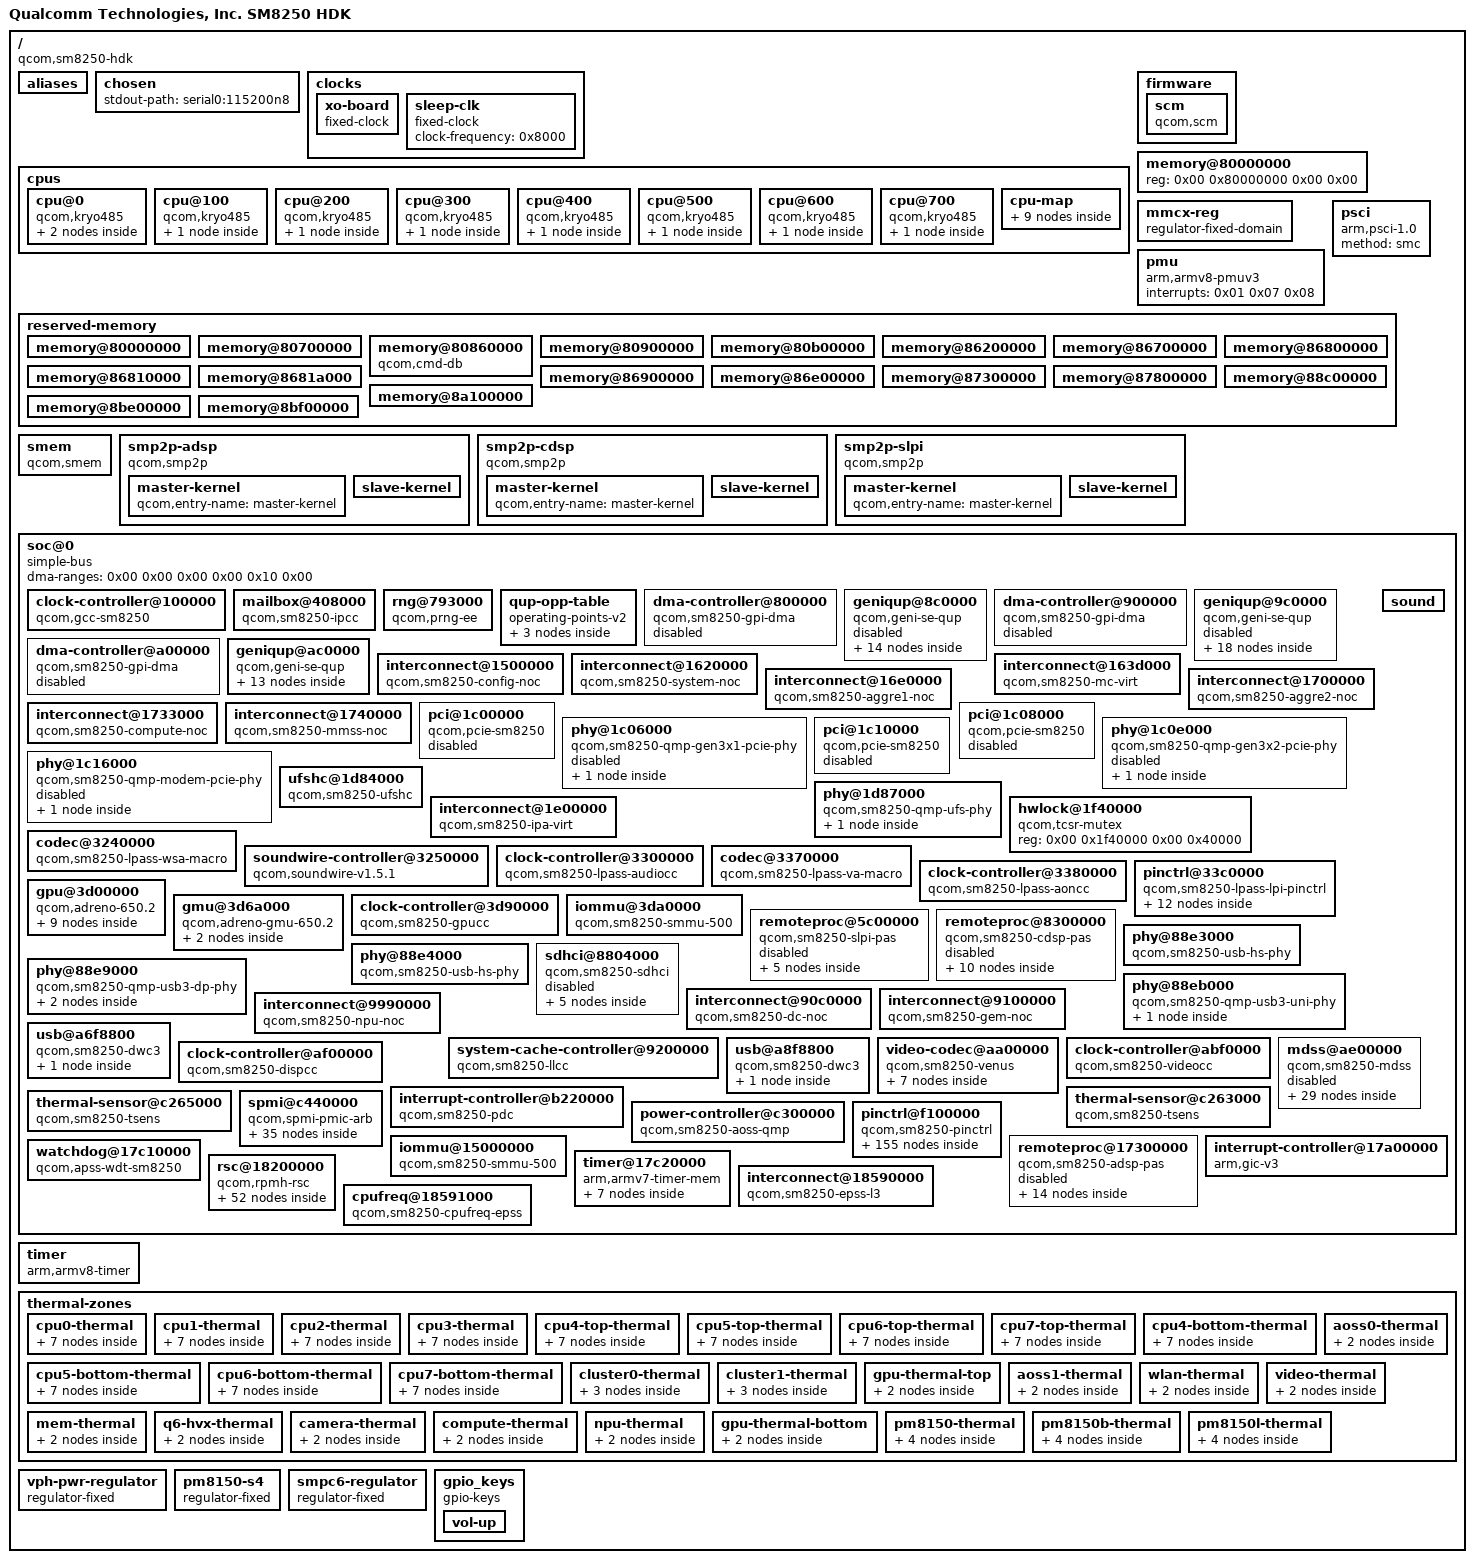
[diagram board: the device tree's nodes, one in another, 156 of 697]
/dts-v1/;

/ {
	interrupt-parent = <0x01>;
	#address-cells = <0x02>;
	#size-cells = <0x02>;
	model = "Qualcomm Technologies, Inc. SM8250 HDK";
	compatible = "qcom,sm8250-hdk\0qcom,sm8250";

	aliases {
		i2c0 = "/soc@0/geniqup@9c0000/i2c@980000";
		i2c1 = "/soc@0/geniqup@9c0000/i2c@984000";
		i2c2 = "/soc@0/geniqup@9c0000/i2c@988000";
		i2c3 = "/soc@0/geniqup@9c0000/i2c@98c000";
		i2c4 = "/soc@0/geniqup@9c0000/i2c@990000";
		i2c5 = "/soc@0/geniqup@9c0000/i2c@994000";
		i2c6 = "/soc@0/geniqup@9c0000/i2c@998000";
		i2c7 = "/soc@0/geniqup@9c0000/i2c@99c000";
		i2c8 = "/soc@0/geniqup@ac0000/i2c@a80000";
		i2c9 = "/soc@0/geniqup@ac0000/i2c@a84000";
		i2c10 = "/soc@0/geniqup@ac0000/i2c@a88000";
		i2c11 = "/soc@0/geniqup@ac0000/i2c@a8c000";
		i2c12 = "/soc@0/geniqup@ac0000/i2c@a90000";
		i2c13 = "/soc@0/geniqup@ac0000/i2c@a94000";
		i2c14 = "/soc@0/geniqup@8c0000/i2c@880000";
		i2c15 = "/soc@0/geniqup@8c0000/i2c@884000";
		i2c16 = "/soc@0/geniqup@8c0000/i2c@888000";
		i2c17 = "/soc@0/geniqup@8c0000/i2c@88c000";
		i2c18 = "/soc@0/geniqup@8c0000/i2c@890000";
		i2c19 = "/soc@0/geniqup@8c0000/i2c@894000";
		spi0 = "/soc@0/geniqup@9c0000/spi@980000";
		spi1 = "/soc@0/geniqup@9c0000/spi@984000";
		spi2 = "/soc@0/geniqup@9c0000/spi@988000";
		spi3 = "/soc@0/geniqup@9c0000/spi@98c000";
		spi4 = "/soc@0/geniqup@9c0000/spi@990000";
		spi5 = "/soc@0/geniqup@9c0000/spi@994000";
		spi6 = "/soc@0/geniqup@9c0000/spi@998000";
		spi7 = "/soc@0/geniqup@9c0000/spi@99c000";
		spi8 = "/soc@0/geniqup@ac0000/spi@a80000";
		spi9 = "/soc@0/geniqup@ac0000/spi@a84000";
		spi10 = "/soc@0/geniqup@ac0000/spi@a88000";
		spi11 = "/soc@0/geniqup@ac0000/spi@a8c000";
		spi12 = "/soc@0/geniqup@ac0000/spi@a90000";
		spi13 = "/soc@0/geniqup@ac0000/spi@a94000";
		spi14 = "/soc@0/geniqup@8c0000/spi@880000";
		spi15 = "/soc@0/geniqup@8c0000/spi@884000";
		spi16 = "/soc@0/geniqup@8c0000/spi@888000";
		spi17 = "/soc@0/geniqup@8c0000/spi@88c000";
		spi18 = "/soc@0/geniqup@8c0000/spi@890000";
		spi19 = "/soc@0/geniqup@8c0000/spi@894000";
		serial0 = "/soc@0/geniqup@ac0000/serial@a90000";
	};

	chosen {
		stdout-path = "serial0:115200n8";
	};

	clocks {

		xo-board {
			compatible = "fixed-clock";
			#clock-cells = <0x00>;
			clock-frequency = <0x249f000>;
			clock-output-names = "xo_board";
			phandle = <0x83>;
		};

		sleep-clk {
			compatible = "fixed-clock";
			clock-frequency = <0x8000>;
			#clock-cells = <0x00>;
			phandle = <0x1a>;
		};
	};

	cpus {
		#address-cells = <0x02>;
		#size-cells = <0x00>;

		cpu@0 {
			device_type = "cpu";
			compatible = "qcom,kryo485";
			reg = <0x00 0x00>;
			enable-method = "psci";
			capacity-dmips-mhz = <0x1c0>;
			dynamic-power-coefficient = <0xcd>;
			next-level-cache = <0x02>;
			qcom,freq-domain = <0x03 0x00>;
			#cooling-cells = <0x02>;
			phandle = <0x0c>;

			l2-cache {
				compatible = "cache";
				next-level-cache = <0x04>;
				phandle = <0x02>;

				l3-cache {
					compatible = "cache";
					phandle = <0x04>;
				};
			};
		};

		cpu@100 {
			device_type = "cpu";
			compatible = "qcom,kryo485";
			reg = <0x00 0x100>;
			enable-method = "psci";
			capacity-dmips-mhz = <0x1c0>;
			dynamic-power-coefficient = <0xcd>;
			next-level-cache = <0x05>;
			qcom,freq-domain = <0x03 0x00>;
			#cooling-cells = <0x02>;
			phandle = <0x0d>;

			l2-cache {
				compatible = "cache";
				next-level-cache = <0x04>;
				phandle = <0x05>;
			};
		};

		cpu@200 {
			device_type = "cpu";
			compatible = "qcom,kryo485";
			reg = <0x00 0x200>;
			enable-method = "psci";
			capacity-dmips-mhz = <0x1c0>;
			dynamic-power-coefficient = <0xcd>;
			next-level-cache = <0x06>;
			qcom,freq-domain = <0x03 0x00>;
			#cooling-cells = <0x02>;
			phandle = <0x0e>;

			l2-cache {
				compatible = "cache";
				next-level-cache = <0x04>;
				phandle = <0x06>;
			};
		};

		cpu@300 {
			device_type = "cpu";
			compatible = "qcom,kryo485";
			reg = <0x00 0x300>;
			enable-method = "psci";
			capacity-dmips-mhz = <0x1c0>;
			dynamic-power-coefficient = <0xcd>;
			next-level-cache = <0x07>;
			qcom,freq-domain = <0x03 0x00>;
			#cooling-cells = <0x02>;
			phandle = <0x0f>;

			l2-cache {
				compatible = "cache";
				next-level-cache = <0x04>;
				phandle = <0x07>;
			};
		};

		cpu@400 {
			device_type = "cpu";
			compatible = "qcom,kryo485";
			reg = <0x00 0x400>;
			enable-method = "psci";
			capacity-dmips-mhz = <0x400>;
			dynamic-power-coefficient = <0x17b>;
			next-level-cache = <0x08>;
			qcom,freq-domain = <0x03 0x01>;
			#cooling-cells = <0x02>;
			phandle = <0x10>;

			l2-cache {
				compatible = "cache";
				next-level-cache = <0x04>;
				phandle = <0x08>;
			};
		};

		cpu@500 {
			device_type = "cpu";
			compatible = "qcom,kryo485";
			reg = <0x00 0x500>;
			enable-method = "psci";
			capacity-dmips-mhz = <0x400>;
			dynamic-power-coefficient = <0x17b>;
			next-level-cache = <0x09>;
			qcom,freq-domain = <0x03 0x01>;
			#cooling-cells = <0x02>;
			phandle = <0x11>;

			l2-cache {
				compatible = "cache";
				next-level-cache = <0x04>;
				phandle = <0x09>;
			};
		};

		cpu@600 {
			device_type = "cpu";
			compatible = "qcom,kryo485";
			reg = <0x00 0x600>;
			enable-method = "psci";
			capacity-dmips-mhz = <0x400>;
			dynamic-power-coefficient = <0x17b>;
			next-level-cache = <0x0a>;
			qcom,freq-domain = <0x03 0x01>;
			#cooling-cells = <0x02>;
			phandle = <0x12>;

			l2-cache {
				compatible = "cache";
				next-level-cache = <0x04>;
				phandle = <0x0a>;
			};
		};

		cpu@700 {
			device_type = "cpu";
			compatible = "qcom,kryo485";
			reg = <0x00 0x700>;
			enable-method = "psci";
			capacity-dmips-mhz = <0x400>;
			dynamic-power-coefficient = <0x1bc>;
			next-level-cache = <0x0b>;
			qcom,freq-domain = <0x03 0x02>;
			#cooling-cells = <0x02>;
			phandle = <0x13>;

			l2-cache {
				compatible = "cache";
				next-level-cache = <0x04>;
				phandle = <0x0b>;
			};
		};

		cpu-map {

			cluster0 {

				core0 {
					cpu = <0x0c>;
				};

				core1 {
					cpu = <0x0d>;
				};

				core2 {
					cpu = <0x0e>;
				};

				core3 {
					cpu = <0x0f>;
				};

				core4 {
					cpu = <0x10>;
				};

				core5 {
					cpu = <0x11>;
				};

				core6 {
					cpu = <0x12>;
				};

				core7 {
					cpu = <0x13>;
				};
			};
		};
	};

	firmware {

		scm {
			compatible = "qcom,scm";
			#reset-cells = <0x01>;
			phandle = <0xa9>;
		};
	};

	memory@80000000 {
		device_type = "memory";
		reg = <0x00 0x80000000 0x00 0x00>;
	};

	mmcx-reg {
		compatible = "regulator-fixed-domain";
		power-domains = <0x14 0x06>;
		required-opps = <0x15>;
		regulator-name = "MMCX";
		phandle = <0x71>;
	};

	pmu {
		compatible = "arm,armv8-pmuv3";
		interrupts = <0x01 0x07 0x08>;
	};

	psci {
		compatible = "arm,psci-1.0";
		method = "smc";
	};

	reserved-memory {
		#address-cells = <0x02>;
		#size-cells = <0x02>;
		ranges;

		memory@80000000 {
			reg = <0x00 0x80000000 0x00 0x600000>;
			no-map;
			phandle = <0xaa>;
		};

		memory@80700000 {
			reg = <0x00 0x80700000 0x00 0x160000>;
			no-map;
			phandle = <0xab>;
		};

		memory@80860000 {
			compatible = "qcom,cmd-db";
			reg = <0x00 0x80860000 0x00 0x20000>;
			no-map;
			phandle = <0xac>;
		};

		memory@80900000 {
			reg = <0x00 0x80900000 0x00 0x200000>;
			no-map;
			phandle = <0x16>;
		};

		memory@80b00000 {
			reg = <0x00 0x80b00000 0x00 0x5300000>;
			no-map;
			phandle = <0xad>;
		};

		memory@86200000 {
			reg = <0x00 0x86200000 0x00 0x500000>;
			no-map;
			phandle = <0xae>;
		};

		memory@86700000 {
			reg = <0x00 0x86700000 0x00 0x100000>;
			no-map;
			phandle = <0xaf>;
		};

		memory@86800000 {
			reg = <0x00 0x86800000 0x00 0x10000>;
			no-map;
			phandle = <0xb0>;
		};

		memory@86810000 {
			reg = <0x00 0x86810000 0x00 0xa000>;
			no-map;
			phandle = <0xb1>;
		};

		memory@8681a000 {
			reg = <0x00 0x8681a000 0x00 0x2000>;
			no-map;
			phandle = <0x55>;
		};

		memory@86900000 {
			reg = <0x00 0x86900000 0x00 0x500000>;
			no-map;
			phandle = <0xb2>;
		};

		memory@86e00000 {
			reg = <0x00 0x86e00000 0x00 0x500000>;
			no-map;
			phandle = <0x6f>;
		};

		memory@87300000 {
			reg = <0x00 0x87300000 0x00 0x500000>;
			no-map;
			phandle = <0xb3>;
		};

		memory@87800000 {
			reg = <0x00 0x87800000 0x00 0x1400000>;
			no-map;
			phandle = <0x5e>;
		};

		memory@88c00000 {
			reg = <0x00 0x88c00000 0x00 0x1500000>;
			no-map;
			phandle = <0x5b>;
		};

		memory@8a100000 {
			reg = <0x00 0x8a100000 0x00 0x1d00000>;
			no-map;
			phandle = <0x81>;
		};

		memory@8be00000 {
			reg = <0x00 0x8be00000 0x00 0x100000>;
			no-map;
			phandle = <0xb4>;
		};

		memory@8bf00000 {
			reg = <0x00 0x8bf00000 0x00 0x4600000>;
			no-map;
			phandle = <0xb5>;
		};
	};

	smem {
		compatible = "qcom,smem";
		memory-region = <0x16>;
		hwlocks = <0x17 0x03>;
	};

	smp2p-adsp {
		compatible = "qcom,smp2p";
		qcom,smem = <0x1bb 0x1ad>;
		interrupts-extended = <0x18 0x03 0x02 0x01>;
		mboxes = <0x18 0x03 0x02>;
		qcom,local-pid = <0x00>;
		qcom,remote-pid = <0x02>;

		master-kernel {
			qcom,entry-name = "master-kernel";
			#qcom,smem-state-cells = <0x01>;
			phandle = <0x82>;
		};

		slave-kernel {
			qcom,entry-name = "slave-kernel";
			interrupt-controller;
			#interrupt-cells = <0x02>;
			phandle = <0x80>;
		};
	};

	smp2p-cdsp {
		compatible = "qcom,smp2p";
		qcom,smem = <0x5e 0x1b0>;
		interrupts-extended = <0x18 0x06 0x02 0x01>;
		mboxes = <0x18 0x06 0x02>;
		qcom,local-pid = <0x00>;
		qcom,remote-pid = <0x05>;

		master-kernel {
			qcom,entry-name = "master-kernel";
			#qcom,smem-state-cells = <0x01>;
			phandle = <0x5f>;
		};

		slave-kernel {
			qcom,entry-name = "slave-kernel";
			interrupt-controller;
			#interrupt-cells = <0x02>;
			phandle = <0x5d>;
		};
	};

	smp2p-slpi {
		compatible = "qcom,smp2p";
		qcom,smem = <0x1e1 0x1ae>;
		interrupts-extended = <0x18 0x04 0x02 0x01>;
		mboxes = <0x18 0x04 0x02>;
		qcom,local-pid = <0x00>;
		qcom,remote-pid = <0x03>;

		master-kernel {
			qcom,entry-name = "master-kernel";
			#qcom,smem-state-cells = <0x01>;
			phandle = <0x5c>;
		};

		slave-kernel {
			qcom,entry-name = "slave-kernel";
			interrupt-controller;
			#interrupt-cells = <0x02>;
			phandle = <0x59>;
		};
	};

	soc@0 {
		#address-cells = <0x02>;
		#size-cells = <0x02>;
		ranges = <0x00 0x00 0x00 0x00 0x10 0x00>;
		dma-ranges = <0x00 0x00 0x00 0x00 0x10 0x00>;
		compatible = "simple-bus";
		phandle = <0xb6>;

		clock-controller@100000 {
			compatible = "qcom,gcc-sm8250";
			reg = <0x00 0x100000 0x00 0x1f0000>;
			#clock-cells = <0x01>;
			#reset-cells = <0x01>;
			#power-domain-cells = <0x01>;
			clock-names = "bi_tcxo\0bi_tcxo_ao\0sleep_clk";
			clocks = <0x19 0x00 0x19 0x01 0x1a>;
			phandle = <0x1b>;
		};

		mailbox@408000 {
			compatible = "qcom,sm8250-ipcc\0qcom,ipcc";
			reg = <0x00 0x408000 0x00 0x1000>;
			interrupts = <0x00 0xe5 0x04>;
			interrupt-controller;
			#interrupt-cells = <0x03>;
			#mbox-cells = <0x02>;
			phandle = <0x18>;
		};

		rng@793000 {
			compatible = "qcom,prng-ee";
			reg = <0x00 0x793000 0x00 0x1000>;
			clocks = <0x1b 0x4f>;
			clock-names = "core";
			phandle = <0xb7>;
		};

		qup-opp-table {
			compatible = "operating-points-v2";
			phandle = <0x21>;

			opp-50000000 {
				opp-hz = <0x00 0x2faf080>;
				required-opps = <0x1c>;
			};

			opp-75000000 {
				opp-hz = <0x00 0x47868c0>;
				required-opps = <0x15>;
			};

			opp-120000000 {
				opp-hz = <0x00 0x7270e00>;
				required-opps = <0x1d>;
			};
		};

		dma-controller@800000 {
			compatible = "qcom,sm8250-gpi-dma";
			reg = <0x00 0x800000 0x00 0x70000>;
			interrupts = <0x00 0x24c 0x04 0x00 0x24d 0x04 0x00 0x24e 0x04 0x00 0x24f 0x04 0x00 0x250 0x04 0x00 0x251 0x04 0x00 0x252 0x04 0x00 0x253 0x04 0x00 0x254 0x04 0x00 0x255 0x04>;
			dma-channels = <0x0a>;
			dma-channel-mask = <0x3f>;
			iommus = <0x1e 0x76 0x00>;
			#dma-cells = <0x03>;
			status = "disabled";
			phandle = <0x20>;
		};

		geniqup@8c0000 {
			compatible = "qcom,geni-se-qup";
			reg = <0x00 0x8c0000 0x00 0x6000>;
			clock-names = "m-ahb\0s-ahb";
			clocks = <0x1b 0x87 0x1b 0x88>;
			#address-cells = <0x02>;
			#size-cells = <0x02>;
			iommus = <0x1e 0x63 0x00>;
			ranges;
			status = "disabled";
			phandle = <0xb8>;

			i2c@880000 {
				compatible = "qcom,geni-i2c";
				reg = <0x00 0x880000 0x00 0x4000>;
				clock-names = "se";
				clocks = <0x1b 0x77>;
				pinctrl-names = "default";
				pinctrl-0 = <0x1f>;
				interrupts = <0x00 0x175 0x04>;
				dmas = <0x20 0x00 0x00 0x03 0x20 0x01 0x00 0x03>;
				dma-names = "tx\0rx";
				#address-cells = <0x01>;
				#size-cells = <0x00>;
				status = "disabled";
				phandle = <0xb9>;
			};

			spi@880000 {
				compatible = "qcom,geni-spi";
				reg = <0x00 0x880000 0x00 0x4000>;
				clock-names = "se";
				clocks = <0x1b 0x77>;
				interrupts = <0x00 0x175 0x04>;
				dmas = <0x20 0x00 0x00 0x01 0x20 0x01 0x00 0x01>;
				dma-names = "tx\0rx";
				power-domains = <0x14 0x00>;
				operating-points-v2 = <0x21>;
				#address-cells = <0x01>;
				#size-cells = <0x00>;
				status = "disabled";
				phandle = <0xba>;
			};

			i2c@884000 {
				compatible = "qcom,geni-i2c";
				reg = <0x00 0x884000 0x00 0x4000>;
				clock-names = "se";
				clocks = <0x1b 0x79>;
				pinctrl-names = "default";
				pinctrl-0 = <0x22>;
				interrupts = <0x00 0x247 0x04>;
				dmas = <0x20 0x00 0x01 0x03 0x20 0x01 0x01 0x03>;
				dma-names = "tx\0rx";
				#address-cells = <0x01>;
				#size-cells = <0x00>;
				status = "disabled";
				phandle = <0xbb>;
			};

			spi@884000 {
				compatible = "qcom,geni-spi";
				reg = <0x00 0x884000 0x00 0x4000>;
				clock-names = "se";
				clocks = <0x1b 0x79>;
				interrupts = <0x00 0x247 0x04>;
				dmas = <0x20 0x00 0x01 0x01 0x20 0x01 0x01 0x01>;
				dma-names = "tx\0rx";
				power-domains = <0x14 0x00>;
				operating-points-v2 = <0x21>;
				#address-cells = <0x01>;
				#size-cells = <0x00>;
				status = "disabled";
				phandle = <0xbc>;
			};

			i2c@888000 {
				compatible = "qcom,geni-i2c";
				reg = <0x00 0x888000 0x00 0x4000>;
				clock-names = "se";
				clocks = <0x1b 0x7b>;
				pinctrl-names = "default";
				pinctrl-0 = <0x23>;
				interrupts = <0x00 0x248 0x04>;
				dmas = <0x20 0x00 0x02 0x03 0x20 0x01 0x02 0x03>;
				dma-names = "tx\0rx";
				#address-cells = <0x01>;
				#size-cells = <0x00>;
				status = "disabled";
				phandle = <0xbd>;
			};

			spi@888000 {
				compatible = "qcom,geni-spi";
				reg = <0x00 0x888000 0x00 0x4000>;
				clock-names = "se";
				clocks = <0x1b 0x7b>;
				interrupts = <0x00 0x248 0x04>;
				dmas = <0x20 0x00 0x02 0x01 0x20 0x01 0x02 0x01>;
				dma-names = "tx\0rx";
				power-domains = <0x14 0x00>;
				operating-points-v2 = <0x21>;
				#address-cells = <0x01>;
				#size-cells = <0x00>;
				status = "disabled";
				phandle = <0xbe>;
			};

			i2c@88c000 {
				compatible = "qcom,geni-i2c";
				reg = <0x00 0x88c000 0x00 0x4000>;
				clock-names = "se";
				clocks = <0x1b 0x7d>;
				pinctrl-names = "default";
				pinctrl-0 = <0x24>;
				interrupts = <0x00 0x249 0x04>;
				dmas = <0x20 0x00 0x03 0x03 0x20 0x01 0x03 0x03>;
				dma-names = "tx\0rx";
				#address-cells = <0x01>;
				#size-cells = <0x00>;
				status = "disabled";
				phandle = <0xbf>;
			};

			spi@88c000 {
				compatible = "qcom,geni-spi";
				reg = <0x00 0x88c000 0x00 0x4000>;
				clock-names = "se";
				clocks = <0x1b 0x7d>;
				interrupts = <0x00 0x249 0x04>;
				dmas = <0x20 0x00 0x03 0x01 0x20 0x01 0x03 0x01>;
				dma-names = "tx\0rx";
				power-domains = <0x14 0x00>;
				operating-points-v2 = <0x21>;
				#address-cells = <0x01>;
				#size-cells = <0x00>;
				status = "disabled";
				phandle = <0xc0>;
			};

			serial@88c000 {
				compatible = "qcom,geni-uart";
				reg = <0x00 0x88c000 0x00 0x4000>;
				clock-names = "se";
				clocks = <0x1b 0x7d>;
				pinctrl-names = "default";
				pinctrl-0 = <0x25>;
				interrupts = <0x00 0x249 0x04>;
				power-domains = <0x14 0x00>;
				operating-points-v2 = <0x21>;
				status = "disabled";
				phandle = <0xc1>;
			};

			i2c@890000 {
				compatible = "qcom,geni-i2c";
				reg = <0x00 0x890000 0x00 0x4000>;
				clock-names = "se";
				clocks = <0x1b 0x7f>;
				pinctrl-names = "default";
				pinctrl-0 = <0x26>;
				interrupts = <0x00 0x24a 0x04>;
				dmas = <0x20 0x00 0x04 0x03 0x20 0x01 0x04 0x03>;
				dma-names = "tx\0rx";
				#address-cells = <0x01>;
				#size-cells = <0x00>;
				status = "disabled";
				phandle = <0xc2>;
			};

			spi@890000 {
				compatible = "qcom,geni-spi";
				reg = <0x00 0x890000 0x00 0x4000>;
				clock-names = "se";
				clocks = <0x1b 0x7f>;
				interrupts = <0x00 0x24a 0x04>;
				dmas = <0x20 0x00 0x04 0x01 0x20 0x01 0x04 0x01>;
				dma-names = "tx\0rx";
				power-domains = <0x14 0x00>;
				operating-points-v2 = <0x21>;
				#address-cells = <0x01>;
				#size-cells = <0x00>;
				status = "disabled";
				phandle = <0xc3>;
			};

			serial@890000 {
				compatible = "qcom,geni-uart";
				reg = <0x00 0x890000 0x00 0x4000>;
				clock-names = "se";
				clocks = <0x1b 0x7f>;
				pinctrl-names = "default";
				pinctrl-0 = <0x27>;
				interrupts = <0x00 0x24a 0x04>;
				power-domains = <0x14 0x00>;
				operating-points-v2 = <0x21>;
				status = "disabled";
				phandle = <0xc4>;
			};

			i2c@894000 {
				compatible = "qcom,geni-i2c";
				reg = <0x00 0x894000 0x00 0x4000>;
				clock-names = "se";
				clocks = <0x1b 0x81>;
				pinctrl-names = "default";
				pinctrl-0 = <0x28>;
				interrupts = <0x00 0x24b 0x04>;
				dmas = <0x20 0x00 0x05 0x03 0x20 0x01 0x05 0x03>;
				dma-names = "tx\0rx";
				#address-cells = <0x01>;
				#size-cells = <0x00>;
				status = "disabled";
				phandle = <0xc5>;
			};

			spi@894000 {
				compatible = "qcom,geni-spi";
				reg = <0x00 0x894000 0x00 0x4000>;
				clock-names = "se";
				clocks = <0x1b 0x81>;
				interrupts = <0x00 0x24b 0x04>;
				dmas = <0x20 0x00 0x05 0x01 0x20 0x01 0x05 0x01>;
				dma-names = "tx\0rx";
				power-domains = <0x14 0x00>;
				operating-points-v2 = <0x21>;
				#address-cells = <0x01>;
				#size-cells = <0x00>;
				status = "disabled";
				phandle = <0xc6>;
			};
		};

		dma-controller@900000 {
			compatible = "qcom,sm8250-gpi-dma";
			reg = <0x00 0x900000 0x00 0x70000>;
			interrupts = <0x00 0xf4 0x04 0x00 0xf5 0x04 0x00 0xf6 0x04 0x00 0xf7 0x04 0x00 0xf8 0x04 0x00 0xf9 0x04 0x00 0xfa 0x04 0x00 0xfb 0x04 0x00 0xfc 0x04 0x00 0xfd 0x04 0x00 0xfe 0x04 0x00 0xff 0x04 0x00 0x100 0x04>;
			dma-channels = <0x0f>;
			dma-channel-mask = <0x7ff>;
			iommus = <0x1e 0x5b6 0x00>;
			#dma-cells = <0x03>;
			status = "disabled";
			phandle = <0x2a>;
		};

		geniqup@9c0000 {
			compatible = "qcom,geni-se-qup";
			reg = <0x00 0x9c0000 0x00 0x6000>;
			clock-names = "m-ahb\0s-ahb";
			clocks = <0x1b 0x83 0x1b 0x84>;
			#address-cells = <0x02>;
			#size-cells = <0x02>;
			iommus = <0x1e 0x5a3 0x00>;
			ranges;
			status = "disabled";
			phandle = <0xc7>;

			i2c@980000 {
				compatible = "qcom,geni-i2c";
				reg = <0x00 0x980000 0x00 0x4000>;
				clock-names = "se";
				clocks = <0x1b 0x57>;
				pinctrl-names = "default";
				pinctrl-0 = <0x29>;
				interrupts = <0x00 0x259 0x04>;
				dmas = <0x2a 0x00 0x00 0x03 0x2a 0x01 0x00 0x03>;
				dma-names = "tx\0rx";
				#address-cells = <0x01>;
				#size-cells = <0x00>;
				status = "disabled";
				phandle = <0xc8>;
			};

			spi@980000 {
				compatible = "qcom,geni-spi";
				reg = <0x00 0x980000 0x00 0x4000>;
				clock-names = "se";
				clocks = <0x1b 0x57>;
				interrupts = <0x00 0x259 0x04>;
				dmas = <0x2a 0x00 0x00 0x01 0x2a 0x01 0x00 0x01>;
				dma-names = "tx\0rx";
				power-domains = <0x14 0x00>;
				operating-points-v2 = <0x21>;
				#address-cells = <0x01>;
				#size-cells = <0x00>;
				status = "disabled";
				phandle = <0xc9>;
			};

			i2c@984000 {
				compatible = "qcom,geni-i2c";
				reg = <0x00 0x984000 0x00 0x4000>;
				clock-names = "se";
				clocks = <0x1b 0x59>;
				pinctrl-names = "default";
				pinctrl-0 = <0x2b>;
				interrupts = <0x00 0x25a 0x04>;
				dmas = <0x2a 0x00 0x01 0x03 0x2a 0x01 0x01 0x03>;
				dma-names = "tx\0rx";
				#address-cells = <0x01>;
				#size-cells = <0x00>;
				status = "disabled";
				phandle = <0xca>;
			};

			spi@984000 {
				compatible = "qcom,geni-spi";
				reg = <0x00 0x984000 0x00 0x4000>;
				clock-names = "se";
				clocks = <0x1b 0x59>;
				interrupts = <0x00 0x25a 0x04>;
				dmas = <0x2a 0x00 0x01 0x01 0x2a 0x01 0x01 0x01>;
				dma-names = "tx\0rx";
				power-domains = <0x14 0x00>;
				operating-points-v2 = <0x21>;
				#address-cells = <0x01>;
				#size-cells = <0x00>;
				status = "disabled";
				phandle = <0xcb>;
			};

			i2c@988000 {
				compatible = "qcom,geni-i2c";
				reg = <0x00 0x988000 0x00 0x4000>;
				clock-names = "se";
				clocks = <0x1b 0x5b>;
				pinctrl-names = "default";
				pinctrl-0 = <0x2c>;
				interrupts = <0x00 0x25b 0x04>;
				dmas = <0x2a 0x00 0x02 0x03 0x2a 0x01 0x02 0x03>;
				dma-names = "tx\0rx";
				#address-cells = <0x01>;
				#size-cells = <0x00>;
				status = "disabled";
				phandle = <0xcc>;
			};

			spi@988000 {
				compatible = "qcom,geni-spi";
				reg = <0x00 0x988000 0x00 0x4000>;
				clock-names = "se";
				clocks = <0x1b 0x5b>;
				interrupts = <0x00 0x25b 0x04>;
				dmas = <0x2a 0x00 0x02 0x01 0x2a 0x01 0x02 0x01>;
				dma-names = "tx\0rx";
				power-domains = <0x14 0x00>;
				operating-points-v2 = <0x21>;
				#address-cells = <0x01>;
				#size-cells = <0x00>;
				status = "disabled";
				phandle = <0xcd>;
			};

			serial@988000 {
				compatible = "qcom,geni-debug-uart";
				reg = <0x00 0x988000 0x00 0x4000>;
				clock-names = "se";
				clocks = <0x1b 0x5b>;
				pinctrl-names = "default";
				pinctrl-0 = <0x2d>;
				interrupts = <0x00 0x25b 0x04>;
				power-domains = <0x14 0x00>;
				operating-points-v2 = <0x21>;
				status = "disabled";
				phandle = <0xce>;
			};

			i2c@98c000 {
				compatible = "qcom,geni-i2c";
				reg = <0x00 0x98c000 0x00 0x4000>;
				clock-names = "se";
				clocks = <0x1b 0x5d>;
				pinctrl-names = "default";
				pinctrl-0 = <0x2e>;
				interrupts = <0x00 0x25c 0x04>;
				dmas = <0x2a 0x00 0x03 0x03 0x2a 0x01 0x03 0x03>;
				dma-names = "tx\0rx";
				#address-cells = <0x01>;
				#size-cells = <0x00>;
				status = "disabled";
				phandle = <0xcf>;
			};

			spi@98c000 {
				compatible = "qcom,geni-spi";
				reg = <0x00 0x98c000 0x00 0x4000>;
				clock-names = "se";
				clocks = <0x1b 0x5d>;
				interrupts = <0x00 0x25c 0x04>;
				dmas = <0x2a 0x00 0x03 0x01 0x2a 0x01 0x03 0x01>;
				dma-names = "tx\0rx";
				power-domains = <0x14 0x00>;
				operating-points-v2 = <0x21>;
				#address-cells = <0x01>;
				#size-cells = <0x00>;
				status = "disabled";
				phandle = <0xd0>;
			};

			i2c@990000 {
				compatible = "qcom,geni-i2c";
				reg = <0x00 0x990000 0x00 0x4000>;
				clock-names = "se";
				clocks = <0x1b 0x5f>;
				pinctrl-names = "default";
				pinctrl-0 = <0x2f>;
				interrupts = <0x00 0x25d 0x04>;
				dmas = <0x2a 0x00 0x04 0x03 0x2a 0x01 0x04 0x03>;
				dma-names = "tx\0rx";
				#address-cells = <0x01>;
				#size-cells = <0x00>;
				status = "disabled";
				phandle = <0xd1>;
			};

			spi@990000 {
				compatible = "qcom,geni-spi";
				reg = <0x00 0x990000 0x00 0x4000>;
				clock-names = "se";
				clocks = <0x1b 0x5f>;
				interrupts = <0x00 0x25d 0x04>;
				dmas = <0x2a 0x00 0x04 0x01 0x2a 0x01 0x04 0x01>;
				dma-names = "tx\0rx";
				power-domains = <0x14 0x00>;
				operating-points-v2 = <0x21>;
				#address-cells = <0x01>;
				#size-cells = <0x00>;
				status = "disabled";
				phandle = <0xd2>;
			};

			i2c@994000 {
				compatible = "qcom,geni-i2c";
				reg = <0x00 0x994000 0x00 0x4000>;
				clock-names = "se";
				clocks = <0x1b 0x61>;
				pinctrl-names = "default";
				pinctrl-0 = <0x30>;
				interrupts = <0x00 0x25e 0x04>;
				dmas = <0x2a 0x00 0x05 0x03 0x2a 0x01 0x05 0x03>;
				dma-names = "tx\0rx";
				#address-cells = <0x01>;
				#size-cells = <0x00>;
				status = "disabled";
				phandle = <0xd3>;
			};

			spi@994000 {
				compatible = "qcom,geni-spi";
				reg = <0x00 0x994000 0x00 0x4000>;
				clock-names = "se";
				clocks = <0x1b 0x61>;
				interrupts = <0x00 0x25e 0x04>;
				dmas = <0x2a 0x00 0x05 0x01 0x2a 0x01 0x05 0x01>;
				dma-names = "tx\0rx";
				power-domains = <0x14 0x00>;
				operating-points-v2 = <0x21>;
				#address-cells = <0x01>;
				#size-cells = <0x00>;
				status = "disabled";
				phandle = <0xd4>;
			};

			i2c@998000 {
				compatible = "qcom,geni-i2c";
				reg = <0x00 0x998000 0x00 0x4000>;
				clock-names = "se";
				clocks = <0x1b 0x63>;
				pinctrl-names = "default";
				pinctrl-0 = <0x31>;
				interrupts = <0x00 0x25f 0x04>;
				dmas = <0x2a 0x00 0x06 0x03 0x2a 0x01 0x06 0x03>;
				dma-names = "tx\0rx";
				#address-cells = <0x01>;
				#size-cells = <0x00>;
				status = "disabled";
				phandle = <0xd5>;
			};

			spi@998000 {
				compatible = "qcom,geni-spi";
				reg = <0x00 0x998000 0x00 0x4000>;
				clock-names = "se";
				clocks = <0x1b 0x63>;
				interrupts = <0x00 0x25f 0x04>;
				dmas = <0x2a 0x00 0x06 0x01 0x2a 0x01 0x06 0x01>;
				dma-names = "tx\0rx";
				power-domains = <0x14 0x00>;
				operating-points-v2 = <0x21>;
				#address-cells = <0x01>;
				#size-cells = <0x00>;
				status = "disabled";
				phandle = <0xd6>;
			};

			serial@998000 {
				compatible = "qcom,geni-uart";
				reg = <0x00 0x998000 0x00 0x4000>;
				clock-names = "se";
				clocks = <0x1b 0x63>;
				pinctrl-names = "default";
				pinctrl-0 = <0x32>;
				interrupts = <0x00 0x25f 0x04>;
				power-domains = <0x14 0x00>;
				operating-points-v2 = <0x21>;
				status = "disabled";
				phandle = <0xd7>;
			};

			i2c@99c000 {
				compatible = "qcom,geni-i2c";
				reg = <0x00 0x99c000 0x00 0x4000>;
				clock-names = "se";
				clocks = <0x1b 0x65>;
				pinctrl-names = "default";
				pinctrl-0 = <0x33>;
				interrupts = <0x00 0x260 0x04>;
				dmas = <0x2a 0x00 0x07 0x03 0x2a 0x01 0x07 0x03>;
				dma-names = "tx\0rx";
				#address-cells = <0x01>;
				#size-cells = <0x00>;
				status = "disabled";
				phandle = <0xd8>;
			};

			spi@99c000 {
				compatible = "qcom,geni-spi";
				reg = <0x00 0x99c000 0x00 0x4000>;
				clock-names = "se";
				clocks = <0x1b 0x65>;
				interrupts = <0x00 0x260 0x04>;
				dmas = <0x2a 0x00 0x07 0x01 0x2a 0x01 0x07 0x01>;
				dma-names = "tx\0rx";
				power-domains = <0x14 0x00>;
				operating-points-v2 = <0x21>;
				#address-cells = <0x01>;
				#size-cells = <0x00>;
				status = "disabled";
				phandle = <0xd9>;
			};
		};

		dma-controller@a00000 {
			compatible = "qcom,sm8250-gpi-dma";
			reg = <0x00 0xa00000 0x00 0x70000>;
			interrupts = <0x00 0x117 0x04 0x00 0x118 0x04 0x00 0x119 0x04 0x00 0x11a 0x04 0x00 0x11b 0x04 0x00 0x11c 0x04 0x00 0x125 0x04 0x00 0x126 0x04 0x00 0x127 0x04 0x00 0x128 0x04>;
			dma-channels = <0x0a>;
			dma-channel-mask = <0x3f>;
			iommus = <0x1e 0x56 0x00>;
			#dma-cells = <0x03>;
			status = "disabled";
			phandle = <0x35>;
		};

		geniqup@ac0000 {
			compatible = "qcom,geni-se-qup";
			reg = <0x00 0xac0000 0x00 0x6000>;
			clock-names = "m-ahb\0s-ahb";
			clocks = <0x1b 0x85 0x1b 0x86>;
			#address-cells = <0x02>;
			#size-cells = <0x02>;
			iommus = <0x1e 0x43 0x00>;
			ranges;
			status = "okay";
			phandle = <0xda>;

			i2c@a80000 {
				compatible = "qcom,geni-i2c";
				reg = <0x00 0xa80000 0x00 0x4000>;
				clock-names = "se";
				clocks = <0x1b 0x69>;
				pinctrl-names = "default";
				pinctrl-0 = <0x34>;
				interrupts = <0x00 0x161 0x04>;
				dmas = <0x35 0x00 0x00 0x03 0x35 0x01 0x00 0x03>;
				dma-names = "tx\0rx";
				#address-cells = <0x01>;
				#size-cells = <0x00>;
				status = "disabled";
				phandle = <0xdb>;
			};

			spi@a80000 {
				compatible = "qcom,geni-spi";
				reg = <0x00 0xa80000 0x00 0x4000>;
				clock-names = "se";
				clocks = <0x1b 0x69>;
				interrupts = <0x00 0x161 0x04>;
				dmas = <0x35 0x00 0x00 0x01 0x35 0x01 0x00 0x01>;
				dma-names = "tx\0rx";
				power-domains = <0x14 0x00>;
				operating-points-v2 = <0x21>;
				#address-cells = <0x01>;
				#size-cells = <0x00>;
				status = "disabled";
				phandle = <0xdc>;
			};

			i2c@a84000 {
				compatible = "qcom,geni-i2c";
				reg = <0x00 0xa84000 0x00 0x4000>;
				clock-names = "se";
				clocks = <0x1b 0x6b>;
				pinctrl-names = "default";
				pinctrl-0 = <0x36>;
				interrupts = <0x00 0x162 0x04>;
				dmas = <0x35 0x00 0x01 0x03 0x35 0x01 0x01 0x03>;
				dma-names = "tx\0rx";
				#address-cells = <0x01>;
				#size-cells = <0x00>;
				status = "disabled";
				phandle = <0xdd>;
			};

			spi@a84000 {
				compatible = "qcom,geni-spi";
				reg = <0x00 0xa84000 0x00 0x4000>;
				clock-names = "se";
				clocks = <0x1b 0x6b>;
				interrupts = <0x00 0x162 0x04>;
				dmas = <0x35 0x00 0x01 0x01 0x35 0x01 0x01 0x01>;
				dma-names = "tx\0rx";
				power-domains = <0x14 0x00>;
				operating-points-v2 = <0x21>;
				#address-cells = <0x01>;
				#size-cells = <0x00>;
				status = "disabled";
				phandle = <0xde>;
			};

			i2c@a88000 {
				compatible = "qcom,geni-i2c";
				reg = <0x00 0xa88000 0x00 0x4000>;
				clock-names = "se";
				clocks = <0x1b 0x6d>;
				pinctrl-names = "default";
				pinctrl-0 = <0x37>;
				interrupts = <0x00 0x163 0x04>;
				dmas = <0x35 0x00 0x02 0x03 0x35 0x01 0x02 0x03>;
				dma-names = "tx\0rx";
				#address-cells = <0x01>;
				#size-cells = <0x00>;
				status = "disabled";
				phandle = <0xdf>;
			};

			spi@a88000 {
				compatible = "qcom,geni-spi";
				reg = <0x00 0xa88000 0x00 0x4000>;
				clock-names = "se";
				clocks = <0x1b 0x6d>;
				interrupts = <0x00 0x163 0x04>;
				dmas = <0x35 0x00 0x02 0x01 0x35 0x01 0x02 0x01>;
				dma-names = "tx\0rx";
				power-domains = <0x14 0x00>;
				operating-points-v2 = <0x21>;
				#address-cells = <0x01>;
				#size-cells = <0x00>;
				status = "disabled";
				phandle = <0xe0>;
			};

			i2c@a8c000 {
				compatible = "qcom,geni-i2c";
				reg = <0x00 0xa8c000 0x00 0x4000>;
				clock-names = "se";
				clocks = <0x1b 0x6f>;
				pinctrl-names = "default";
				pinctrl-0 = <0x38>;
				interrupts = <0x00 0x164 0x04>;
				dmas = <0x35 0x00 0x03 0x03 0x35 0x01 0x03 0x03>;
				dma-names = "tx\0rx";
				#address-cells = <0x01>;
				#size-cells = <0x00>;
				status = "disabled";
				phandle = <0xe1>;
			};

			spi@a8c000 {
				compatible = "qcom,geni-spi";
				reg = <0x00 0xa8c000 0x00 0x4000>;
				clock-names = "se";
				clocks = <0x1b 0x6f>;
				interrupts = <0x00 0x164 0x04>;
				dmas = <0x35 0x00 0x03 0x01 0x35 0x01 0x03 0x01>;
				dma-names = "tx\0rx";
				power-domains = <0x14 0x00>;
				operating-points-v2 = <0x21>;
				#address-cells = <0x01>;
				#size-cells = <0x00>;
				status = "disabled";
				phandle = <0xe2>;
			};

			i2c@a90000 {
				compatible = "qcom,geni-i2c";
				reg = <0x00 0xa90000 0x00 0x4000>;
				clock-names = "se";
				clocks = <0x1b 0x71>;
				pinctrl-names = "default";
				pinctrl-0 = <0x39>;
				interrupts = <0x00 0x165 0x04>;
				dmas = <0x35 0x00 0x04 0x03 0x35 0x01 0x04 0x03>;
				dma-names = "tx\0rx";
				#address-cells = <0x01>;
				#size-cells = <0x00>;
				status = "disabled";
				phandle = <0xe3>;
			};

			spi@a90000 {
				compatible = "qcom,geni-spi";
				reg = <0x00 0xa90000 0x00 0x4000>;
				clock-names = "se";
				clocks = <0x1b 0x71>;
				interrupts = <0x00 0x165 0x04>;
				dmas = <0x35 0x00 0x04 0x01 0x35 0x01 0x04 0x01>;
				dma-names = "tx\0rx";
				power-domains = <0x14 0x00>;
				operating-points-v2 = <0x21>;
				#address-cells = <0x01>;
				#size-cells = <0x00>;
				status = "disabled";
				phandle = <0xe4>;
			};

			serial@a90000 {
				compatible = "qcom,geni-debug-uart";
				reg = <0x00 0xa90000 0x00 0x4000>;
				clock-names = "se";
				clocks = <0x1b 0x71>;
				pinctrl-names = "default";
				pinctrl-0 = <0x3a>;
				interrupts = <0x00 0x165 0x04>;
				power-domains = <0x14 0x00>;
				operating-points-v2 = <0x21>;
				status = "okay";
				phandle = <0xe5>;
			};

			i2c@a94000 {
				compatible = "qcom,geni-i2c";
				reg = <0x00 0xa94000 0x00 0x4000>;
				clock-names = "se";
				clocks = <0x1b 0x73>;
				pinctrl-names = "default";
				pinctrl-0 = <0x3b>;
				interrupts = <0x00 0x166 0x04>;
				dmas = <0x35 0x00 0x05 0x03 0x35 0x01 0x05 0x03>;
				dma-names = "tx\0rx";
				#address-cells = <0x01>;
				#size-cells = <0x00>;
				status = "disabled";
				phandle = <0xe6>;
			};

			spi@a94000 {
				compatible = "qcom,geni-spi";
				reg = <0x00 0xa94000 0x00 0x4000>;
				clock-names = "se";
				clocks = <0x1b 0x73>;
				interrupts = <0x00 0x166 0x04>;
				dmas = <0x35 0x00 0x05 0x01 0x35 0x01 0x05 0x01>;
				dma-names = "tx\0rx";
				power-domains = <0x14 0x00>;
				operating-points-v2 = <0x21>;
				#address-cells = <0x01>;
				#size-cells = <0x00>;
				status = "disabled";
				phandle = <0xe7>;
			};
		};

		interconnect@1500000 {
			compatible = "qcom,sm8250-config-noc";
			reg = <0x00 0x1500000 0x00 0xa580>;
			#interconnect-cells = <0x01>;
			qcom,bcm-voters = <0x3c>;
			phandle = <0x6c>;
		};

		interconnect@1620000 {
			compatible = "qcom,sm8250-system-noc";
			reg = <0x00 0x1620000 0x00 0x1c200>;
			#interconnect-cells = <0x01>;
			qcom,bcm-voters = <0x3c>;
			phandle = <0xe8>;
		};

		interconnect@163d000 {
			compatible = "qcom,sm8250-mc-virt";
			reg = <0x00 0x163d000 0x00 0x1000>;
			#interconnect-cells = <0x01>;
			qcom,bcm-voters = <0x3c>;
			phandle = <0x6e>;
		};

		interconnect@16e0000 {
			compatible = "qcom,sm8250-aggre1-noc";
			reg = <0x00 0x16e0000 0x00 0x1f180>;
			#interconnect-cells = <0x01>;
			qcom,bcm-voters = <0x3c>;
			phandle = <0xe9>;
		};

		interconnect@1700000 {
			compatible = "qcom,sm8250-aggre2-noc";
			reg = <0x00 0x1700000 0x00 0x33000>;
			#interconnect-cells = <0x01>;
			qcom,bcm-voters = <0x3c>;
			phandle = <0xea>;
		};

		interconnect@1733000 {
			compatible = "qcom,sm8250-compute-noc";
			reg = <0x00 0x1733000 0x00 0xa180>;
			#interconnect-cells = <0x01>;
			qcom,bcm-voters = <0x3c>;
			phandle = <0xeb>;
		};

		interconnect@1740000 {
			compatible = "qcom,sm8250-mmss-noc";
			reg = <0x00 0x1740000 0x00 0x1f080>;
			#interconnect-cells = <0x01>;
			qcom,bcm-voters = <0x3c>;
			phandle = <0x6d>;
		};

		pci@1c00000 {
			compatible = "qcom,pcie-sm8250\0snps,dw-pcie";
			reg = <0x00 0x1c00000 0x00 0x3000 0x00 0x60000000 0x00 0xf1d 0x00 0x60000f20 0x00 0xa8 0x00 0x60001000 0x00 0x1000 0x00 0x60100000 0x00 0x100000>;
			reg-names = "parf\0dbi\0elbi\0atu\0config";
			device_type = "pci";
			linux,pci-domain = <0x00>;
			bus-range = <0x00 0xff>;
			num-lanes = <0x01>;
			#address-cells = <0x03>;
			#size-cells = <0x02>;
			ranges = <0x1000000 0x00 0x60200000 0x00 0x60200000 0x00 0x100000 0x2000000 0x00 0x60300000 0x00 0x60300000 0x00 0x3d00000>;
			interrupts = <0x00 0x8d 0x04>;
			interrupt-names = "msi";
			#interrupt-cells = <0x01>;
			interrupt-map-mask = <0x00 0x00 0x00 0x07>;
			interrupt-map = <0x00 0x00 0x00 0x01 0x01 0x00 0x95 0x04 0x00 0x00 0x00 0x02 0x01 0x00 0x96 0x04 0x00 0x00 0x00 0x03 0x01 0x00 0x97 0x04 0x00 0x00 0x00 0x04 0x01 0x00 0x98 0x04>;
			clocks = <0x1b 0x35 0x1b 0x31 0x1b 0x33 0x1b 0x34 0x1b 0x36 0x1b 0x37 0x1b 0x04 0x1b 0x16>;
			clock-names = "pipe\0aux\0cfg\0bus_master\0bus_slave\0slave_q2a\0tbu\0ddrss_sf_tbu";
			iommus = <0x1e 0x1c00 0x7f>;
			iommu-map = <0x00 0x1e 0x1c00 0x01 0x100 0x1e 0x1c01 0x01>;
			resets = <0x1b 0x04>;
			reset-names = "pci";
			power-domains = <0x1b 0x00>;
			phys = <0x3d>;
			phy-names = "pciephy";
			perst-gpios = <0x3e 0x4f 0x01>;
			wake-gpios = <0x3e 0x51 0x00>;
			pinctrl-names = "default";
			pinctrl-0 = <0x3f>;
			status = "disabled";
			phandle = <0xec>;
		};

		phy@1c06000 {
			compatible = "qcom,sm8250-qmp-gen3x1-pcie-phy";
			reg = <0x00 0x1c06000 0x00 0x1c0>;
			#address-cells = <0x02>;
			#size-cells = <0x02>;
			ranges;
			clocks = <0x1b 0x47 0x1b 0x33 0x1b 0x49 0x1b 0x2e>;
			clock-names = "aux\0cfg_ahb\0ref\0refgen";
			resets = <0x1b 0x07>;
			reset-names = "phy";
			assigned-clocks = <0x1b 0x2e>;
			assigned-clock-rates = <0x5f5e100>;
			status = "disabled";
			phandle = <0xed>;

			phy@1c06200 {
				reg = <0x00 0x1c06200 0x00 0x170 0x00 0x1c06400 0x00 0x200 0x00 0x1c06800 0x00 0x1f0 0x00 0x1c06c00 0x00 0xf4>;
				clocks = <0x1b 0x35>;
				clock-names = "pipe0";
				#phy-cells = <0x00>;
				#clock-cells = <0x00>;
				clock-output-names = "pcie_0_pipe_clk";
				phandle = <0x3d>;
			};
		};

		pci@1c08000 {
			compatible = "qcom,pcie-sm8250\0snps,dw-pcie";
			reg = <0x00 0x1c08000 0x00 0x3000 0x00 0x40000000 0x00 0xf1d 0x00 0x40000f20 0x00 0xa8 0x00 0x40001000 0x00 0x1000 0x00 0x40100000 0x00 0x100000>;
			reg-names = "parf\0dbi\0elbi\0atu\0config";
			device_type = "pci";
			linux,pci-domain = <0x01>;
			bus-range = <0x00 0xff>;
			num-lanes = <0x02>;
			#address-cells = <0x03>;
			#size-cells = <0x02>;
			ranges = <0x1000000 0x00 0x40200000 0x00 0x40200000 0x00 0x100000 0x2000000 0x00 0x40300000 0x00 0x40300000 0x00 0x1fd00000>;
			interrupts = <0x00 0x133 0x04>;
			interrupt-names = "msi";
			#interrupt-cells = <0x01>;
			interrupt-map-mask = <0x00 0x00 0x00 0x07>;
			interrupt-map = <0x00 0x00 0x00 0x01 0x01 0x00 0x1b2 0x04 0x00 0x00 0x00 0x02 0x01 0x00 0x1b3 0x04 0x00 0x00 0x00 0x03 0x01 0x00 0x1b6 0x04 0x00 0x00 0x00 0x04 0x01 0x00 0x1b7 0x04>;
			clocks = <0x1b 0x3c 0x1b 0x38 0x1b 0x3a 0x1b 0x3b 0x1b 0x3d 0x1b 0x3e 0x1b 0x4a 0x1b 0x04 0x1b 0x16>;
			clock-names = "pipe\0aux\0cfg\0bus_master\0bus_slave\0slave_q2a\0ref\0tbu\0ddrss_sf_tbu";
			assigned-clocks = <0x1b 0x38>;
			assigned-clock-rates = <0x124f800>;
			iommus = <0x1e 0x1c80 0x7f>;
			iommu-map = <0x00 0x1e 0x1c80 0x01 0x100 0x1e 0x1c81 0x01>;
			resets = <0x1b 0x09>;
			reset-names = "pci";
			power-domains = <0x1b 0x01>;
			phys = <0x40>;
			phy-names = "pciephy";
			perst-gpios = <0x3e 0x52 0x01>;
			wake-gpios = <0x3e 0x54 0x00>;
			pinctrl-names = "default";
			pinctrl-0 = <0x41>;
			status = "disabled";
			phandle = <0xee>;
		};

		phy@1c0e000 {
			compatible = "qcom,sm8250-qmp-gen3x2-pcie-phy";
			reg = <0x00 0x1c0e000 0x00 0x1c0>;
			#address-cells = <0x02>;
			#size-cells = <0x02>;
			ranges;
			clocks = <0x1b 0x47 0x1b 0x3a 0x1b 0x4a 0x1b 0x2f>;
			clock-names = "aux\0cfg_ahb\0ref\0refgen";
			resets = <0x1b 0x0c>;
			reset-names = "phy";
			assigned-clocks = <0x1b 0x2f>;
			assigned-clock-rates = <0x5f5e100>;
			status = "disabled";
			phandle = <0xef>;

			phy@1c0e200 {
				reg = <0x00 0x1c0e200 0x00 0x170 0x00 0x1c0e400 0x00 0x200 0x00 0x1c0ea00 0x00 0x1f0 0x00 0x1c0e600 0x00 0x170 0x00 0x1c0e800 0x00 0x200 0x00 0x1c0ee00 0x00 0xf4>;
				clocks = <0x1b 0x3c>;
				clock-names = "pipe0";
				#phy-cells = <0x00>;
				#clock-cells = <0x00>;
				clock-output-names = "pcie_1_pipe_clk";
				phandle = <0x40>;
			};
		};

		pci@1c10000 {
			compatible = "qcom,pcie-sm8250\0snps,dw-pcie";
			reg = <0x00 0x1c10000 0x00 0x3000 0x00 0x64000000 0x00 0xf1d 0x00 0x64000f20 0x00 0xa8 0x00 0x64001000 0x00 0x1000 0x00 0x64100000 0x00 0x100000>;
			reg-names = "parf\0dbi\0elbi\0atu\0config";
			device_type = "pci";
			linux,pci-domain = <0x02>;
			bus-range = <0x00 0xff>;
			num-lanes = <0x02>;
			#address-cells = <0x03>;
			#size-cells = <0x02>;
			ranges = <0x1000000 0x00 0x64200000 0x00 0x64200000 0x00 0x100000 0x2000000 0x00 0x64300000 0x00 0x64300000 0x00 0x3d00000>;
			interrupts = <0x00 0xf3 0x04>;
			interrupt-names = "msi";
			#interrupt-cells = <0x01>;
			interrupt-map-mask = <0x00 0x00 0x00 0x07>;
			interrupt-map = <0x00 0x00 0x00 0x01 0x01 0x00 0x122 0x04 0x00 0x00 0x00 0x02 0x01 0x00 0x19f 0x04 0x00 0x00 0x00 0x03 0x01 0x00 0x1a0 0x04 0x00 0x00 0x00 0x04 0x01 0x00 0x1a1 0x04>;
			clocks = <0x1b 0x43 0x1b 0x3f 0x1b 0x41 0x1b 0x42 0x1b 0x44 0x1b 0x45 0x1b 0x46 0x1b 0x04 0x1b 0x16>;
			clock-names = "pipe\0aux\0cfg\0bus_master\0bus_slave\0slave_q2a\0ref\0tbu\0ddrss_sf_tbu";
			assigned-clocks = <0x1b 0x3f>;
			assigned-clock-rates = <0x124f800>;
			iommus = <0x1e 0x1d00 0x7f>;
			iommu-map = <0x00 0x1e 0x1d00 0x01 0x100 0x1e 0x1d01 0x01>;
			resets = <0x1b 0x0e>;
			reset-names = "pci";
			power-domains = <0x1b 0x02>;
			phys = <0x42>;
			phy-names = "pciephy";
			perst-gpios = <0x3e 0x55 0x01>;
			wake-gpios = <0x3e 0x57 0x00>;
			pinctrl-names = "default";
			pinctrl-0 = <0x43>;
			status = "disabled";
			phandle = <0xf0>;
		};

		phy@1c16000 {
			compatible = "qcom,sm8250-qmp-modem-pcie-phy";
			reg = <0x00 0x1c16000 0x00 0x1c0>;
			#address-cells = <0x02>;
			#size-cells = <0x02>;
			ranges;
			clocks = <0x1b 0x47 0x1b 0x41 0x1b 0x46 0x1b 0x30>;
			clock-names = "aux\0cfg_ahb\0ref\0refgen";
			resets = <0x1b 0x11>;
			reset-names = "phy";
			assigned-clocks = <0x1b 0x30>;
			assigned-clock-rates = <0x5f5e100>;
			status = "disabled";
			phandle = <0xf1>;

			phy@1c16200 {
				reg = <0x00 0x1c16200 0x00 0x170 0x00 0x1c16400 0x00 0x200 0x00 0x1c16a00 0x00 0x1f0 0x00 0x1c16600 0x00 0x170 0x00 0x1c16800 0x00 0x200 0x00 0x1c16e00 0x00 0xf4>;
				clocks = <0x1b 0x43>;
				clock-names = "pipe0";
				#phy-cells = <0x00>;
				#clock-cells = <0x00>;
				clock-output-names = "pcie_2_pipe_clk";
				phandle = <0x42>;
			};
		};

		ufshc@1d84000 {
			compatible = "qcom,sm8250-ufshc\0qcom,ufshc\0jedec,ufs-2.0";
			reg = <0x00 0x1d84000 0x00 0x3000>;
			interrupts = <0x00 0x109 0x04>;
			phys = <0x44>;
			phy-names = "ufsphy";
			lanes-per-direction = <0x02>;
			#reset-cells = <0x01>;
			resets = <0x1b 0x21>;
			reset-names = "rst";
			power-domains = <0x1b 0x04>;
			iommus = <0x1e 0xe0 0x00 0x1e 0x4e0 0x00>;
			clock-names = "core_clk\0bus_aggr_clk\0iface_clk\0core_clk_unipro\0ref_clk\0tx_lane0_sync_clk\0rx_lane0_sync_clk\0rx_lane1_sync_clk";
			clocks = <0x1b 0xa2 0x1b 0x06 0x1b 0xa1 0x1b 0xab 0x19 0x00 0x1b 0xaa 0x1b 0xa8 0x1b 0xa9>;
			freq-table-hz = <0x23c3460 0x11e1a300 0x00 0x00 0x00 0x00 0x23c3460 0x11e1a300 0x00 0x00 0x00 0x00 0x00 0x00 0x00 0x00>;
			status = "okay";
			vcc-supply = <0x45>;
			vcc-max-microamp = "\0\f5";
			vccq-supply = <0x46>;
			vccq-max-microamp = "\0\f5";
			vccq2-supply = <0x47>;
			vccq2-max-microamp = "\0\f5";
			phandle = <0x48>;
		};

		phy@1d87000 {
			compatible = "qcom,sm8250-qmp-ufs-phy";
			reg = <0x00 0x1d87000 0x00 0x1c0>;
			#address-cells = <0x02>;
			#size-cells = <0x02>;
			ranges;
			clock-names = "ref\0ref_aux";
			clocks = <0x19 0x00 0x1b 0xa6>;
			resets = <0x48 0x00>;
			reset-names = "ufsphy";
			status = "okay";
			vdda-phy-supply = <0x49>;
			vdda-max-microamp = <0x15f2c>;
			vdda-pll-supply = <0x4a>;
			vdda-pll-max-microamp = <0x4970>;
			phandle = <0xf2>;

			phy@1d87400 {
				reg = <0x00 0x1d87400 0x00 0x16c 0x00 0x1d87600 0x00 0x200 0x00 0x1d87c00 0x00 0x200 0x00 0x1d87800 0x00 0x16c 0x00 0x1d87a00 0x00 0x200>;
				#phy-cells = <0x00>;
				phandle = <0x44>;
			};
		};

		interconnect@1e00000 {
			compatible = "qcom,sm8250-ipa-virt";
			reg = <0x00 0x1e00000 0x00 0x1000>;
			#interconnect-cells = <0x01>;
			qcom,bcm-voters = <0x3c>;
			phandle = <0xf3>;
		};

		hwlock@1f40000 {
			compatible = "qcom,tcsr-mutex";
			reg = <0x00 0x1f40000 0x00 0x40000>;
			#hwlock-cells = <0x01>;
			phandle = <0x17>;
		};

		codec@3240000 {
			compatible = "qcom,sm8250-lpass-wsa-macro";
			reg = <0x00 0x3240000 0x00 0x1000>;
			clocks = <0x4b 0x01 0x4b 0x00 0x4c 0x66 0x01 0x4c 0x67 0x01 0x4d 0x00 0x4e>;
			clock-names = "mclk\0npl\0macro\0dcodec\0va\0fsgen";
			#clock-cells = <0x00>;
			clock-frequency = <0x927c00>;
			clock-output-names = "mclk";
			#sound-dai-cells = <0x01>;
			pinctrl-names = "default";
			pinctrl-0 = <0x4f>;
			phandle = <0x50>;
		};

		soundwire-controller@3250000 {
			reg = <0x00 0x3250000 0x00 0x2000>;
			compatible = "qcom,soundwire-v1.5.1";
			interrupts = <0x00 0xca 0x04>;
			clocks = <0x50>;
			clock-names = "iface";
			qcom,din-ports = <0x02>;
			qcom,dout-ports = <0x06>;
			qcom,ports-sinterval-low = <0x71f3f07 0x1f3f0f0f>;
			qcom,ports-offset1 = <0x1020c06 0x120d070a>;
			qcom,ports-offset2 = <0xff001fff 0x1f0000>;
			qcom,ports-block-pack-mode = <0x100 0x10000>;
			#sound-dai-cells = <0x01>;
			#address-cells = <0x02>;
			#size-cells = <0x00>;
			phandle = <0xf4>;
		};

		clock-controller@3300000 {
			compatible = "qcom,sm8250-lpass-audiocc";
			reg = <0x00 0x3300000 0x00 0x30000>;
			#clock-cells = <0x01>;
			clocks = <0x4c 0x66 0x01 0x4c 0x67 0x01 0x4c 0x39 0x01>;
			clock-names = "core\0audio\0bus";
			phandle = <0x4b>;
		};

		codec@3370000 {
			compatible = "qcom,sm8250-lpass-va-macro";
			reg = <0x00 0x3370000 0x00 0x1000>;
			clocks = <0x4d 0x00 0x4c 0x66 0x01 0x4c 0x67 0x01>;
			clock-names = "mclk\0macro\0dcodec";
			#clock-cells = <0x00>;
			clock-frequency = <0x927c00>;
			clock-output-names = "fsgen";
			#sound-dai-cells = <0x01>;
			phandle = <0x4e>;
		};

		clock-controller@3380000 {
			compatible = "qcom,sm8250-lpass-aoncc";
			reg = <0x00 0x3380000 0x00 0x40000>;
			#clock-cells = <0x01>;
			clocks = <0x4c 0x66 0x01 0x4c 0x67 0x01 0x4c 0x3a 0x01>;
			clock-names = "core\0audio\0bus";
			phandle = <0x4d>;
		};

		pinctrl@33c0000 {
			compatible = "qcom,sm8250-lpass-lpi-pinctrl";
			reg = <0x00 0x33c0000 0x00 0x20000 0x00 0x3550000 0x00 0x10000>;
			gpio-controller;
			#gpio-cells = <0x02>;
			gpio-ranges = <0x51 0x00 0x00 0x0e>;
			clocks = <0x4c 0x66 0x01 0x4c 0x67 0x01>;
			clock-names = "core\0audio";
			phandle = <0x51>;

			wsa-swr-active-pins {
				phandle = <0x4f>;

				clk {
					pins = "gpio10";
					function = "wsa_swr_clk";
					drive-strength = <0x02>;
					slew-rate = <0x01>;
					bias-disable;
				};

				data {
					pins = "gpio11";
					function = "wsa_swr_data";
					drive-strength = <0x02>;
					slew-rate = <0x01>;
					bias-bus-hold;
				};
			};

			wsa-swr-sleep-pins {
				phandle = <0xf5>;

				clk {
					pins = "gpio10";
					function = "wsa_swr_clk";
					drive-strength = <0x02>;
					input-enable;
					bias-pull-down;
				};

				data {
					pins = "gpio11";
					function = "wsa_swr_data";
					drive-strength = <0x02>;
					input-enable;
					bias-pull-down;
				};
			};

			dmic01-active-pins {
				phandle = <0xf6>;

				clk {
					pins = "gpio6";
					function = "dmic1_clk";
					drive-strength = <0x08>;
					output-high;
				};

				data {
					pins = "gpio7";
					function = "dmic1_data";
					drive-strength = <0x08>;
					input-enable;
				};
			};

			dmic01-sleep-pins {
				phandle = <0xf7>;

				clk {
					pins = "gpio6";
					function = "dmic1_clk";
					drive-strength = <0x02>;
					bias-disable;
					output-low;
				};

				data {
					pins = "gpio7";
					function = "dmic1_data";
					drive-strength = <0x02>;
					bias-pull-down;
					input-enable;
				};
			};
		};

		gpu@3d00000 {
			compatible = "qcom,adreno-650.2\0qcom,adreno";
			#stream-id-cells = <0x10>;
			reg = <0x00 0x3d00000 0x00 0x40000>;
			reg-names = "kgsl_3d0_reg_memory";
			interrupts = <0x00 0x12c 0x04>;
			iommus = <0x52 0x00 0x401>;
			operating-points-v2 = <0x53>;
			qcom,gmu = <0x54>;
			status = "okay";
			phandle = <0xf8>;

			zap-shader {
				memory-region = <0x55>;
			};

			opp-table {
				compatible = "operating-points-v2";
				phandle = <0x53>;

				opp-670000000 {
					opp-hz = <0x00 0x27ef6380>;
					opp-level = <0x140>;
				};

				opp-587000000 {
					opp-hz = <0x00 0x22fce8c0>;
					opp-level = <0x100>;
				};

				opp-525000000 {
					opp-hz = <0x00 0x1f4add40>;
					opp-level = <0xe0>;
				};

				opp-490000000 {
					opp-hz = <0x00 0x1d34ce80>;
					opp-level = <0xc0>;
				};

				opp-441600000 {
					opp-hz = <0x00 0x1a524800>;
					opp-level = <0x90>;
				};

				opp-400000000 {
					opp-hz = <0x00 0x17d78400>;
					opp-level = <0x80>;
				};

				opp-305000000 {
					opp-hz = <0x00 0x122dee40>;
					opp-level = <0x40>;
				};
			};
		};

		gmu@3d6a000 {
			compatible = "qcom,adreno-gmu-650.2\0qcom,adreno-gmu";
			reg = <0x00 0x3d6a000 0x00 0x30000 0x00 0x3de0000 0x00 0x10000 0x00 0xb290000 0x00 0x10000 0x00 0xb490000 0x00 0x10000>;
			reg-names = "gmu\0rscc\0gmu_pdc\0gmu_pdc_seq";
			interrupts = <0x00 0x130 0x04 0x00 0x131 0x04>;
			interrupt-names = "hfi\0gmu";
			clocks = <0x56 0x00 0x56 0x03 0x56 0x06 0x1b 0x15 0x1b 0x25>;
			clock-names = "ahb\0gmu\0cxo\0axi\0memnoc";
			power-domains = <0x56 0x00 0x56 0x01>;
			power-domain-names = "cx\0gx";
			iommus = <0x52 0x05 0x400>;
			operating-points-v2 = <0x57>;
			status = "okay";
			phandle = <0x54>;

			opp-table {
				compatible = "operating-points-v2";
				phandle = <0x57>;

				opp-200000000 {
					opp-hz = <0x00 0xbebc200>;
					opp-level = <0x30>;
				};
			};
		};

		clock-controller@3d90000 {
			compatible = "qcom,sm8250-gpucc";
			reg = <0x00 0x3d90000 0x00 0x9000>;
			clocks = <0x19 0x00 0x1b 0x22 0x1b 0x23>;
			clock-names = "bi_tcxo\0gcc_gpu_gpll0_clk_src\0gcc_gpu_gpll0_div_clk_src";
			#clock-cells = <0x01>;
			#reset-cells = <0x01>;
			#power-domain-cells = <0x01>;
			phandle = <0x56>;
		};

		iommu@3da0000 {
			compatible = "qcom,sm8250-smmu-500\0arm,mmu-500";
			reg = <0x00 0x3da0000 0x00 0x10000>;
			#iommu-cells = <0x02>;
			#global-interrupts = <0x02>;
			interrupts = <0x00 0x2a0 0x04 0x00 0x2a1 0x04 0x00 0x2a6 0x04 0x00 0x2a7 0x04 0x00 0x2a8 0x04 0x00 0x2a9 0x04 0x00 0x2aa 0x04 0x00 0x2ab 0x04 0x00 0x2ac 0x04 0x00 0x2ad 0x04>;
			clocks = <0x56 0x00 0x1b 0x25 0x1b 0x26>;
			clock-names = "ahb\0bus\0iface";
			power-domains = <0x56 0x00>;
			phandle = <0x52>;
		};

		remoteproc@5c00000 {
			compatible = "qcom,sm8250-slpi-pas";
			reg = <0x00 0x5c00000 0x00 0x4000>;
			interrupts-extended = <0x58 0x09 0x04 0x59 0x00 0x01 0x59 0x01 0x01 0x59 0x02 0x01 0x59 0x03 0x01>;
			interrupt-names = "wdog\0fatal\0ready\0handover\0stop-ack";
			clocks = <0x19 0x00>;
			clock-names = "xo";
			power-domains = <0x5a 0x03 0x14 0x04 0x14 0x05>;
			power-domain-names = "load_state\0lcx\0lmx";
			memory-region = <0x5b>;
			qcom,smem-states = <0x5c 0x00>;
			qcom,smem-state-names = "stop";
			status = "disabled";
			phandle = <0xf9>;

			glink-edge {
				interrupts-extended = <0x18 0x04 0x00 0x01>;
				mboxes = <0x18 0x04 0x00>;
				label = "slpi";
				qcom,remote-pid = <0x03>;

				fastrpc {
					compatible = "qcom,fastrpc";
					qcom,glink-channels = "fastrpcglink-apps-dsp";
					label = "sdsp";
					#address-cells = <0x01>;
					#size-cells = <0x00>;

					compute-cb@1 {
						compatible = "qcom,fastrpc-compute-cb";
						reg = <0x01>;
						iommus = <0x1e 0x541 0x00>;
					};

					compute-cb@2 {
						compatible = "qcom,fastrpc-compute-cb";
						reg = <0x02>;
						iommus = <0x1e 0x542 0x00>;
					};

					compute-cb@3 {
						compatible = "qcom,fastrpc-compute-cb";
						reg = <0x03>;
						iommus = <0x1e 0x543 0x00>;
					};
				};
			};
		};

		remoteproc@8300000 {
			compatible = "qcom,sm8250-cdsp-pas";
			reg = <0x00 0x8300000 0x00 0x10000>;
			interrupts-extended = <0x01 0x00 0x242 0x04 0x5d 0x00 0x01 0x5d 0x01 0x01 0x5d 0x02 0x01 0x5d 0x03 0x01>;
			interrupt-names = "wdog\0fatal\0ready\0handover\0stop-ack";
			clocks = <0x19 0x00>;
			clock-names = "xo";
			power-domains = <0x5a 0x00 0x14 0x00>;
			power-domain-names = "load_state\0cx";
			memory-region = <0x5e>;
			qcom,smem-states = <0x5f 0x00>;
			qcom,smem-state-names = "stop";
			status = "disabled";
			phandle = <0xfa>;

			glink-edge {
				interrupts-extended = <0x18 0x06 0x00 0x01>;
				mboxes = <0x18 0x06 0x00>;
				label = "cdsp";
				qcom,remote-pid = <0x05>;

				fastrpc {
					compatible = "qcom,fastrpc";
					qcom,glink-channels = "fastrpcglink-apps-dsp";
					label = "cdsp";
					#address-cells = <0x01>;
					#size-cells = <0x00>;

					compute-cb@1 {
						compatible = "qcom,fastrpc-compute-cb";
						reg = <0x01>;
						iommus = <0x1e 0x1001 0x460>;
					};

					compute-cb@2 {
						compatible = "qcom,fastrpc-compute-cb";
						reg = <0x02>;
						iommus = <0x1e 0x1002 0x460>;
					};

					compute-cb@3 {
						compatible = "qcom,fastrpc-compute-cb";
						reg = <0x03>;
						iommus = <0x1e 0x1003 0x460>;
					};

					compute-cb@4 {
						compatible = "qcom,fastrpc-compute-cb";
						reg = <0x04>;
						iommus = <0x1e 0x1004 0x460>;
					};

					compute-cb@5 {
						compatible = "qcom,fastrpc-compute-cb";
						reg = <0x05>;
						iommus = <0x1e 0x1005 0x460>;
					};

					compute-cb@6 {
						compatible = "qcom,fastrpc-compute-cb";
						reg = <0x06>;
						iommus = <0x1e 0x1006 0x460>;
					};

					compute-cb@7 {
						compatible = "qcom,fastrpc-compute-cb";
						reg = <0x07>;
						iommus = <0x1e 0x1007 0x460>;
					};

					compute-cb@8 {
						compatible = "qcom,fastrpc-compute-cb";
						reg = <0x08>;
						iommus = <0x1e 0x1008 0x460>;
					};
				};
			};
		};

		sound {
			phandle = <0xfb>;
		};

		phy@88e3000 {
			compatible = "qcom,sm8250-usb-hs-phy\0qcom,usb-snps-hs-7nm-phy";
			reg = <0x00 0x88e3000 0x00 0x400>;
			status = "okay";
			#phy-cells = <0x00>;
			clocks = <0x19 0x00>;
			clock-names = "ref";
			resets = <0x1b 0x1b>;
			vdda-pll-supply = <0x49>;
			vdda33-supply = <0x60>;
			vdda18-supply = <0x61>;
			phandle = <0x65>;
		};

		phy@88e4000 {
			compatible = "qcom,sm8250-usb-hs-phy\0qcom,usb-snps-hs-7nm-phy";
			reg = <0x00 0x88e4000 0x00 0x400>;
			status = "okay";
			#phy-cells = <0x00>;
			clocks = <0x19 0x00>;
			clock-names = "ref";
			resets = <0x1b 0x1c>;
			vdda-pll-supply = <0x49>;
			vdda33-supply = <0x60>;
			vdda18-supply = <0x61>;
			phandle = <0x67>;
		};

		phy@88e9000 {
			compatible = "qcom,sm8250-qmp-usb3-dp-phy";
			reg = <0x00 0x88e9000 0x00 0x200 0x00 0x88e8000 0x00 0x40 0x00 0x88ea000 0x00 0x200>;
			status = "okay";
			#address-cells = <0x02>;
			#size-cells = <0x02>;
			ranges;
			clocks = <0x1b 0xb9 0x19 0x00 0x1b 0xbb>;
			clock-names = "aux\0ref_clk_src\0com_aux";
			resets = <0x1b 0x24 0x1b 0x26>;
			reset-names = "phy\0common";
			vdda-phy-supply = <0x4a>;
			vdda-pll-supply = <0x62>;
			phandle = <0xfc>;

			usb3-phy@88e9200 {
				reg = <0x00 0x88e9200 0x00 0x200 0x00 0x88e9400 0x00 0x200 0x00 0x88e9c00 0x00 0x400 0x00 0x88e9600 0x00 0x200 0x00 0x88e9800 0x00 0x200 0x00 0x88e9a00 0x00 0x100>;
				#clock-cells = <0x00>;
				#phy-cells = <0x00>;
				clocks = <0x1b 0xbc>;
				clock-names = "pipe0";
				clock-output-names = "usb3_phy_pipe_clk_src";
				phandle = <0x66>;
			};

			dp-phy@88ea200 {
				reg = <0x00 0x88ea200 0x00 0x200 0x00 0x88ea400 0x00 0x200 0x00 0x88eaa00 0x00 0x200 0x00 0x88ea600 0x00 0x200 0x00 0x88ea800 0x00 0x200>;
				#phy-cells = <0x00>;
				#clock-cells = <0x01>;
				phandle = <0x7c>;
			};
		};

		phy@88eb000 {
			compatible = "qcom,sm8250-qmp-usb3-uni-phy";
			reg = <0x00 0x88eb000 0x00 0x200>;
			status = "okay";
			#address-cells = <0x02>;
			#size-cells = <0x02>;
			ranges;
			clocks = <0x1b 0xbf 0x19 0x00 0x1b 0xbe 0x1b 0xc1>;
			clock-names = "aux\0ref_clk_src\0ref\0com_aux";
			resets = <0x1b 0x29 0x1b 0x27>;
			reset-names = "phy\0common";
			vdda-phy-supply = <0x4a>;
			vdda-pll-supply = <0x62>;
			phandle = <0xfd>;

			phy@88eb200 {
				reg = <0x00 0x88eb200 0x00 0x200 0x00 0x88eb400 0x00 0x200 0x00 0x88eb800 0x00 0x800>;
				#clock-cells = <0x00>;
				#phy-cells = <0x00>;
				clocks = <0x1b 0xc2>;
				clock-names = "pipe0";
				clock-output-names = "usb3_uni_phy_pipe_clk_src";
				phandle = <0x68>;
			};
		};

		sdhci@8804000 {
			compatible = "qcom,sm8250-sdhci\0qcom,sdhci-msm-v5";
			reg = <0x00 0x8804000 0x00 0x1000>;
			interrupts = <0x00 0xcc 0x04 0x00 0xde 0x04>;
			interrupt-names = "hc_irq\0pwr_irq";
			clocks = <0x1b 0x89 0x1b 0x8a 0x19 0x00>;
			clock-names = "iface\0core\0xo";
			iommus = <0x1e 0x4a0 0x00>;
			qcom,dll-config = <0x7642c>;
			qcom,ddr-config = <0x80040868>;
			power-domains = <0x14 0x00>;
			operating-points-v2 = <0x63>;
			status = "disabled";
			phandle = <0xfe>;

			sdhc2-opp-table {
				compatible = "operating-points-v2";
				phandle = <0x63>;

				opp-19200000 {
					opp-hz = <0x00 0x124f800>;
					required-opps = <0x1c>;
				};

				opp-50000000 {
					opp-hz = <0x00 0x2faf080>;
					required-opps = <0x15>;
				};

				opp-100000000 {
					opp-hz = <0x00 0x5f5e100>;
					required-opps = <0x1d>;
				};

				opp-202000000 {
					opp-hz = <0x00 0xc0a4680>;
					required-opps = <0x64>;
				};
			};
		};

		interconnect@90c0000 {
			compatible = "qcom,sm8250-dc-noc";
			reg = <0x00 0x90c0000 0x00 0x4200>;
			#interconnect-cells = <0x01>;
			qcom,bcm-voters = <0x3c>;
			phandle = <0xff>;
		};

		interconnect@9100000 {
			compatible = "qcom,sm8250-gem-noc";
			reg = <0x00 0x9100000 0x00 0xb4000>;
			#interconnect-cells = <0x01>;
			qcom,bcm-voters = <0x3c>;
			phandle = <0x6b>;
		};

		interconnect@9990000 {
			compatible = "qcom,sm8250-npu-noc";
			reg = <0x00 0x9990000 0x00 0x1600>;
			#interconnect-cells = <0x01>;
			qcom,bcm-voters = <0x3c>;
			phandle = <0x100>;
		};

		usb@a6f8800 {
			compatible = "qcom,sm8250-dwc3\0qcom,dwc3";
			reg = <0x00 0xa6f8800 0x00 0x400>;
			status = "okay";
			#address-cells = <0x02>;
			#size-cells = <0x02>;
			ranges;
			dma-ranges;
			clocks = <0x1b 0x0e 0x1b 0xad 0x1b 0x07 0x1b 0xaf 0x1b 0xb2 0x1b 0xbe>;
			clock-names = "cfg_noc\0core\0iface\0mock_utmi\0sleep\0xo";
			assigned-clocks = <0x1b 0xaf 0x1b 0xad>;
			assigned-clock-rates = <0x124f800 0xbebc200>;
			interrupts-extended = <0x01 0x00 0x83 0x04 0x58 0x0e 0x03 0x58 0x0f 0x03 0x58 0x11 0x04>;
			interrupt-names = "hs_phy_irq\0dp_hs_phy_irq\0dm_hs_phy_irq\0ss_phy_irq";
			power-domains = <0x1b 0x05>;
			resets = <0x1b 0x22>;
			phandle = <0x101>;

			usb@a600000 {
				compatible = "snps,dwc3";
				reg = <0x00 0xa600000 0x00 0xcd00>;
				interrupts = <0x00 0x85 0x04>;
				iommus = <0x1e 0x00 0x00>;
				snps,dis_u2_susphy_quirk;
				snps,dis_enblslpm_quirk;
				phys = <0x65 0x66>;
				phy-names = "usb2-phy\0usb3-phy";
				dr_mode = "peripheral";
				phandle = <0x102>;
			};
		};

		system-cache-controller@9200000 {
			compatible = "qcom,sm8250-llcc";
			reg = <0x00 0x9200000 0x00 0x1d0000 0x00 0x9600000 0x00 0x50000>;
			reg-names = "llcc_base\0llcc_broadcast_base";
		};

		usb@a8f8800 {
			compatible = "qcom,sm8250-dwc3\0qcom,dwc3";
			reg = <0x00 0xa8f8800 0x00 0x400>;
			status = "okay";
			#address-cells = <0x02>;
			#size-cells = <0x02>;
			ranges;
			dma-ranges;
			clocks = <0x1b 0x0f 0x1b 0xb3 0x1b 0x08 0x1b 0xb5 0x1b 0xb8 0x1b 0xbe>;
			clock-names = "cfg_noc\0core\0iface\0mock_utmi\0sleep\0xo";
			assigned-clocks = <0x1b 0xb5 0x1b 0xb3>;
			assigned-clock-rates = <0x124f800 0xbebc200>;
			interrupts-extended = <0x01 0x00 0x88 0x04 0x58 0x0c 0x03 0x58 0x0d 0x03 0x58 0x10 0x04>;
			interrupt-names = "hs_phy_irq\0dp_hs_phy_irq\0dm_hs_phy_irq\0ss_phy_irq";
			power-domains = <0x1b 0x06>;
			resets = <0x1b 0x23>;
			phandle = <0x103>;

			usb@a800000 {
				compatible = "snps,dwc3";
				reg = <0x00 0xa800000 0x00 0xcd00>;
				interrupts = <0x00 0x8a 0x04>;
				iommus = <0x1e 0x20 0x00>;
				snps,dis_u2_susphy_quirk;
				snps,dis_enblslpm_quirk;
				phys = <0x67 0x68>;
				phy-names = "usb2-phy\0usb3-phy";
				dr_mode = "host";
				phandle = <0x104>;
			};
		};

		video-codec@aa00000 {
			compatible = "qcom,sm8250-venus";
			reg = <0x00 0xaa00000 0x00 0x100000>;
			interrupts = <0x00 0xae 0x04>;
			power-domains = <0x69 0x00 0x69 0x02 0x14 0x08>;
			power-domain-names = "venus\0vcodec0\0mx";
			operating-points-v2 = <0x6a>;
			clocks = <0x1b 0xc5 0x69 0x01 0x69 0x0a>;
			clock-names = "iface\0core\0vcodec0_core";
			interconnects = <0x6b 0x02 0x6c 0x30 0x6d 0x04 0x6e 0x01>;
			interconnect-names = "cpu-cfg\0video-mem";
			iommus = <0x1e 0x2100 0x400>;
			memory-region = <0x6f>;
			resets = <0x1b 0x2b 0x69 0x02>;
			reset-names = "bus\0core";
			status = "okay";
			phandle = <0x105>;

			video-decoder {
				compatible = "venus-decoder";
			};

			video-encoder {
				compatible = "venus-encoder";
			};

			venus-opp-table {
				compatible = "operating-points-v2";
				phandle = <0x6a>;

				opp-720000000 {
					opp-hz = <0x00 0x2aea5400>;
					required-opps = <0x15>;
				};

				opp-1014000000 {
					opp-hz = <0x00 0x3c706980>;
					required-opps = <0x1d>;
				};

				opp-1098000000 {
					opp-hz = <0x00 0x41722680>;
					required-opps = <0x64>;
				};

				opp-1332000000 {
					opp-hz = <0x00 0x4f64b500>;
					required-opps = <0x70>;
				};
			};
		};

		clock-controller@abf0000 {
			compatible = "qcom,sm8250-videocc";
			reg = <0x00 0xabf0000 0x00 0x10000>;
			clocks = <0x1b 0xc4 0x19 0x00 0x19 0x01>;
			mmcx-supply = <0x71>;
			clock-names = "iface\0bi_tcxo\0bi_tcxo_ao";
			#clock-cells = <0x01>;
			#reset-cells = <0x01>;
			#power-domain-cells = <0x01>;
			phandle = <0x69>;
		};

		mdss@ae00000 {
			compatible = "qcom,sm8250-mdss";
			reg = <0x00 0xae00000 0x00 0x1000>;
			reg-names = "mdss";
			interconnects = <0x6d 0x07 0x6e 0x01 0x6d 0x08 0x6e 0x01>;
			interconnect-names = "mdp0-mem\0mdp1-mem";
			power-domains = <0x72 0x00>;
			clocks = <0x72 0x00 0x1b 0x18 0x1b 0x19 0x72 0x20>;
			clock-names = "iface\0bus\0nrt_bus\0core";
			assigned-clocks = <0x72 0x20>;
			assigned-clock-rates = <0x1b6b0b00>;
			interrupts = <0x00 0x53 0x04>;
			interrupt-controller;
			#interrupt-cells = <0x01>;
			iommus = <0x1e 0x820 0x402>;
			status = "disabled";
			#address-cells = <0x02>;
			#size-cells = <0x02>;
			ranges;
			phandle = <0x74>;

			mdp@ae01000 {
				compatible = "qcom,sm8250-dpu";
				reg = <0x00 0xae01000 0x00 0x8f000 0x00 0xaeb0000 0x00 0x2008>;
				reg-names = "mdp\0vbif";
				clocks = <0x72 0x00 0x1b 0x18 0x72 0x20 0x72 0x2c>;
				clock-names = "iface\0bus\0core\0vsync";
				assigned-clocks = <0x72 0x20 0x72 0x2c>;
				assigned-clock-rates = <0x1b6b0b00 0x124f800>;
				operating-points-v2 = <0x73>;
				power-domains = <0x14 0x06>;
				interrupt-parent = <0x74>;
				interrupts = <0x00 0x04>;
				phandle = <0x106>;

				ports {
					#address-cells = <0x01>;
					#size-cells = <0x00>;

					port@0 {
						reg = <0x00>;

						endpoint {
							remote-endpoint = <0x75>;
							phandle = <0x79>;
						};
					};

					port@1 {
						reg = <0x01>;

						endpoint {
							remote-endpoint = <0x76>;
							phandle = <0x7b>;
						};
					};
				};

				mdp-opp-table {
					compatible = "operating-points-v2";
					phandle = <0x73>;

					opp-200000000 {
						opp-hz = <0x00 0xbebc200>;
						required-opps = <0x15>;
					};

					opp-300000000 {
						opp-hz = <0x00 0x11e1a300>;
						required-opps = <0x1d>;
					};

					opp-345000000 {
						opp-hz = <0x00 0x14904840>;
						required-opps = <0x64>;
					};

					opp-460000000 {
						opp-hz = <0x00 0x1b6b0b00>;
						required-opps = <0x70>;
					};
				};
			};

			dsi@ae94000 {
				compatible = "qcom,mdss-dsi-ctrl";
				reg = <0x00 0xae94000 0x00 0x400>;
				reg-names = "dsi_ctrl";
				interrupt-parent = <0x74>;
				interrupts = <0x04 0x04>;
				clocks = <0x72 0x02 0x72 0x05 0x72 0x24 0x72 0x1c 0x72 0x00 0x1b 0x18>;
				clock-names = "byte\0byte_intf\0pixel\0core\0iface\0bus";
				assigned-clocks = <0x72 0x03 0x72 0x25>;
				assigned-clock-parents = <0x77 0x00 0x77 0x01>;
				operating-points-v2 = <0x78>;
				power-domains = <0x14 0x06>;
				phys = <0x77>;
				phy-names = "dsi";
				status = "disabled";
				#address-cells = <0x01>;
				#size-cells = <0x00>;
				phandle = <0x107>;

				ports {
					#address-cells = <0x01>;
					#size-cells = <0x00>;

					port@0 {
						reg = <0x00>;

						endpoint {
							remote-endpoint = <0x79>;
							phandle = <0x75>;
						};
					};

					port@1 {
						reg = <0x01>;

						endpoint {
							phandle = <0x108>;
						};
					};
				};
			};

			dsi-phy@ae94400 {
				compatible = "qcom,dsi-phy-7nm";
				reg = <0x00 0xae94400 0x00 0x200 0x00 0xae94600 0x00 0x280 0x00 0xae94900 0x00 0x260>;
				reg-names = "dsi_phy\0dsi_phy_lane\0dsi_pll";
				#clock-cells = <0x01>;
				#phy-cells = <0x00>;
				clocks = <0x72 0x00 0x19 0x00>;
				clock-names = "iface\0ref";
				status = "disabled";
				phandle = <0x77>;
			};

			dsi@ae96000 {
				compatible = "qcom,mdss-dsi-ctrl";
				reg = <0x00 0xae96000 0x00 0x400>;
				reg-names = "dsi_ctrl";
				interrupt-parent = <0x74>;
				interrupts = <0x05 0x04>;
				clocks = <0x72 0x06 0x72 0x09 0x72 0x26 0x72 0x1e 0x72 0x00 0x1b 0x18>;
				clock-names = "byte\0byte_intf\0pixel\0core\0iface\0bus";
				assigned-clocks = <0x72 0x07 0x72 0x27>;
				assigned-clock-parents = <0x7a 0x00 0x7a 0x01>;
				operating-points-v2 = <0x78>;
				power-domains = <0x14 0x06>;
				phys = <0x7a>;
				phy-names = "dsi";
				status = "disabled";
				#address-cells = <0x01>;
				#size-cells = <0x00>;
				phandle = <0x109>;

				ports {
					#address-cells = <0x01>;
					#size-cells = <0x00>;

					port@0 {
						reg = <0x00>;

						endpoint {
							remote-endpoint = <0x7b>;
							phandle = <0x76>;
						};
					};

					port@1 {
						reg = <0x01>;

						endpoint {
							phandle = <0x10a>;
						};
					};
				};
			};

			dsi-phy@ae96400 {
				compatible = "qcom,dsi-phy-7nm";
				reg = <0x00 0xae96400 0x00 0x200 0x00 0xae96600 0x00 0x280 0x00 0xae96900 0x00 0x260>;
				reg-names = "dsi_phy\0dsi_phy_lane\0dsi_pll";
				#clock-cells = <0x01>;
				#phy-cells = <0x00>;
				clocks = <0x72 0x00 0x19 0x00>;
				clock-names = "iface\0ref";
				status = "disabled";
				phandle = <0x7a>;

				dsi-opp-table {
					compatible = "operating-points-v2";
					phandle = <0x78>;

					opp-187500000 {
						opp-hz = <0x00 0xb2d05e0>;
						required-opps = <0x15>;
					};

					opp-300000000 {
						opp-hz = <0x00 0x11e1a300>;
						required-opps = <0x1d>;
					};

					opp-358000000 {
						opp-hz = <0x00 0x1556a580>;
						required-opps = <0x64>;
					};
				};
			};
		};

		clock-controller@af00000 {
			compatible = "qcom,sm8250-dispcc";
			reg = <0x00 0xaf00000 0x00 0x10000>;
			mmcx-supply = <0x71>;
			clocks = <0x19 0x00 0x77 0x00 0x77 0x01 0x7a 0x00 0x7a 0x01 0x7c 0x00 0x7c 0x01>;
			clock-names = "bi_tcxo\0dsi0_phy_pll_out_byteclk\0dsi0_phy_pll_out_dsiclk\0dsi1_phy_pll_out_byteclk\0dsi1_phy_pll_out_dsiclk\0dp_phy_pll_link_clk\0dp_phy_pll_vco_div_clk";
			#clock-cells = <0x01>;
			#reset-cells = <0x01>;
			#power-domain-cells = <0x01>;
			phandle = <0x72>;
		};

		interrupt-controller@b220000 {
			compatible = "qcom,sm8250-pdc\0qcom,pdc";
			reg = <0x00 0xb220000 0x00 0x30000 0x00 0x17c000f0 0x00 0x60>;
			qcom,pdc-ranges = <0x00 0x1e0 0x5e 0x5e 0x261 0x1f 0x7d 0x3f 0x01 0x7e 0x2cc 0x0c>;
			#interrupt-cells = <0x02>;
			interrupt-parent = <0x01>;
			interrupt-controller;
			phandle = <0x58>;
		};

		thermal-sensor@c263000 {
			compatible = "qcom,sm8250-tsens\0qcom,tsens-v2";
			reg = <0x00 0xc263000 0x00 0x1ff 0x00 0xc222000 0x00 0x1ff>;
			#qcom,sensors = <0x10>;
			interrupts = <0x00 0x1fa 0x04 0x00 0x1fc 0x04>;
			interrupt-names = "uplow\0critical";
			#thermal-sensor-cells = <0x01>;
			phandle = <0x8b>;
		};

		thermal-sensor@c265000 {
			compatible = "qcom,sm8250-tsens\0qcom,tsens-v2";
			reg = <0x00 0xc265000 0x00 0x1ff 0x00 0xc223000 0x00 0x1ff>;
			#qcom,sensors = <0x09>;
			interrupts = <0x00 0x1fb 0x04 0x00 0x1fd 0x04>;
			interrupt-names = "uplow\0critical";
			#thermal-sensor-cells = <0x01>;
			phandle = <0xa4>;
		};

		power-controller@c300000 {
			compatible = "qcom,sm8250-aoss-qmp";
			reg = <0x00 0xc300000 0x00 0x100000>;
			interrupts-extended = <0x18 0x00 0x00 0x01>;
			mboxes = <0x18 0x00 0x00>;
			#clock-cells = <0x00>;
			#power-domain-cells = <0x01>;
			phandle = <0x5a>;
		};

		spmi@c440000 {
			compatible = "qcom,spmi-pmic-arb";
			reg = <0x00 0xc440000 0x00 0x1100 0x00 0xc600000 0x00 0x2000000 0x00 0xe600000 0x00 0x100000 0x00 0xe700000 0x00 0xa0000 0x00 0xc40a000 0x00 0x26000>;
			reg-names = "core\0chnls\0obsrvr\0intr\0cnfg";
			interrupt-names = "periph_irq";
			interrupts-extended = <0x58 0x01 0x04>;
			qcom,ee = <0x00>;
			qcom,channel = <0x00>;
			#address-cells = <0x02>;
			#size-cells = <0x00>;
			interrupt-controller;
			#interrupt-cells = <0x04>;
			phandle = <0x10b>;

			pmic@0 {
				compatible = "qcom,pm8150\0qcom,spmi-pmic";
				reg = <0x00 0x00>;
				#address-cells = <0x01>;
				#size-cells = <0x00>;
				phandle = <0x10c>;

				power-on@800 {
					compatible = "qcom,pm8998-pon";
					reg = <0x800>;
					mode-bootloader = <0x02>;
					mode-recovery = <0x01>;
					phandle = <0x10d>;

					pwrkey {
						compatible = "qcom,pm8941-pwrkey";
						interrupts = <0x00 0x08 0x00 0x03>;
						debounce = <0x3d09>;
						bias-pull-up;
						linux,code = <0x74>;
						status = "okay";
						phandle = <0x10e>;
					};

					resin {
						compatible = "qcom,pm8941-resin";
						interrupts = <0x00 0x08 0x01 0x03>;
						debounce = <0x3d09>;
						bias-pull-up;
						status = "okay";
						linux,code = <0x72>;
						phandle = <0x10f>;
					};
				};

				temp-alarm@2400 {
					compatible = "qcom,spmi-temp-alarm";
					reg = <0x2400>;
					interrupts = <0x00 0x24 0x00 0x03>;
					io-channels = <0x7d 0x06>;
					io-channel-names = "thermal";
					#thermal-sensor-cells = <0x00>;
					phandle = <0xa5>;
				};

				adc@3100 {
					compatible = "qcom,spmi-adc5";
					reg = <0x3100>;
					#address-cells = <0x01>;
					#size-cells = <0x00>;
					#io-channel-cells = <0x01>;
					interrupts = <0x00 0x31 0x00 0x01>;
					phandle = <0x7d>;

					ref-gnd@0 {
						reg = <0x00>;
						qcom,pre-scaling = <0x01 0x01>;
						label = "ref_gnd";
					};

					vref-1p25@1 {
						reg = <0x01>;
						qcom,pre-scaling = <0x01 0x01>;
						label = "vref_1p25";
					};

					die-temp@6 {
						reg = <0x06>;
						qcom,pre-scaling = <0x01 0x01>;
						label = "die_temp";
					};
				};

				adc-tm@3500 {
					compatible = "qcom,spmi-adc-tm5";
					reg = <0x3500>;
					interrupts = <0x00 0x35 0x00 0x01>;
					#thermal-sensor-cells = <0x01>;
					#address-cells = <0x01>;
					#size-cells = <0x00>;
					status = "disabled";
					phandle = <0x110>;
				};

				rtc@6000 {
					compatible = "qcom,pm8941-rtc";
					reg = <0x6000>;
					reg-names = "rtc\0alarm";
					interrupts = <0x00 0x61 0x01 0x00>;
				};

				gpio@c000 {
					compatible = "qcom,pm8150-gpio";
					reg = <0xc000>;
					gpio-controller;
					#gpio-cells = <0x02>;
					interrupt-controller;
					#interrupt-cells = <0x02>;
					phandle = <0xa8>;
				};
			};

			pmic@1 {
				compatible = "qcom,pm8150\0qcom,spmi-pmic";
				reg = <0x01 0x00>;
				#address-cells = <0x01>;
				#size-cells = <0x00>;
			};

			pmic@2 {
				compatible = "qcom,pm8150b\0qcom,spmi-pmic";
				reg = <0x02 0x00>;
				#address-cells = <0x01>;
				#size-cells = <0x00>;

				power-on@800 {
					compatible = "qcom,pm8916-pon";
					reg = <0x800>;
					status = "disabled";
				};

				dcdc@1100 {
					compatible = "qcom,pm8150b-vbus-reg";
					status = "disabled";
					reg = <0x1100>;
					phandle = <0x111>;
				};

				temp-alarm@2400 {
					compatible = "qcom,spmi-temp-alarm";
					reg = <0x2400>;
					interrupts = <0x02 0x24 0x00 0x03>;
					io-channels = <0x7e 0x06>;
					io-channel-names = "thermal";
					#thermal-sensor-cells = <0x00>;
					phandle = <0xa6>;
				};

				adc@3100 {
					compatible = "qcom,spmi-adc5";
					reg = <0x3100>;
					#address-cells = <0x01>;
					#size-cells = <0x00>;
					#io-channel-cells = <0x01>;
					interrupts = <0x02 0x31 0x00 0x01>;
					phandle = <0x7e>;

					ref-gnd@0 {
						reg = <0x00>;
						qcom,pre-scaling = <0x01 0x01>;
						label = "ref_gnd";
					};

					vref-1p25@1 {
						reg = <0x01>;
						qcom,pre-scaling = <0x01 0x01>;
						label = "vref_1p25";
					};

					die-temp@6 {
						reg = <0x06>;
						qcom,pre-scaling = <0x01 0x01>;
						label = "die_temp";
					};

					chg-temp@9 {
						reg = <0x09>;
						qcom,pre-scaling = <0x01 0x01>;
						label = "chg_temp";
					};
				};

				adc-tm@3500 {
					compatible = "qcom,spmi-adc-tm5";
					reg = <0x3500>;
					interrupts = <0x02 0x35 0x00 0x01>;
					#thermal-sensor-cells = <0x01>;
					#address-cells = <0x01>;
					#size-cells = <0x00>;
					status = "disabled";
					phandle = <0x112>;
				};

				gpio@c000 {
					compatible = "qcom,pm8150b-gpio";
					reg = <0xc000>;
					gpio-controller;
					#gpio-cells = <0x02>;
					interrupt-controller;
					#interrupt-cells = <0x02>;
					phandle = <0x113>;
				};
			};

			pmic@3 {
				compatible = "qcom,pm8150b\0qcom,spmi-pmic";
				reg = <0x03 0x00>;
				#address-cells = <0x01>;
				#size-cells = <0x00>;
			};

			pmic@4 {
				compatible = "qcom,pm8150l\0qcom,spmi-pmic";
				reg = <0x04 0x00>;
				#address-cells = <0x01>;
				#size-cells = <0x00>;

				power-on@800 {
					compatible = "qcom,pm8916-pon";
					reg = <0x800>;
					status = "disabled";
				};

				temp-alarm@2400 {
					compatible = "qcom,spmi-temp-alarm";
					reg = <0x2400>;
					interrupts = <0x04 0x24 0x00 0x03>;
					io-channels = <0x7f 0x06>;
					io-channel-names = "thermal";
					#thermal-sensor-cells = <0x00>;
					phandle = <0xa7>;
				};

				adc@3100 {
					compatible = "qcom,spmi-adc5";
					reg = <0x3100>;
					#address-cells = <0x01>;
					#size-cells = <0x00>;
					#io-channel-cells = <0x01>;
					interrupts = <0x04 0x31 0x00 0x01>;
					phandle = <0x7f>;

					ref-gnd@0 {
						reg = <0x00>;
						qcom,pre-scaling = <0x01 0x01>;
						label = "ref_gnd";
					};

					vref-1p25@1 {
						reg = <0x01>;
						qcom,pre-scaling = <0x01 0x01>;
						label = "vref_1p25";
					};

					die-temp@6 {
						reg = <0x06>;
						qcom,pre-scaling = <0x01 0x01>;
						label = "die_temp";
					};
				};

				adc-tm@3500 {
					compatible = "qcom,spmi-adc-tm5";
					reg = <0x3500>;
					interrupts = <0x04 0x35 0x00 0x01>;
					#thermal-sensor-cells = <0x01>;
					#address-cells = <0x01>;
					#size-cells = <0x00>;
					status = "disabled";
					phandle = <0x114>;
				};

				gpio@c000 {
					compatible = "qcom,pm8150l-gpio";
					reg = <0xc000>;
					gpio-controller;
					#gpio-cells = <0x02>;
					interrupt-controller;
					#interrupt-cells = <0x02>;
					phandle = <0x115>;
				};
			};

			pmic@5 {
				compatible = "qcom,pm8150l\0qcom,spmi-pmic";
				reg = <0x05 0x00>;
				#address-cells = <0x01>;
				#size-cells = <0x00>;
			};
		};

		pinctrl@f100000 {
			compatible = "qcom,sm8250-pinctrl";
			reg = <0x00 0xf100000 0x00 0x300000 0x00 0xf500000 0x00 0x300000 0x00 0xf900000 0x00 0x300000>;
			reg-names = "west\0south\0north";
			interrupts = <0x00 0xd0 0x04>;
			gpio-controller;
			#gpio-cells = <0x02>;
			interrupt-controller;
			#interrupt-cells = <0x02>;
			gpio-ranges = <0x3e 0x00 0x00 0xb5>;
			wakeup-parent = <0x58>;
			gpio-reserved-ranges = <0x1c 0x04 0x28 0x04>;
			phandle = <0x3e>;

			pri-mi2s-active {
				phandle = <0x116>;

				sclk {
					pins = "gpio138";
					function = "mi2s0_sck";
					drive-strength = <0x08>;
					bias-disable;
				};

				ws {
					pins = "gpio141";
					function = "mi2s0_ws";
					drive-strength = <0x08>;
					output-high;
				};

				data0 {
					pins = "gpio139";
					function = "mi2s0_data0";
					drive-strength = <0x08>;
					bias-disable;
					output-high;
				};

				data1 {
					pins = "gpio140";
					function = "mi2s0_data1";
					drive-strength = <0x08>;
					output-high;
				};
			};

			qup-i2c0-default {
				phandle = <0x29>;

				mux {
					pins = "gpio28\0gpio29";
					function = "qup0";
				};

				config {
					pins = "gpio28\0gpio29";
					drive-strength = <0x02>;
					bias-disable;
				};
			};

			qup-i2c1-default {
				phandle = <0x2b>;

				pinmux {
					pins = "gpio4\0gpio5";
					function = "qup1";
				};

				config {
					pins = "gpio4\0gpio5";
					drive-strength = <0x02>;
					bias-disable;
				};
			};

			qup-i2c2-default {
				phandle = <0x2c>;

				mux {
					pins = "gpio115\0gpio116";
					function = "qup2";
				};

				config {
					pins = "gpio115\0gpio116";
					drive-strength = <0x02>;
					bias-disable;
				};
			};

			qup-i2c3-default {
				phandle = <0x2e>;

				mux {
					pins = "gpio119\0gpio120";
					function = "qup3";
				};

				config {
					pins = "gpio119\0gpio120";
					drive-strength = <0x02>;
					bias-disable;
				};
			};

			qup-i2c4-default {
				phandle = <0x2f>;

				mux {
					pins = "gpio8\0gpio9";
					function = "qup4";
				};

				config {
					pins = "gpio8\0gpio9";
					drive-strength = <0x02>;
					bias-disable;
				};
			};

			qup-i2c5-default {
				phandle = <0x30>;

				mux {
					pins = "gpio12\0gpio13";
					function = "qup5";
				};

				config {
					pins = "gpio12\0gpio13";
					drive-strength = <0x02>;
					bias-disable;
				};
			};

			qup-i2c6-default {
				phandle = <0x31>;

				mux {
					pins = "gpio16\0gpio17";
					function = "qup6";
				};

				config {
					pins = "gpio16\0gpio17";
					drive-strength = <0x02>;
					bias-disable;
				};
			};

			qup-i2c7-default {
				phandle = <0x33>;

				mux {
					pins = "gpio20\0gpio21";
					function = "qup7";
				};

				config {
					pins = "gpio20\0gpio21";
					drive-strength = <0x02>;
					bias-disable;
				};
			};

			qup-i2c8-default {
				phandle = <0x34>;

				mux {
					pins = "gpio24\0gpio25";
					function = "qup8";
				};

				config {
					pins = "gpio24\0gpio25";
					drive-strength = <0x02>;
					bias-disable;
				};
			};

			qup-i2c9-default {
				phandle = <0x36>;

				mux {
					pins = "gpio125\0gpio126";
					function = "qup9";
				};

				config {
					pins = "gpio125\0gpio126";
					drive-strength = <0x02>;
					bias-disable;
				};
			};

			qup-i2c10-default {
				phandle = <0x37>;

				mux {
					pins = "gpio129\0gpio130";
					function = "qup10";
				};

				config {
					pins = "gpio129\0gpio130";
					drive-strength = <0x02>;
					bias-disable;
				};
			};

			qup-i2c11-default {
				phandle = <0x38>;

				mux {
					pins = "gpio60\0gpio61";
					function = "qup11";
				};

				config {
					pins = "gpio60\0gpio61";
					drive-strength = <0x02>;
					bias-disable;
				};
			};

			qup-i2c12-default {
				phandle = <0x39>;

				mux {
					pins = "gpio32\0gpio33";
					function = "qup12";
				};

				config {
					pins = "gpio32\0gpio33";
					drive-strength = <0x02>;
					bias-disable;
				};
			};

			qup-i2c13-default {
				phandle = <0x3b>;

				mux {
					pins = "gpio36\0gpio37";
					function = "qup13";
				};

				config {
					pins = "gpio36\0gpio37";
					drive-strength = <0x02>;
					bias-disable;
				};
			};

			qup-i2c14-default {
				phandle = <0x1f>;

				mux {
					pins = "gpio40\0gpio41";
					function = "qup14";
				};

				config {
					pins = "gpio40\0gpio41";
					drive-strength = <0x02>;
					bias-disable;
				};
			};

			qup-i2c15-default {
				phandle = <0x22>;

				mux {
					pins = "gpio44\0gpio45";
					function = "qup15";
				};

				config {
					pins = "gpio44\0gpio45";
					drive-strength = <0x02>;
					bias-disable;
				};
			};

			qup-i2c16-default {
				phandle = <0x23>;

				mux {
					pins = "gpio48\0gpio49";
					function = "qup16";
				};

				config {
					pins = "gpio48\0gpio49";
					drive-strength = <0x02>;
					bias-disable;
				};
			};

			qup-i2c17-default {
				phandle = <0x24>;

				mux {
					pins = "gpio52\0gpio53";
					function = "qup17";
				};

				config {
					pins = "gpio52\0gpio53";
					drive-strength = <0x02>;
					bias-disable;
				};
			};

			qup-i2c18-default {
				phandle = <0x26>;

				mux {
					pins = "gpio56\0gpio57";
					function = "qup18";
				};

				config {
					pins = "gpio56\0gpio57";
					drive-strength = <0x02>;
					bias-disable;
				};
			};

			qup-i2c19-default {
				phandle = <0x28>;

				mux {
					pins = "gpio0\0gpio1";
					function = "qup19";
				};

				config {
					pins = "gpio0\0gpio1";
					drive-strength = <0x02>;
					bias-disable;
				};
			};

			qup-spi0-cs {
				pins = "gpio31";
				function = "qup0";
				phandle = <0x117>;
			};

			qup-spi0-cs-gpio {
				pins = "gpio31";
				function = "gpio";
				phandle = <0x118>;
			};

			qup-spi0-data-clk {
				pins = "gpio28\0gpio29\0gpio30";
				function = "qup0";
				phandle = <0x119>;
			};

			qup-spi1-cs {
				pins = "gpio7";
				function = "qup1";
				phandle = <0x11a>;
			};

			qup-spi1-cs-gpio {
				pins = "gpio7";
				function = "gpio";
				phandle = <0x11b>;
			};

			qup-spi1-data-clk {
				pins = "gpio4\0gpio5\0gpio6";
				function = "qup1";
				phandle = <0x11c>;
			};

			qup-spi2-cs {
				pins = "gpio118";
				function = "qup2";
				phandle = <0x11d>;
			};

			qup-spi2-cs-gpio {
				pins = "gpio118";
				function = "gpio";
				phandle = <0x11e>;
			};

			qup-spi2-data-clk {
				pins = "gpio115\0gpio116\0gpio117";
				function = "qup2";
				phandle = <0x11f>;
			};

			qup-spi3-cs {
				pins = "gpio122";
				function = "qup3";
				phandle = <0x120>;
			};

			qup-spi3-cs-gpio {
				pins = "gpio122";
				function = "gpio";
				phandle = <0x121>;
			};

			qup-spi3-data-clk {
				pins = "gpio119\0gpio120\0gpio121";
				function = "qup3";
				phandle = <0x122>;
			};

			qup-spi4-cs {
				pins = "gpio11";
				function = "qup4";
				phandle = <0x123>;
			};

			qup-spi4-cs-gpio {
				pins = "gpio11";
				function = "gpio";
				phandle = <0x124>;
			};

			qup-spi4-data-clk {
				pins = "gpio8\0gpio9\0gpio10";
				function = "qup4";
				phandle = <0x125>;
			};

			qup-spi5-cs {
				pins = "gpio15";
				function = "qup5";
				phandle = <0x126>;
			};

			qup-spi5-cs-gpio {
				pins = "gpio15";
				function = "gpio";
				phandle = <0x127>;
			};

			qup-spi5-data-clk {
				pins = "gpio12\0gpio13\0gpio14";
				function = "qup5";
				phandle = <0x128>;
			};

			qup-spi6-cs {
				pins = "gpio19";
				function = "qup6";
				phandle = <0x129>;
			};

			qup-spi6-cs-gpio {
				pins = "gpio19";
				function = "gpio";
				phandle = <0x12a>;
			};

			qup-spi6-data-clk {
				pins = "gpio16\0gpio17\0gpio18";
				function = "qup6";
				phandle = <0x12b>;
			};

			qup-spi7-cs {
				pins = "gpio23";
				function = "qup7";
				phandle = <0x12c>;
			};

			qup-spi7-cs-gpio {
				pins = "gpio23";
				function = "gpio";
				phandle = <0x12d>;
			};

			qup-spi7-data-clk {
				pins = "gpio20\0gpio21\0gpio22";
				function = "qup7";
				phandle = <0x12e>;
			};

			qup-spi8-cs {
				pins = "gpio27";
				function = "qup8";
				phandle = <0x12f>;
			};

			qup-spi8-cs-gpio {
				pins = "gpio27";
				function = "gpio";
				phandle = <0x130>;
			};

			qup-spi8-data-clk {
				pins = "gpio24\0gpio25\0gpio26";
				function = "qup8";
				phandle = <0x131>;
			};

			qup-spi9-cs {
				pins = "gpio128";
				function = "qup9";
				phandle = <0x132>;
			};

			qup-spi9-cs-gpio {
				pins = "gpio128";
				function = "gpio";
				phandle = <0x133>;
			};

			qup-spi9-data-clk {
				pins = "gpio125\0gpio126\0gpio127";
				function = "qup9";
				phandle = <0x134>;
			};

			qup-spi10-cs {
				pins = "gpio132";
				function = "qup10";
				phandle = <0x135>;
			};

			qup-spi10-cs-gpio {
				pins = "gpio132";
				function = "gpio";
				phandle = <0x136>;
			};

			qup-spi10-data-clk {
				pins = "gpio129\0gpio130\0gpio131";
				function = "qup10";
				phandle = <0x137>;
			};

			qup-spi11-cs {
				pins = "gpio63";
				function = "qup11";
				phandle = <0x138>;
			};

			qup-spi11-cs-gpio {
				pins = "gpio63";
				function = "gpio";
				phandle = <0x139>;
			};

			qup-spi11-data-clk {
				pins = "gpio60\0gpio61\0gpio62";
				function = "qup11";
				phandle = <0x13a>;
			};

			qup-spi12-cs {
				pins = "gpio35";
				function = "qup12";
				phandle = <0x13b>;
			};

			qup-spi12-cs-gpio {
				pins = "gpio35";
				function = "gpio";
				phandle = <0x13c>;
			};

			qup-spi12-data-clk {
				pins = "gpio32\0gpio33\0gpio34";
				function = "qup12";
				phandle = <0x13d>;
			};

			qup-spi13-cs {
				pins = "gpio39";
				function = "qup13";
				phandle = <0x13e>;
			};

			qup-spi13-cs-gpio {
				pins = "gpio39";
				function = "gpio";
				phandle = <0x13f>;
			};

			qup-spi13-data-clk {
				pins = "gpio36\0gpio37\0gpio38";
				function = "qup13";
				phandle = <0x140>;
			};

			qup-spi14-cs {
				pins = "gpio43";
				function = "qup14";
				phandle = <0x141>;
			};

			qup-spi14-cs-gpio {
				pins = "gpio43";
				function = "gpio";
				phandle = <0x142>;
			};

			qup-spi14-data-clk {
				pins = "gpio40\0gpio41\0gpio42";
				function = "qup14";
				phandle = <0x143>;
			};

			qup-spi15-cs {
				pins = "gpio47";
				function = "qup15";
				phandle = <0x144>;
			};

			qup-spi15-cs-gpio {
				pins = "gpio47";
				function = "gpio";
				phandle = <0x145>;
			};

			qup-spi15-data-clk {
				pins = "gpio44\0gpio45\0gpio46";
				function = "qup15";
				phandle = <0x146>;
			};

			qup-spi16-cs {
				pins = "gpio51";
				function = "qup16";
				phandle = <0x147>;
			};

			qup-spi16-cs-gpio {
				pins = "gpio51";
				function = "gpio";
				phandle = <0x148>;
			};

			qup-spi16-data-clk {
				pins = "gpio48\0gpio49\0gpio50";
				function = "qup16";
				phandle = <0x149>;
			};

			qup-spi17-cs {
				pins = "gpio55";
				function = "qup17";
				phandle = <0x14a>;
			};

			qup-spi17-cs-gpio {
				pins = "gpio55";
				function = "gpio";
				phandle = <0x14b>;
			};

			qup-spi17-data-clk {
				pins = "gpio52\0gpio53\0gpio54";
				function = "qup17";
				phandle = <0x14c>;
			};

			qup-spi18-cs {
				pins = "gpio59";
				function = "qup18";
				phandle = <0x14d>;
			};

			qup-spi18-cs-gpio {
				pins = "gpio59";
				function = "gpio";
				phandle = <0x14e>;
			};

			qup-spi18-data-clk {
				pins = "gpio56\0gpio57\0gpio58";
				function = "qup18";
				phandle = <0x14f>;
			};

			qup-spi19-cs {
				pins = "gpio3";
				function = "qup19";
				phandle = <0x150>;
			};

			qup-spi19-cs-gpio {
				pins = "gpio3";
				function = "gpio";
				phandle = <0x151>;
			};

			qup-spi19-data-clk {
				pins = "gpio0\0gpio1\0gpio2";
				function = "qup19";
				phandle = <0x152>;
			};

			qup-uart2-default {
				phandle = <0x2d>;

				mux {
					pins = "gpio117\0gpio118";
					function = "qup2";
				};
			};

			qup-uart6-default {
				phandle = <0x32>;

				mux {
					pins = "gpio16\0gpio17\0gpio18\0gpio19";
					function = "qup6";
				};
			};

			qup-uart12-default {
				phandle = <0x3a>;

				mux {
					pins = "gpio34\0gpio35";
					function = "qup12";
				};
			};

			qup-uart17-default {
				phandle = <0x25>;

				mux {
					pins = "gpio52\0gpio53\0gpio54\0gpio55";
					function = "qup17";
				};
			};

			qup-uart18-default {
				phandle = <0x27>;

				mux {
					pins = "gpio58\0gpio59";
					function = "qup18";
				};
			};

			tert-mi2s-active {
				phandle = <0x153>;

				sck {
					pins = "gpio133";
					function = "mi2s2_sck";
					drive-strength = <0x08>;
					bias-disable;
				};

				data0 {
					pins = "gpio134";
					function = "mi2s2_data0";
					drive-strength = <0x08>;
					bias-disable;
					output-high;
				};

				ws {
					pins = "gpio135";
					function = "mi2s2_ws";
					drive-strength = <0x08>;
					output-high;
				};
			};

			sdc2-sleep {
				phandle = <0x154>;

				clk {
					pins = "sdc2_clk";
					drive-strength = <0x02>;
					bias-disable;
				};

				cmd {
					pins = "sdc2_cmd";
					drive-strength = <0x02>;
					bias-pull-up;
				};

				data {
					pins = "sdc2_data";
					drive-strength = <0x02>;
					bias-pull-up;
				};
			};

			pcie0-default {
				phandle = <0x3f>;

				perst {
					pins = "gpio79";
					function = "gpio";
					drive-strength = <0x02>;
					bias-pull-down;
				};

				clkreq {
					pins = "gpio80";
					function = "pci_e0";
					drive-strength = <0x02>;
					bias-pull-up;
				};

				wake {
					pins = "gpio81";
					function = "gpio";
					drive-strength = <0x02>;
					bias-pull-up;
				};
			};

			pcie1-default {
				phandle = <0x41>;

				perst {
					pins = "gpio82";
					function = "gpio";
					drive-strength = <0x02>;
					bias-pull-down;
				};

				clkreq {
					pins = "gpio83";
					function = "pci_e1";
					drive-strength = <0x02>;
					bias-pull-up;
				};

				wake {
					pins = "gpio84";
					function = "gpio";
					drive-strength = <0x02>;
					bias-pull-up;
				};
			};

			pcie2-default {
				phandle = <0x43>;

				perst {
					pins = "gpio85";
					function = "gpio";
					drive-strength = <0x02>;
					bias-pull-down;
				};

				clkreq {
					pins = "gpio86";
					function = "pci_e2";
					drive-strength = <0x02>;
					bias-pull-up;
				};

				wake {
					pins = "gpio87";
					function = "gpio";
					drive-strength = <0x02>;
					bias-pull-up;
				};
			};
		};

		iommu@15000000 {
			compatible = "qcom,sm8250-smmu-500\0arm,mmu-500";
			reg = <0x00 0x15000000 0x00 0x100000>;
			#iommu-cells = <0x02>;
			#global-interrupts = <0x02>;
			interrupts = <0x00 0x40 0x04 0x00 0x41 0x04 0x00 0x61 0x04 0x00 0x62 0x04 0x00 0x63 0x04 0x00 0x64 0x04 0x00 0x65 0x04 0x00 0x66 0x04 0x00 0x67 0x04 0x00 0x68 0x04 0x00 0x69 0x04 0x00 0x6a 0x04 0x00 0x6b 0x04 0x00 0x6c 0x04 0x00 0x6d 0x04 0x00 0x6e 0x04 0x00 0x6f 0x04 0x00 0x70 0x04 0x00 0x71 0x04 0x00 0x72 0x04 0x00 0x73 0x04 0x00 0x74 0x04 0x00 0x75 0x04 0x00 0x76 0x04 0x00 0xb5 0x04 0x00 0xb6 0x04 0x00 0xb7 0x04 0x00 0xb8 0x04 0x00 0xb9 0x04 0x00 0xba 0x04 0x00 0xbb 0x04 0x00 0xbc 0x04 0x00 0xbd 0x04 0x00 0xbe 0x04 0x00 0xbf 0x04 0x00 0xc0 0x04 0x00 0x13b 0x04 0x00 0x13c 0x04 0x00 0x13d 0x04 0x00 0x13e 0x04 0x00 0x13f 0x04 0x00 0x140 0x04 0x00 0x141 0x04 0x00 0x142 0x04 0x00 0x143 0x04 0x00 0x144 0x04 0x00 0x145 0x04 0x00 0x146 0x04 0x00 0x147 0x04 0x00 0x148 0x04 0x00 0x149 0x04 0x00 0x14a 0x04 0x00 0x14b 0x04 0x00 0x14c 0x04 0x00 0x14d 0x04 0x00 0x14e 0x04 0x00 0x14f 0x04 0x00 0x150 0x04 0x00 0x151 0x04 0x00 0x152 0x04 0x00 0x153 0x04 0x00 0x154 0x04 0x00 0x155 0x04 0x00 0x156 0x04 0x00 0x157 0x04 0x00 0x158 0x04 0x00 0x159 0x04 0x00 0x18b 0x04 0x00 0x18c 0x04 0x00 0x18d 0x04 0x00 0x18e 0x04 0x00 0x18f 0x04 0x00 0x190 0x04 0x00 0x191 0x04 0x00 0x192 0x04 0x00 0x193 0x04 0x00 0x194 0x04 0x00 0x195 0x04 0x00 0x196 0x04 0x00 0x197 0x04 0x00 0x198 0x04 0x00 0x199 0x04 0x00 0x19c 0x04 0x00 0x1a2 0x04 0x00 0x1a3 0x04 0x00 0x1a5 0x04 0x00 0x1a7 0x04 0x00 0x1a8 0x04 0x00 0x1a9 0x04 0x00 0x2b2 0x04 0x00 0x2b3 0x04 0x00 0x2b4 0x04 0x00 0x2b5 0x04 0x00 0x2b6 0x04 0x00 0x2b7 0x04 0x00 0x2b8 0x04 0x00 0x2b9 0x04 0x00 0x2c3 0x04>;
			phandle = <0x1e>;
		};

		remoteproc@17300000 {
			compatible = "qcom,sm8250-adsp-pas";
			reg = <0x00 0x17300000 0x00 0x100>;
			interrupts-extended = <0x58 0x06 0x04 0x80 0x00 0x01 0x80 0x01 0x01 0x80 0x02 0x01 0x80 0x03 0x01>;
			interrupt-names = "wdog\0fatal\0ready\0handover\0stop-ack";
			clocks = <0x19 0x00>;
			clock-names = "xo";
			power-domains = <0x5a 0x01 0x14 0x04 0x14 0x05>;
			power-domain-names = "load_state\0lcx\0lmx";
			memory-region = <0x81>;
			qcom,smem-states = <0x82 0x00>;
			qcom,smem-state-names = "stop";
			status = "disabled";
			phandle = <0x155>;

			glink-edge {
				interrupts-extended = <0x18 0x03 0x00 0x01>;
				mboxes = <0x18 0x03 0x00>;
				label = "lpass";
				qcom,remote-pid = <0x02>;

				apr {
					compatible = "qcom,apr-v2";
					qcom,glink-channels = "apr_audio_svc";
					qcom,apr-domain = <0x04>;
					#address-cells = <0x01>;
					#size-cells = <0x00>;

					apr-service@3 {
						reg = <0x03>;
						compatible = "qcom,q6core";
						qcom,protection-domain = "avs/audio\0msm/adsp/audio_pd";
					};

					apr-service@4 {
						compatible = "qcom,q6afe";
						reg = <0x04>;
						qcom,protection-domain = "avs/audio\0msm/adsp/audio_pd";
						phandle = <0x156>;

						dais {
							compatible = "qcom,q6afe-dais";
							#address-cells = <0x01>;
							#size-cells = <0x00>;
							#sound-dai-cells = <0x01>;
							phandle = <0x157>;
						};

						cc {
							compatible = "qcom,q6afe-clocks";
							#clock-cells = <0x02>;
							phandle = <0x4c>;
						};
					};

					apr-service@7 {
						compatible = "qcom,q6asm";
						reg = <0x07>;
						qcom,protection-domain = "avs/audio\0msm/adsp/audio_pd";
						phandle = <0x158>;

						dais {
							compatible = "qcom,q6asm-dais";
							#address-cells = <0x01>;
							#size-cells = <0x00>;
							#sound-dai-cells = <0x01>;
							iommus = <0x1e 0x1801 0x00>;
							phandle = <0x159>;
						};
					};

					apr-service@8 {
						compatible = "qcom,q6adm";
						reg = <0x08>;
						qcom,protection-domain = "avs/audio\0msm/adsp/audio_pd";
						phandle = <0x15a>;

						routing {
							compatible = "qcom,q6adm-routing";
							#sound-dai-cells = <0x00>;
							phandle = <0x15b>;
						};
					};
				};

				fastrpc {
					compatible = "qcom,fastrpc";
					qcom,glink-channels = "fastrpcglink-apps-dsp";
					label = "adsp";
					#address-cells = <0x01>;
					#size-cells = <0x00>;

					compute-cb@3 {
						compatible = "qcom,fastrpc-compute-cb";
						reg = <0x03>;
						iommus = <0x1e 0x1803 0x00>;
					};

					compute-cb@4 {
						compatible = "qcom,fastrpc-compute-cb";
						reg = <0x04>;
						iommus = <0x1e 0x1804 0x00>;
					};

					compute-cb@5 {
						compatible = "qcom,fastrpc-compute-cb";
						reg = <0x05>;
						iommus = <0x1e 0x1805 0x00>;
					};
				};
			};
		};

		interrupt-controller@17a00000 {
			compatible = "arm,gic-v3";
			#interrupt-cells = <0x03>;
			interrupt-controller;
			reg = <0x00 0x17a00000 0x00 0x10000 0x00 0x17a60000 0x00 0x100000>;
			interrupts = <0x01 0x09 0x04>;
			phandle = <0x01>;
		};

		watchdog@17c10000 {
			compatible = "qcom,apss-wdt-sm8250\0qcom,kpss-wdt";
			reg = <0x00 0x17c10000 0x00 0x1000>;
			clocks = <0x1a>;
			interrupts = <0x00 0x00 0x04>;
		};

		timer@17c20000 {
			#address-cells = <0x02>;
			#size-cells = <0x02>;
			ranges;
			compatible = "arm,armv7-timer-mem";
			reg = <0x00 0x17c20000 0x00 0x1000>;
			clock-frequency = <0x124f800>;

			frame@17c21000 {
				frame-number = <0x00>;
				interrupts = <0x00 0x08 0x04 0x00 0x06 0x04>;
				reg = <0x00 0x17c21000 0x00 0x1000 0x00 0x17c22000 0x00 0x1000>;
			};

			frame@17c23000 {
				frame-number = <0x01>;
				interrupts = <0x00 0x09 0x04>;
				reg = <0x00 0x17c23000 0x00 0x1000>;
				status = "disabled";
			};

			frame@17c25000 {
				frame-number = <0x02>;
				interrupts = <0x00 0x0a 0x04>;
				reg = <0x00 0x17c25000 0x00 0x1000>;
				status = "disabled";
			};

			frame@17c27000 {
				frame-number = <0x03>;
				interrupts = <0x00 0x0b 0x04>;
				reg = <0x00 0x17c27000 0x00 0x1000>;
				status = "disabled";
			};

			frame@17c29000 {
				frame-number = <0x04>;
				interrupts = <0x00 0x0c 0x04>;
				reg = <0x00 0x17c29000 0x00 0x1000>;
				status = "disabled";
			};

			frame@17c2b000 {
				frame-number = <0x05>;
				interrupts = <0x00 0x0d 0x04>;
				reg = <0x00 0x17c2b000 0x00 0x1000>;
				status = "disabled";
			};

			frame@17c2d000 {
				frame-number = <0x06>;
				interrupts = <0x00 0x0e 0x04>;
				reg = <0x00 0x17c2d000 0x00 0x1000>;
				status = "disabled";
			};
		};

		rsc@18200000 {
			label = "apps_rsc";
			compatible = "qcom,rpmh-rsc";
			reg = <0x00 0x18200000 0x00 0x10000 0x00 0x18210000 0x00 0x10000 0x00 0x18220000 0x00 0x10000>;
			reg-names = "drv-0\0drv-1\0drv-2";
			interrupts = <0x00 0x03 0x04 0x00 0x04 0x04 0x00 0x05 0x04>;
			qcom,tcs-offset = <0xd00>;
			qcom,drv-id = <0x02>;
			qcom,tcs-config = <0x02 0x02 0x00 0x03 0x01 0x03 0x03 0x01>;
			phandle = <0x15c>;

			clock-controller {
				compatible = "qcom,sm8250-rpmh-clk";
				#clock-cells = <0x01>;
				clock-names = "xo";
				clocks = <0x83>;
				phandle = <0x19>;
			};

			power-controller {
				compatible = "qcom,sm8250-rpmhpd";
				#power-domain-cells = <0x01>;
				operating-points-v2 = <0x84>;
				phandle = <0x14>;

				opp-table {
					compatible = "operating-points-v2";
					phandle = <0x84>;

					opp1 {
						opp-level = <0x10>;
						phandle = <0x15d>;
					};

					opp2 {
						opp-level = <0x30>;
						phandle = <0x1c>;
					};

					opp3 {
						opp-level = <0x40>;
						phandle = <0x15>;
					};

					opp4 {
						opp-level = <0x80>;
						phandle = <0x1d>;
					};

					opp5 {
						opp-level = <0xc0>;
						phandle = <0x64>;
					};

					opp6 {
						opp-level = <0x100>;
						phandle = <0x70>;
					};

					opp7 {
						opp-level = <0x140>;
						phandle = <0x15e>;
					};

					opp8 {
						opp-level = <0x150>;
						phandle = <0x15f>;
					};

					opp9 {
						opp-level = <0x180>;
						phandle = <0x160>;
					};

					opp10 {
						opp-level = <0x1a0>;
						phandle = <0x161>;
					};
				};
			};

			bcm_voter {
				compatible = "qcom,bcm-voter";
				phandle = <0x3c>;
			};

			pm8150-rpmh-regulators {
				compatible = "qcom,pm8150-rpmh-regulators";
				qcom,pmic-id = "a";
				vdd-s1-supply = <0x85>;
				vdd-s2-supply = <0x85>;
				vdd-s3-supply = <0x85>;
				vdd-s4-supply = <0x85>;
				vdd-s5-supply = <0x85>;
				vdd-s6-supply = <0x85>;
				vdd-s7-supply = <0x85>;
				vdd-s8-supply = <0x85>;
				vdd-s9-supply = <0x85>;
				vdd-s10-supply = <0x85>;
				vdd-l1-l8-l11-supply = <0x86>;
				vdd-l2-l10-supply = <0x87>;
				vdd-l3-l4-l5-l18-supply = <0x88>;
				vdd-l6-l9-supply = <0x89>;
				vdd-l7-l12-l14-l15-supply = <0x8a>;
				vdd-l13-l16-l17-supply = <0x87>;

				smps5 {
					regulator-name = "vreg_s5a_1p9";
					regulator-min-microvolt = <0x1bd500>;
					regulator-max-microvolt = <0x1e8480>;
					regulator-initial-mode = <0x03>;
					phandle = <0x8a>;
				};

				smps6 {
					regulator-name = "vreg_s6a_0p95";
					regulator-min-microvolt = <0x927c0>;
					regulator-max-microvolt = <0x113640>;
					regulator-initial-mode = <0x03>;
					phandle = <0x88>;
				};

				ldo2 {
					regulator-name = "vreg_l2a_3p1";
					regulator-min-microvolt = <0x2ee000>;
					regulator-max-microvolt = <0x2ee000>;
					regulator-initial-mode = <0x03>;
					phandle = <0x60>;
				};

				ldo3 {
					regulator-name = "vreg_l3a_0p9";
					regulator-min-microvolt = <0xe2900>;
					regulator-max-microvolt = <0xe38a0>;
					regulator-initial-mode = <0x03>;
					phandle = <0x162>;
				};

				ldo5 {
					regulator-name = "vreg_l5a_0p88";
					regulator-min-microvolt = <0xd6d80>;
					regulator-max-microvolt = <0xd6d80>;
					regulator-initial-mode = <0x03>;
					phandle = <0x49>;
				};

				ldo6 {
					regulator-name = "vreg_l6a_1p2";
					regulator-min-microvolt = <0x124f80>;
					regulator-max-microvolt = <0x124f80>;
					regulator-initial-mode = <0x03>;
					phandle = <0x46>;
				};

				ldo7 {
					regulator-name = "vreg_l7a_1p7";
					regulator-min-microvolt = <0x1a0040>;
					regulator-max-microvolt = <0x1b7740>;
					regulator-initial-mode = <0x03>;
					phandle = <0x163>;
				};

				ldo9 {
					regulator-name = "vreg_l9a_1p2";
					regulator-min-microvolt = <0x124f80>;
					regulator-max-microvolt = <0x124f80>;
					regulator-initial-mode = <0x03>;
					phandle = <0x4a>;
				};

				ldo10 {
					regulator-name = "vreg_l10a_1p8";
					regulator-min-microvolt = <0x1b7740>;
					regulator-max-microvolt = <0x2d2a80>;
					regulator-initial-mode = <0x03>;
					phandle = <0x164>;
				};

				ldo12 {
					regulator-name = "vreg_l12a_1p8";
					regulator-min-microvolt = <0x1b7740>;
					regulator-max-microvolt = <0x1b7740>;
					regulator-initial-mode = <0x03>;
					phandle = <0x61>;
				};

				ldo13 {
					regulator-name = "vreg_l13a_ts_3p0";
					regulator-min-microvolt = <0x2de600>;
					regulator-max-microvolt = <0x2de600>;
					regulator-initial-mode = <0x03>;
					phandle = <0x165>;
				};

				ldo14 {
					regulator-name = "vreg_l14a_1p8";
					regulator-min-microvolt = <0x1b7740>;
					regulator-max-microvolt = <0x1cafc0>;
					regulator-initial-mode = <0x03>;
					phandle = <0x166>;
				};

				ldo15 {
					regulator-name = "vreg_l15a_1p8";
					regulator-min-microvolt = <0x1b7740>;
					regulator-max-microvolt = <0x1b7740>;
					regulator-initial-mode = <0x03>;
					phandle = <0x167>;
				};

				ldo16 {
					regulator-name = "vreg_l16a_3p3";
					regulator-min-microvolt = <0x2e2480>;
					regulator-max-microvolt = <0x326a40>;
					regulator-initial-mode = <0x03>;
					phandle = <0x168>;
				};

				ldo17 {
					regulator-name = "vreg_l17a_2p96";
					regulator-min-microvolt = <0x261600>;
					regulator-max-microvolt = <0x2de600>;
					regulator-initial-mode = <0x03>;
					phandle = <0x45>;
				};

				ldo18 {
					regulator-name = "vreg_l18a_0p92";
					regulator-min-microvolt = "\0\f5";
					regulator-max-microvolt = <0xe09c0>;
					regulator-initial-mode = <0x03>;
					phandle = <0x62>;
				};
			};

			pm8150l-rpmh-regulators {
				compatible = "qcom,pm8150l-rpmh-regulators";
				qcom,pmic-id = "c";
				vdd-s1-supply = <0x85>;
				vdd-s2-supply = <0x85>;
				vdd-s3-supply = <0x85>;
				vdd-s4-supply = <0x85>;
				vdd-s5-supply = <0x85>;
				vdd-s6-supply = <0x85>;
				vdd-s7-supply = <0x85>;
				vdd-s8-supply = <0x85>;
				vdd-l1-l8-supply = <0x47>;
				vdd-l2-l3-supply = <0x89>;
				vdd-l4-l5-l6-supply = <0x87>;
				vdd-l7-l11-supply = <0x87>;
				vdd-l9-l10-supply = <0x87>;
				vdd-bob-supply = <0x85>;

				bob {
					regulator-name = "vreg_bob";
					regulator-min-microvolt = <0x2de600>;
					regulator-max-microvolt = <0x3c6cc0>;
					regulator-initial-mode = <0x02>;
					phandle = <0x87>;
				};

				smps8 {
					regulator-name = "vreg_s8c_1p3";
					regulator-min-microvolt = <0x124f80>;
					regulator-max-microvolt = <0x155cc0>;
					regulator-initial-mode = <0x03>;
					phandle = <0x89>;
				};

				ldo1 {
					regulator-name = "vreg_l1c_1p8";
					regulator-min-microvolt = <0x1b7740>;
					regulator-max-microvolt = <0x1b7740>;
					regulator-initial-mode = <0x03>;
					phandle = <0x169>;
				};

				ldo2 {
					regulator-name = "vreg_l2c_1p2";
					regulator-min-microvolt = <0x124f80>;
					regulator-max-microvolt = <0x13e5c0>;
					regulator-initial-mode = <0x03>;
					phandle = <0x16a>;
				};

				ldo3 {
					regulator-name = "vreg_l3c_0p8";
					regulator-min-microvolt = "\0\f5";
					regulator-max-microvolt = <0x124f80>;
					regulator-initial-mode = <0x03>;
					phandle = <0x16b>;
				};

				ldo4 {
					regulator-name = "vreg_l4c_1p8";
					regulator-min-microvolt = <0x1b7740>;
					regulator-max-microvolt = <0x2ab980>;
					regulator-initial-mode = <0x03>;
					phandle = <0x16c>;
				};

				ldo5 {
					regulator-name = "vreg_l5c_1p8";
					regulator-min-microvolt = <0x1b7740>;
					regulator-max-microvolt = <0x2ab980>;
					regulator-initial-mode = <0x03>;
					phandle = <0x16d>;
				};

				ldo6 {
					regulator-name = "vreg_l6c_2p96";
					regulator-min-microvolt = <0x1b7740>;
					regulator-max-microvolt = <0x2d2a80>;
					regulator-initial-mode = <0x03>;
					phandle = <0x16e>;
				};

				ldo7 {
					regulator-name = "vreg_l7c_cam_vcm0_2p85";
					regulator-min-microvolt = <0x2b9440>;
					regulator-max-microvolt = "\0/]";
					regulator-initial-mode = <0x03>;
					phandle = <0x16f>;
				};

				ldo8 {
					regulator-name = "vreg_l8c_1p8";
					regulator-min-microvolt = <0x1b7740>;
					regulator-max-microvolt = <0x1b7740>;
					regulator-initial-mode = <0x03>;
					phandle = <0x170>;
				};

				ldo9 {
					regulator-name = "vreg_l9c_2p96";
					regulator-min-microvolt = <0x294280>;
					regulator-max-microvolt = <0x2d2a80>;
					regulator-initial-mode = <0x03>;
					phandle = <0x171>;
				};

				ldo10 {
					regulator-name = "vreg_l10c_3p0";
					regulator-min-microvolt = <0x2dc6c0>;
					regulator-max-microvolt = <0x328980>;
					regulator-initial-mode = <0x03>;
					phandle = <0x172>;
				};

				ldo11 {
					regulator-name = "vreg_l11c_3p3";
					regulator-min-microvolt = "\0/]";
					regulator-max-microvolt = <0x328980>;
					regulator-initial-mode = <0x03>;
					phandle = <0x173>;
				};
			};

			pm8009-rpmh-regulators {
				compatible = "qcom,pm8009-rpmh-regulators";
				qcom,pmic-id = "f";
				vdd-s1-supply = <0x85>;
				vdd-s2-supply = <0x87>;
				vdd-l2-supply = <0x89>;
				vdd-l5-l6-supply = <0x87>;
				vdd-l7-supply = <0x47>;

				ldo1 {
					regulator-name = "vreg_l1f_cam_dvdd1_1p1";
					regulator-min-microvolt = <0x10d880>;
					regulator-max-microvolt = <0x10d880>;
					regulator-initial-mode = <0x03>;
					phandle = <0x174>;
				};

				ldo2 {
					regulator-name = "vreg_l2f_cam_dvdd0_1p2";
					regulator-min-microvolt = <0x124f80>;
					regulator-max-microvolt = <0x124f80>;
					regulator-initial-mode = <0x03>;
					phandle = <0x175>;
				};

				ldo3 {
					regulator-name = "vreg_l3f_cam_dvdd2_1p05";
					regulator-min-microvolt = <0x101d00>;
					regulator-max-microvolt = <0x101d00>;
					regulator-initial-mode = <0x03>;
					phandle = <0x176>;
				};

				ldo5 {
					regulator-name = "vreg_l5f_cam_avdd0_2p85";
					regulator-min-microvolt = <0x2ab980>;
					regulator-max-microvolt = <0x2dc6c0>;
					regulator-initial-mode = <0x03>;
					phandle = <0x177>;
				};

				ldo6 {
					regulator-name = "vreg_l6f_cam_avdd1_2p8";
					regulator-min-microvolt = <0x2ab980>;
					regulator-max-microvolt = <0x2dc6c0>;
					regulator-initial-mode = <0x03>;
					phandle = <0x178>;
				};

				ldo7 {
					regulator-name = "vreg_l7f_1p8";
					regulator-min-microvolt = <0x1b7740>;
					regulator-max-microvolt = <0x1b7740>;
					regulator-initial-mode = <0x03>;
					phandle = <0x179>;
				};
			};
		};

		interconnect@18590000 {
			compatible = "qcom,sm8250-epss-l3";
			reg = <0x00 0x18590000 0x00 0x1000>;
			clocks = <0x19 0x00 0x1b 0x00>;
			clock-names = "xo\0alternate";
			#interconnect-cells = <0x01>;
			phandle = <0x17a>;
		};

		cpufreq@18591000 {
			compatible = "qcom,sm8250-cpufreq-epss\0qcom,cpufreq-epss";
			reg = <0x00 0x18591000 0x00 0x1000 0x00 0x18592000 0x00 0x1000 0x00 0x18593000 0x00 0x1000>;
			reg-names = "freq-domain0\0freq-domain1\0freq-domain2";
			clocks = <0x19 0x00 0x1b 0x00>;
			clock-names = "xo\0alternate";
			#freq-domain-cells = <0x01>;
			phandle = <0x03>;
		};
	};

	timer {
		compatible = "arm,armv8-timer";
		interrupts = <0x01 0x0d 0xff08 0x01 0x0e 0xff08 0x01 0x0b 0xff08 0x01 0x0a 0xff08>;
	};

	thermal-zones {

		cpu0-thermal {
			polling-delay-passive = <0xfa>;
			polling-delay = <0x3e8>;
			thermal-sensors = <0x8b 0x01>;

			trips {

				trip-point0 {
					temperature = <0x15f90>;
					hysteresis = <0x7d0>;
					type = "passive";
					phandle = <0x8c>;
				};

				trip-point1 {
					temperature = <0x17318>;
					hysteresis = <0x7d0>;
					type = "passive";
					phandle = <0x8d>;
				};

				cpu_crit {
					temperature = <0x1adb0>;
					hysteresis = <0x3e8>;
					type = "critical";
					phandle = <0x17b>;
				};
			};

			cooling-maps {

				map0 {
					trip = <0x8c>;
					cooling-device = <0x0c 0xffffffff 0xffffffff 0x0d 0xffffffff 0xffffffff 0x0e 0xffffffff 0xffffffff 0x0f 0xffffffff 0xffffffff>;
				};

				map1 {
					trip = <0x8d>;
					cooling-device = <0x0c 0xffffffff 0xffffffff 0x0d 0xffffffff 0xffffffff 0x0e 0xffffffff 0xffffffff 0x0f 0xffffffff 0xffffffff>;
				};
			};
		};

		cpu1-thermal {
			polling-delay-passive = <0xfa>;
			polling-delay = <0x3e8>;
			thermal-sensors = <0x8b 0x02>;

			trips {

				trip-point0 {
					temperature = <0x15f90>;
					hysteresis = <0x7d0>;
					type = "passive";
					phandle = <0x8e>;
				};

				trip-point1 {
					temperature = <0x17318>;
					hysteresis = <0x7d0>;
					type = "passive";
					phandle = <0x8f>;
				};

				cpu_crit {
					temperature = <0x1adb0>;
					hysteresis = <0x3e8>;
					type = "critical";
					phandle = <0x17c>;
				};
			};

			cooling-maps {

				map0 {
					trip = <0x8e>;
					cooling-device = <0x0c 0xffffffff 0xffffffff 0x0d 0xffffffff 0xffffffff 0x0e 0xffffffff 0xffffffff 0x0f 0xffffffff 0xffffffff>;
				};

				map1 {
					trip = <0x8f>;
					cooling-device = <0x0c 0xffffffff 0xffffffff 0x0d 0xffffffff 0xffffffff 0x0e 0xffffffff 0xffffffff 0x0f 0xffffffff 0xffffffff>;
				};
			};
		};

		cpu2-thermal {
			polling-delay-passive = <0xfa>;
			polling-delay = <0x3e8>;
			thermal-sensors = <0x8b 0x03>;

			trips {

				trip-point0 {
					temperature = <0x15f90>;
					hysteresis = <0x7d0>;
					type = "passive";
					phandle = <0x90>;
				};

				trip-point1 {
					temperature = <0x17318>;
					hysteresis = <0x7d0>;
					type = "passive";
					phandle = <0x91>;
				};

				cpu_crit {
					temperature = <0x1adb0>;
					hysteresis = <0x3e8>;
					type = "critical";
					phandle = <0x17d>;
				};
			};

			cooling-maps {

				map0 {
					trip = <0x90>;
					cooling-device = <0x0c 0xffffffff 0xffffffff 0x0d 0xffffffff 0xffffffff 0x0e 0xffffffff 0xffffffff 0x0f 0xffffffff 0xffffffff>;
				};

				map1 {
					trip = <0x91>;
					cooling-device = <0x0c 0xffffffff 0xffffffff 0x0d 0xffffffff 0xffffffff 0x0e 0xffffffff 0xffffffff 0x0f 0xffffffff 0xffffffff>;
				};
			};
		};

		cpu3-thermal {
			polling-delay-passive = <0xfa>;
			polling-delay = <0x3e8>;
			thermal-sensors = <0x8b 0x04>;

			trips {

				trip-point0 {
					temperature = <0x15f90>;
					hysteresis = <0x7d0>;
					type = "passive";
					phandle = <0x92>;
				};

				trip-point1 {
					temperature = <0x17318>;
					hysteresis = <0x7d0>;
					type = "passive";
					phandle = <0x93>;
				};

				cpu_crit {
					temperature = <0x1adb0>;
					hysteresis = <0x3e8>;
					type = "critical";
					phandle = <0x17e>;
				};
			};

			cooling-maps {

				map0 {
					trip = <0x92>;
					cooling-device = <0x0c 0xffffffff 0xffffffff 0x0d 0xffffffff 0xffffffff 0x0e 0xffffffff 0xffffffff 0x0f 0xffffffff 0xffffffff>;
				};

				map1 {
					trip = <0x93>;
					cooling-device = <0x0c 0xffffffff 0xffffffff 0x0d 0xffffffff 0xffffffff 0x0e 0xffffffff 0xffffffff 0x0f 0xffffffff 0xffffffff>;
				};
			};
		};

		cpu4-top-thermal {
			polling-delay-passive = <0xfa>;
			polling-delay = <0x3e8>;
			thermal-sensors = <0x8b 0x07>;

			trips {

				trip-point0 {
					temperature = <0x15f90>;
					hysteresis = <0x7d0>;
					type = "passive";
					phandle = <0x94>;
				};

				trip-point1 {
					temperature = <0x17318>;
					hysteresis = <0x7d0>;
					type = "passive";
					phandle = <0x95>;
				};

				cpu_crit {
					temperature = <0x1adb0>;
					hysteresis = <0x3e8>;
					type = "critical";
					phandle = <0x17f>;
				};
			};

			cooling-maps {

				map0 {
					trip = <0x94>;
					cooling-device = <0x10 0xffffffff 0xffffffff 0x11 0xffffffff 0xffffffff 0x12 0xffffffff 0xffffffff 0x13 0xffffffff 0xffffffff>;
				};

				map1 {
					trip = <0x95>;
					cooling-device = <0x10 0xffffffff 0xffffffff 0x11 0xffffffff 0xffffffff 0x12 0xffffffff 0xffffffff 0x13 0xffffffff 0xffffffff>;
				};
			};
		};

		cpu5-top-thermal {
			polling-delay-passive = <0xfa>;
			polling-delay = <0x3e8>;
			thermal-sensors = <0x8b 0x08>;

			trips {

				trip-point0 {
					temperature = <0x15f90>;
					hysteresis = <0x7d0>;
					type = "passive";
					phandle = <0x96>;
				};

				trip-point1 {
					temperature = <0x17318>;
					hysteresis = <0x7d0>;
					type = "passive";
					phandle = <0x97>;
				};

				cpu_crit {
					temperature = <0x1adb0>;
					hysteresis = <0x3e8>;
					type = "critical";
					phandle = <0x180>;
				};
			};

			cooling-maps {

				map0 {
					trip = <0x96>;
					cooling-device = <0x10 0xffffffff 0xffffffff 0x11 0xffffffff 0xffffffff 0x12 0xffffffff 0xffffffff 0x13 0xffffffff 0xffffffff>;
				};

				map1 {
					trip = <0x97>;
					cooling-device = <0x10 0xffffffff 0xffffffff 0x11 0xffffffff 0xffffffff 0x12 0xffffffff 0xffffffff 0x13 0xffffffff 0xffffffff>;
				};
			};
		};

		cpu6-top-thermal {
			polling-delay-passive = <0xfa>;
			polling-delay = <0x3e8>;
			thermal-sensors = <0x8b 0x09>;

			trips {

				trip-point0 {
					temperature = <0x15f90>;
					hysteresis = <0x7d0>;
					type = "passive";
					phandle = <0x98>;
				};

				trip-point1 {
					temperature = <0x17318>;
					hysteresis = <0x7d0>;
					type = "passive";
					phandle = <0x99>;
				};

				cpu_crit {
					temperature = <0x1adb0>;
					hysteresis = <0x3e8>;
					type = "critical";
					phandle = <0x181>;
				};
			};

			cooling-maps {

				map0 {
					trip = <0x98>;
					cooling-device = <0x10 0xffffffff 0xffffffff 0x11 0xffffffff 0xffffffff 0x12 0xffffffff 0xffffffff 0x13 0xffffffff 0xffffffff>;
				};

				map1 {
					trip = <0x99>;
					cooling-device = <0x10 0xffffffff 0xffffffff 0x11 0xffffffff 0xffffffff 0x12 0xffffffff 0xffffffff 0x13 0xffffffff 0xffffffff>;
				};
			};
		};

		cpu7-top-thermal {
			polling-delay-passive = <0xfa>;
			polling-delay = <0x3e8>;
			thermal-sensors = <0x8b 0x0a>;

			trips {

				trip-point0 {
					temperature = <0x15f90>;
					hysteresis = <0x7d0>;
					type = "passive";
					phandle = <0x9a>;
				};

				trip-point1 {
					temperature = <0x17318>;
					hysteresis = <0x7d0>;
					type = "passive";
					phandle = <0x9b>;
				};

				cpu_crit {
					temperature = <0x1adb0>;
					hysteresis = <0x3e8>;
					type = "critical";
					phandle = <0x182>;
				};
			};

			cooling-maps {

				map0 {
					trip = <0x9a>;
					cooling-device = <0x10 0xffffffff 0xffffffff 0x11 0xffffffff 0xffffffff 0x12 0xffffffff 0xffffffff 0x13 0xffffffff 0xffffffff>;
				};

				map1 {
					trip = <0x9b>;
					cooling-device = <0x10 0xffffffff 0xffffffff 0x11 0xffffffff 0xffffffff 0x12 0xffffffff 0xffffffff 0x13 0xffffffff 0xffffffff>;
				};
			};
		};

		cpu4-bottom-thermal {
			polling-delay-passive = <0xfa>;
			polling-delay = <0x3e8>;
			thermal-sensors = <0x8b 0x0b>;

			trips {

				trip-point0 {
					temperature = <0x15f90>;
					hysteresis = <0x7d0>;
					type = "passive";
					phandle = <0x9c>;
				};

				trip-point1 {
					temperature = <0x17318>;
					hysteresis = <0x7d0>;
					type = "passive";
					phandle = <0x9d>;
				};

				cpu_crit {
					temperature = <0x1adb0>;
					hysteresis = <0x3e8>;
					type = "critical";
					phandle = <0x183>;
				};
			};

			cooling-maps {

				map0 {
					trip = <0x9c>;
					cooling-device = <0x10 0xffffffff 0xffffffff 0x11 0xffffffff 0xffffffff 0x12 0xffffffff 0xffffffff 0x13 0xffffffff 0xffffffff>;
				};

				map1 {
					trip = <0x9d>;
					cooling-device = <0x10 0xffffffff 0xffffffff 0x11 0xffffffff 0xffffffff 0x12 0xffffffff 0xffffffff 0x13 0xffffffff 0xffffffff>;
				};
			};
		};

		cpu5-bottom-thermal {
			polling-delay-passive = <0xfa>;
			polling-delay = <0x3e8>;
			thermal-sensors = <0x8b 0x0c>;

			trips {

				trip-point0 {
					temperature = <0x15f90>;
					hysteresis = <0x7d0>;
					type = "passive";
					phandle = <0x9e>;
				};

				trip-point1 {
					temperature = <0x17318>;
					hysteresis = <0x7d0>;
					type = "passive";
					phandle = <0x9f>;
				};

				cpu_crit {
					temperature = <0x1adb0>;
					hysteresis = <0x3e8>;
					type = "critical";
					phandle = <0x184>;
				};
			};

			cooling-maps {

				map0 {
					trip = <0x9e>;
					cooling-device = <0x10 0xffffffff 0xffffffff 0x11 0xffffffff 0xffffffff 0x12 0xffffffff 0xffffffff 0x13 0xffffffff 0xffffffff>;
				};

				map1 {
					trip = <0x9f>;
					cooling-device = <0x10 0xffffffff 0xffffffff 0x11 0xffffffff 0xffffffff 0x12 0xffffffff 0xffffffff 0x13 0xffffffff 0xffffffff>;
				};
			};
		};

		cpu6-bottom-thermal {
			polling-delay-passive = <0xfa>;
			polling-delay = <0x3e8>;
			thermal-sensors = <0x8b 0x0d>;

			trips {

				trip-point0 {
					temperature = <0x15f90>;
					hysteresis = <0x7d0>;
					type = "passive";
					phandle = <0xa0>;
				};

				trip-point1 {
					temperature = <0x17318>;
					hysteresis = <0x7d0>;
					type = "passive";
					phandle = <0xa1>;
				};

				cpu_crit {
					temperature = <0x1adb0>;
					hysteresis = <0x3e8>;
					type = "critical";
					phandle = <0x185>;
				};
			};

			cooling-maps {

				map0 {
					trip = <0xa0>;
					cooling-device = <0x10 0xffffffff 0xffffffff 0x11 0xffffffff 0xffffffff 0x12 0xffffffff 0xffffffff 0x13 0xffffffff 0xffffffff>;
				};

				map1 {
					trip = <0xa1>;
					cooling-device = <0x10 0xffffffff 0xffffffff 0x11 0xffffffff 0xffffffff 0x12 0xffffffff 0xffffffff 0x13 0xffffffff 0xffffffff>;
				};
			};
		};

		cpu7-bottom-thermal {
			polling-delay-passive = <0xfa>;
			polling-delay = <0x3e8>;
			thermal-sensors = <0x8b 0x0e>;

			trips {

				trip-point0 {
					temperature = <0x15f90>;
					hysteresis = <0x7d0>;
					type = "passive";
					phandle = <0xa2>;
				};

				trip-point1 {
					temperature = <0x17318>;
					hysteresis = <0x7d0>;
					type = "passive";
					phandle = <0xa3>;
				};

				cpu_crit {
					temperature = <0x1adb0>;
					hysteresis = <0x3e8>;
					type = "critical";
					phandle = <0x186>;
				};
			};

			cooling-maps {

				map0 {
					trip = <0xa2>;
					cooling-device = <0x10 0xffffffff 0xffffffff 0x11 0xffffffff 0xffffffff 0x12 0xffffffff 0xffffffff 0x13 0xffffffff 0xffffffff>;
				};

				map1 {
					trip = <0xa3>;
					cooling-device = <0x10 0xffffffff 0xffffffff 0x11 0xffffffff 0xffffffff 0x12 0xffffffff 0xffffffff 0x13 0xffffffff 0xffffffff>;
				};
			};
		};

		aoss0-thermal {
			polling-delay-passive = <0xfa>;
			polling-delay = <0x3e8>;
			thermal-sensors = <0x8b 0x00>;

			trips {

				trip-point0 {
					temperature = <0x15f90>;
					hysteresis = <0x7d0>;
					type = "hot";
					phandle = <0x187>;
				};
			};
		};

		cluster0-thermal {
			polling-delay-passive = <0xfa>;
			polling-delay = <0x3e8>;
			thermal-sensors = <0x8b 0x05>;

			trips {

				trip-point0 {
					temperature = <0x15f90>;
					hysteresis = <0x7d0>;
					type = "hot";
					phandle = <0x188>;
				};

				cluster0_crit {
					temperature = <0x1adb0>;
					hysteresis = <0x7d0>;
					type = "critical";
					phandle = <0x189>;
				};
			};
		};

		cluster1-thermal {
			polling-delay-passive = <0xfa>;
			polling-delay = <0x3e8>;
			thermal-sensors = <0x8b 0x06>;

			trips {

				trip-point0 {
					temperature = <0x15f90>;
					hysteresis = <0x7d0>;
					type = "hot";
					phandle = <0x18a>;
				};

				cluster1_crit {
					temperature = <0x1adb0>;
					hysteresis = <0x7d0>;
					type = "critical";
					phandle = <0x18b>;
				};
			};
		};

		gpu-thermal-top {
			polling-delay-passive = <0xfa>;
			polling-delay = <0x3e8>;
			thermal-sensors = <0x8b 0x0f>;

			trips {

				trip-point0 {
					temperature = <0x15f90>;
					hysteresis = <0x7d0>;
					type = "hot";
					phandle = <0x18c>;
				};
			};
		};

		aoss1-thermal {
			polling-delay-passive = <0xfa>;
			polling-delay = <0x3e8>;
			thermal-sensors = <0xa4 0x00>;

			trips {

				trip-point0 {
					temperature = <0x15f90>;
					hysteresis = <0x7d0>;
					type = "hot";
					phandle = <0x18d>;
				};
			};
		};

		wlan-thermal {
			polling-delay-passive = <0xfa>;
			polling-delay = <0x3e8>;
			thermal-sensors = <0xa4 0x01>;

			trips {

				trip-point0 {
					temperature = <0x15f90>;
					hysteresis = <0x7d0>;
					type = "hot";
					phandle = <0x18e>;
				};
			};
		};

		video-thermal {
			polling-delay-passive = <0xfa>;
			polling-delay = <0x3e8>;
			thermal-sensors = <0xa4 0x02>;

			trips {

				trip-point0 {
					temperature = <0x15f90>;
					hysteresis = <0x7d0>;
					type = "hot";
					phandle = <0x18f>;
				};
			};
		};

		mem-thermal {
			polling-delay-passive = <0xfa>;
			polling-delay = <0x3e8>;
			thermal-sensors = <0xa4 0x03>;

			trips {

				trip-point0 {
					temperature = <0x15f90>;
					hysteresis = <0x7d0>;
					type = "hot";
					phandle = <0x190>;
				};
			};
		};

		q6-hvx-thermal {
			polling-delay-passive = <0xfa>;
			polling-delay = <0x3e8>;
			thermal-sensors = <0xa4 0x04>;

			trips {

				trip-point0 {
					temperature = <0x15f90>;
					hysteresis = <0x7d0>;
					type = "hot";
					phandle = <0x191>;
				};
			};
		};

		camera-thermal {
			polling-delay-passive = <0xfa>;
			polling-delay = <0x3e8>;
			thermal-sensors = <0xa4 0x05>;

			trips {

				trip-point0 {
					temperature = <0x15f90>;
					hysteresis = <0x7d0>;
					type = "hot";
					phandle = <0x192>;
				};
			};
		};

		compute-thermal {
			polling-delay-passive = <0xfa>;
			polling-delay = <0x3e8>;
			thermal-sensors = <0xa4 0x06>;

			trips {

				trip-point0 {
					temperature = <0x15f90>;
					hysteresis = <0x7d0>;
					type = "hot";
					phandle = <0x193>;
				};
			};
		};

		npu-thermal {
			polling-delay-passive = <0xfa>;
			polling-delay = <0x3e8>;
			thermal-sensors = <0xa4 0x07>;

			trips {

				trip-point0 {
					temperature = <0x15f90>;
					hysteresis = <0x7d0>;
					type = "hot";
					phandle = <0x194>;
				};
			};
		};

		gpu-thermal-bottom {
			polling-delay-passive = <0xfa>;
			polling-delay = <0x3e8>;
			thermal-sensors = <0xa4 0x08>;

			trips {

				trip-point0 {
					temperature = <0x15f90>;
					hysteresis = <0x7d0>;
					type = "hot";
					phandle = <0x195>;
				};
			};
		};

		pm8150-thermal {
			polling-delay-passive = <0x64>;
			polling-delay = <0x00>;
			thermal-sensors = <0xa5>;

			trips {

				trip0 {
					temperature = <0x17318>;
					hysteresis = <0x00>;
					type = "passive";
				};

				trip1 {
					temperature = <0x1c138>;
					hysteresis = <0x00>;
					type = "hot";
				};

				trip2 {
					temperature = <0x23668>;
					hysteresis = <0x00>;
					type = "critical";
				};
			};
		};

		pm8150b-thermal {
			polling-delay-passive = <0x64>;
			polling-delay = <0x00>;
			thermal-sensors = <0xa6>;

			trips {

				trip0 {
					temperature = <0x17318>;
					hysteresis = <0x00>;
					type = "passive";
				};

				trip1 {
					temperature = <0x1c138>;
					hysteresis = <0x00>;
					type = "hot";
				};

				trip2 {
					temperature = <0x23668>;
					hysteresis = <0x00>;
					type = "critical";
				};
			};
		};

		pm8150l-thermal {
			polling-delay-passive = <0x64>;
			polling-delay = <0x00>;
			thermal-sensors = <0xa7>;

			trips {

				trip0 {
					temperature = <0x17318>;
					hysteresis = <0x00>;
					type = "passive";
				};

				trip1 {
					temperature = <0x1c138>;
					hysteresis = <0x00>;
					type = "hot";
				};

				trip2 {
					temperature = <0x23668>;
					hysteresis = <0x00>;
					type = "critical";
				};
			};
		};
	};

	vph-pwr-regulator {
		compatible = "regulator-fixed";
		regulator-name = "vph_pwr";
		regulator-min-microvolt = <0x387520>;
		regulator-max-microvolt = <0x387520>;
		phandle = <0x85>;
	};

	pm8150-s4 {
		compatible = "regulator-fixed";
		regulator-name = "vreg_s4a_1p8";
		regulator-min-microvolt = <0x1b7740>;
		regulator-max-microvolt = <0x1b7740>;
		regulator-always-on;
		regulator-boot-on;
		vin-supply = <0x85>;
		phandle = <0x47>;
	};

	smpc6-regulator {
		compatible = "regulator-fixed";
		regulator-name = "vreg_s6c_0p88";
		regulator-min-microvolt = <0xd6d80>;
		regulator-max-microvolt = <0xd6d80>;
		regulator-always-on;
		vin-supply = <0x85>;
		phandle = <0x86>;
	};

	gpio_keys {
		compatible = "gpio-keys";

		vol-up {
			label = "Volume Up";
			linux,code = <0x73>;
			gpios = <0xa8 0x06 0x01>;
		};
	};

	__symbols__ {
		xo_board = "/clocks/xo-board";
		sleep_clk = "/clocks/sleep-clk";
		CPU0 = "/cpus/cpu@0";
		L2_0 = "/cpus/cpu@0/l2-cache";
		L3_0 = "/cpus/cpu@0/l2-cache/l3-cache";
		CPU1 = "/cpus/cpu@100";
		L2_100 = "/cpus/cpu@100/l2-cache";
		CPU2 = "/cpus/cpu@200";
		L2_200 = "/cpus/cpu@200/l2-cache";
		CPU3 = "/cpus/cpu@300";
		L2_300 = "/cpus/cpu@300/l2-cache";
		CPU4 = "/cpus/cpu@400";
		L2_400 = "/cpus/cpu@400/l2-cache";
		CPU5 = "/cpus/cpu@500";
		L2_500 = "/cpus/cpu@500/l2-cache";
		CPU6 = "/cpus/cpu@600";
		L2_600 = "/cpus/cpu@600/l2-cache";
		CPU7 = "/cpus/cpu@700";
		L2_700 = "/cpus/cpu@700/l2-cache";
		scm = "/firmware/scm";
		mmcx_reg = "/mmcx-reg";
		hyp_mem = "/reserved-memory/memory@80000000";
		xbl_aop_mem = "/reserved-memory/memory@80700000";
		cmd_db = "/reserved-memory/memory@80860000";
		smem_mem = "/reserved-memory/memory@80900000";
		removed_mem = "/reserved-memory/memory@80b00000";
		camera_mem = "/reserved-memory/memory@86200000";
		wlan_mem = "/reserved-memory/memory@86700000";
		ipa_fw_mem = "/reserved-memory/memory@86800000";
		ipa_gsi_mem = "/reserved-memory/memory@86810000";
		gpu_mem = "/reserved-memory/memory@8681a000";
		npu_mem = "/reserved-memory/memory@86900000";
		video_mem = "/reserved-memory/memory@86e00000";
		cvp_mem = "/reserved-memory/memory@87300000";
		cdsp_mem = "/reserved-memory/memory@87800000";
		slpi_mem = "/reserved-memory/memory@88c00000";
		adsp_mem = "/reserved-memory/memory@8a100000";
		spss_mem = "/reserved-memory/memory@8be00000";
		cdsp_secure_heap = "/reserved-memory/memory@8bf00000";
		smp2p_adsp_out = "/smp2p-adsp/master-kernel";
		smp2p_adsp_in = "/smp2p-adsp/slave-kernel";
		smp2p_cdsp_out = "/smp2p-cdsp/master-kernel";
		smp2p_cdsp_in = "/smp2p-cdsp/slave-kernel";
		smp2p_slpi_out = "/smp2p-slpi/master-kernel";
		smp2p_slpi_in = "/smp2p-slpi/slave-kernel";
		soc = "/soc@0";
		gcc = "/soc@0/clock-controller@100000";
		ipcc = "/soc@0/mailbox@408000";
		rng = "/soc@0/rng@793000";
		qup_opp_table = "/soc@0/qup-opp-table";
		gpi_dma2 = "/soc@0/dma-controller@800000";
		qupv3_id_2 = "/soc@0/geniqup@8c0000";
		i2c14 = "/soc@0/geniqup@8c0000/i2c@880000";
		spi14 = "/soc@0/geniqup@8c0000/spi@880000";
		i2c15 = "/soc@0/geniqup@8c0000/i2c@884000";
		spi15 = "/soc@0/geniqup@8c0000/spi@884000";
		i2c16 = "/soc@0/geniqup@8c0000/i2c@888000";
		spi16 = "/soc@0/geniqup@8c0000/spi@888000";
		i2c17 = "/soc@0/geniqup@8c0000/i2c@88c000";
		spi17 = "/soc@0/geniqup@8c0000/spi@88c000";
		uart17 = "/soc@0/geniqup@8c0000/serial@88c000";
		i2c18 = "/soc@0/geniqup@8c0000/i2c@890000";
		spi18 = "/soc@0/geniqup@8c0000/spi@890000";
		uart18 = "/soc@0/geniqup@8c0000/serial@890000";
		i2c19 = "/soc@0/geniqup@8c0000/i2c@894000";
		spi19 = "/soc@0/geniqup@8c0000/spi@894000";
		gpi_dma0 = "/soc@0/dma-controller@900000";
		qupv3_id_0 = "/soc@0/geniqup@9c0000";
		i2c0 = "/soc@0/geniqup@9c0000/i2c@980000";
		spi0 = "/soc@0/geniqup@9c0000/spi@980000";
		i2c1 = "/soc@0/geniqup@9c0000/i2c@984000";
		spi1 = "/soc@0/geniqup@9c0000/spi@984000";
		i2c2 = "/soc@0/geniqup@9c0000/i2c@988000";
		spi2 = "/soc@0/geniqup@9c0000/spi@988000";
		uart2 = "/soc@0/geniqup@9c0000/serial@988000";
		i2c3 = "/soc@0/geniqup@9c0000/i2c@98c000";
		spi3 = "/soc@0/geniqup@9c0000/spi@98c000";
		i2c4 = "/soc@0/geniqup@9c0000/i2c@990000";
		spi4 = "/soc@0/geniqup@9c0000/spi@990000";
		i2c5 = "/soc@0/geniqup@9c0000/i2c@994000";
		spi5 = "/soc@0/geniqup@9c0000/spi@994000";
		i2c6 = "/soc@0/geniqup@9c0000/i2c@998000";
		spi6 = "/soc@0/geniqup@9c0000/spi@998000";
		uart6 = "/soc@0/geniqup@9c0000/serial@998000";
		i2c7 = "/soc@0/geniqup@9c0000/i2c@99c000";
		spi7 = "/soc@0/geniqup@9c0000/spi@99c000";
		gpi_dma1 = "/soc@0/dma-controller@a00000";
		qupv3_id_1 = "/soc@0/geniqup@ac0000";
		i2c8 = "/soc@0/geniqup@ac0000/i2c@a80000";
		spi8 = "/soc@0/geniqup@ac0000/spi@a80000";
		i2c9 = "/soc@0/geniqup@ac0000/i2c@a84000";
		spi9 = "/soc@0/geniqup@ac0000/spi@a84000";
		i2c10 = "/soc@0/geniqup@ac0000/i2c@a88000";
		spi10 = "/soc@0/geniqup@ac0000/spi@a88000";
		i2c11 = "/soc@0/geniqup@ac0000/i2c@a8c000";
		spi11 = "/soc@0/geniqup@ac0000/spi@a8c000";
		i2c12 = "/soc@0/geniqup@ac0000/i2c@a90000";
		spi12 = "/soc@0/geniqup@ac0000/spi@a90000";
		uart12 = "/soc@0/geniqup@ac0000/serial@a90000";
		i2c13 = "/soc@0/geniqup@ac0000/i2c@a94000";
		spi13 = "/soc@0/geniqup@ac0000/spi@a94000";
		config_noc = "/soc@0/interconnect@1500000";
		system_noc = "/soc@0/interconnect@1620000";
		mc_virt = "/soc@0/interconnect@163d000";
		aggre1_noc = "/soc@0/interconnect@16e0000";
		aggre2_noc = "/soc@0/interconnect@1700000";
		compute_noc = "/soc@0/interconnect@1733000";
		mmss_noc = "/soc@0/interconnect@1740000";
		pcie0 = "/soc@0/pci@1c00000";
		pcie0_phy = "/soc@0/phy@1c06000";
		pcie0_lane = "/soc@0/phy@1c06000/phy@1c06200";
		pcie1 = "/soc@0/pci@1c08000";
		pcie1_phy = "/soc@0/phy@1c0e000";
		pcie1_lane = "/soc@0/phy@1c0e000/phy@1c0e200";
		pcie2 = "/soc@0/pci@1c10000";
		pcie2_phy = "/soc@0/phy@1c16000";
		pcie2_lane = "/soc@0/phy@1c16000/phy@1c16200";
		ufs_mem_hc = "/soc@0/ufshc@1d84000";
		ufs_mem_phy = "/soc@0/phy@1d87000";
		ufs_mem_phy_lanes = "/soc@0/phy@1d87000/phy@1d87400";
		ipa_virt = "/soc@0/interconnect@1e00000";
		tcsr_mutex = "/soc@0/hwlock@1f40000";
		wsamacro = "/soc@0/codec@3240000";
		swr0 = "/soc@0/soundwire-controller@3250000";
		audiocc = "/soc@0/clock-controller@3300000";
		vamacro = "/soc@0/codec@3370000";
		aoncc = "/soc@0/clock-controller@3380000";
		lpass_tlmm = "/soc@0/pinctrl@33c0000";
		wsa_swr_active = "/soc@0/pinctrl@33c0000/wsa-swr-active-pins";
		wsa_swr_sleep = "/soc@0/pinctrl@33c0000/wsa-swr-sleep-pins";
		dmic01_active = "/soc@0/pinctrl@33c0000/dmic01-active-pins";
		dmic01_sleep = "/soc@0/pinctrl@33c0000/dmic01-sleep-pins";
		gpu = "/soc@0/gpu@3d00000";
		gpu_opp_table = "/soc@0/gpu@3d00000/opp-table";
		gmu = "/soc@0/gmu@3d6a000";
		gmu_opp_table = "/soc@0/gmu@3d6a000/opp-table";
		gpucc = "/soc@0/clock-controller@3d90000";
		adreno_smmu = "/soc@0/iommu@3da0000";
		slpi = "/soc@0/remoteproc@5c00000";
		cdsp = "/soc@0/remoteproc@8300000";
		sound = "/soc@0/sound";
		usb_1_hsphy = "/soc@0/phy@88e3000";
		usb_2_hsphy = "/soc@0/phy@88e4000";
		usb_1_qmpphy = "/soc@0/phy@88e9000";
		usb_1_ssphy = "/soc@0/phy@88e9000/usb3-phy@88e9200";
		dp_phy = "/soc@0/phy@88e9000/dp-phy@88ea200";
		usb_2_qmpphy = "/soc@0/phy@88eb000";
		usb_2_ssphy = "/soc@0/phy@88eb000/phy@88eb200";
		sdhc_2 = "/soc@0/sdhci@8804000";
		sdhc2_opp_table = "/soc@0/sdhci@8804000/sdhc2-opp-table";
		dc_noc = "/soc@0/interconnect@90c0000";
		gem_noc = "/soc@0/interconnect@9100000";
		npu_noc = "/soc@0/interconnect@9990000";
		usb_1 = "/soc@0/usb@a6f8800";
		usb_1_dwc3 = "/soc@0/usb@a6f8800/usb@a600000";
		usb_2 = "/soc@0/usb@a8f8800";
		usb_2_dwc3 = "/soc@0/usb@a8f8800/usb@a800000";
		venus = "/soc@0/video-codec@aa00000";
		venus_opp_table = "/soc@0/video-codec@aa00000/venus-opp-table";
		videocc = "/soc@0/clock-controller@abf0000";
		mdss = "/soc@0/mdss@ae00000";
		mdss_mdp = "/soc@0/mdss@ae00000/mdp@ae01000";
		dpu_intf1_out = "/soc@0/mdss@ae00000/mdp@ae01000/ports/port@0/endpoint";
		dpu_intf2_out = "/soc@0/mdss@ae00000/mdp@ae01000/ports/port@1/endpoint";
		mdp_opp_table = "/soc@0/mdss@ae00000/mdp@ae01000/mdp-opp-table";
		dsi0 = "/soc@0/mdss@ae00000/dsi@ae94000";
		dsi0_in = "/soc@0/mdss@ae00000/dsi@ae94000/ports/port@0/endpoint";
		dsi0_out = "/soc@0/mdss@ae00000/dsi@ae94000/ports/port@1/endpoint";
		dsi0_phy = "/soc@0/mdss@ae00000/dsi-phy@ae94400";
		dsi1 = "/soc@0/mdss@ae00000/dsi@ae96000";
		dsi1_in = "/soc@0/mdss@ae00000/dsi@ae96000/ports/port@0/endpoint";
		dsi1_out = "/soc@0/mdss@ae00000/dsi@ae96000/ports/port@1/endpoint";
		dsi1_phy = "/soc@0/mdss@ae00000/dsi-phy@ae96400";
		dsi_opp_table = "/soc@0/mdss@ae00000/dsi-phy@ae96400/dsi-opp-table";
		dispcc = "/soc@0/clock-controller@af00000";
		pdc = "/soc@0/interrupt-controller@b220000";
		tsens0 = "/soc@0/thermal-sensor@c263000";
		tsens1 = "/soc@0/thermal-sensor@c265000";
		aoss_qmp = "/soc@0/power-controller@c300000";
		spmi_bus = "/soc@0/spmi@c440000";
		pm8150_0 = "/soc@0/spmi@c440000/pmic@0";
		pon = "/soc@0/spmi@c440000/pmic@0/power-on@800";
		pon_pwrkey = "/soc@0/spmi@c440000/pmic@0/power-on@800/pwrkey";
		pon_resin = "/soc@0/spmi@c440000/pmic@0/power-on@800/resin";
		pm8150_temp = "/soc@0/spmi@c440000/pmic@0/temp-alarm@2400";
		pm8150_adc = "/soc@0/spmi@c440000/pmic@0/adc@3100";
		pm8150_adc_tm = "/soc@0/spmi@c440000/pmic@0/adc-tm@3500";
		pm8150_gpios = "/soc@0/spmi@c440000/pmic@0/gpio@c000";
		pm8150b_vbus = "/soc@0/spmi@c440000/pmic@2/dcdc@1100";
		pm8150b_temp = "/soc@0/spmi@c440000/pmic@2/temp-alarm@2400";
		pm8150b_adc = "/soc@0/spmi@c440000/pmic@2/adc@3100";
		pm8150b_adc_tm = "/soc@0/spmi@c440000/pmic@2/adc-tm@3500";
		pm8150b_gpios = "/soc@0/spmi@c440000/pmic@2/gpio@c000";
		pm8150l_temp = "/soc@0/spmi@c440000/pmic@4/temp-alarm@2400";
		pm8150l_adc = "/soc@0/spmi@c440000/pmic@4/adc@3100";
		pm8150l_adc_tm = "/soc@0/spmi@c440000/pmic@4/adc-tm@3500";
		pm8150l_gpios = "/soc@0/spmi@c440000/pmic@4/gpio@c000";
		tlmm = "/soc@0/pinctrl@f100000";
		pri_mi2s_active = "/soc@0/pinctrl@f100000/pri-mi2s-active";
		qup_i2c0_default = "/soc@0/pinctrl@f100000/qup-i2c0-default";
		qup_i2c1_default = "/soc@0/pinctrl@f100000/qup-i2c1-default";
		qup_i2c2_default = "/soc@0/pinctrl@f100000/qup-i2c2-default";
		qup_i2c3_default = "/soc@0/pinctrl@f100000/qup-i2c3-default";
		qup_i2c4_default = "/soc@0/pinctrl@f100000/qup-i2c4-default";
		qup_i2c5_default = "/soc@0/pinctrl@f100000/qup-i2c5-default";
		qup_i2c6_default = "/soc@0/pinctrl@f100000/qup-i2c6-default";
		qup_i2c7_default = "/soc@0/pinctrl@f100000/qup-i2c7-default";
		qup_i2c8_default = "/soc@0/pinctrl@f100000/qup-i2c8-default";
		qup_i2c9_default = "/soc@0/pinctrl@f100000/qup-i2c9-default";
		qup_i2c10_default = "/soc@0/pinctrl@f100000/qup-i2c10-default";
		qup_i2c11_default = "/soc@0/pinctrl@f100000/qup-i2c11-default";
		qup_i2c12_default = "/soc@0/pinctrl@f100000/qup-i2c12-default";
		qup_i2c13_default = "/soc@0/pinctrl@f100000/qup-i2c13-default";
		qup_i2c14_default = "/soc@0/pinctrl@f100000/qup-i2c14-default";
		qup_i2c15_default = "/soc@0/pinctrl@f100000/qup-i2c15-default";
		qup_i2c16_default = "/soc@0/pinctrl@f100000/qup-i2c16-default";
		qup_i2c17_default = "/soc@0/pinctrl@f100000/qup-i2c17-default";
		qup_i2c18_default = "/soc@0/pinctrl@f100000/qup-i2c18-default";
		qup_i2c19_default = "/soc@0/pinctrl@f100000/qup-i2c19-default";
		qup_spi0_cs = "/soc@0/pinctrl@f100000/qup-spi0-cs";
		qup_spi0_cs_gpio = "/soc@0/pinctrl@f100000/qup-spi0-cs-gpio";
		qup_spi0_data_clk = "/soc@0/pinctrl@f100000/qup-spi0-data-clk";
		qup_spi1_cs = "/soc@0/pinctrl@f100000/qup-spi1-cs";
		qup_spi1_cs_gpio = "/soc@0/pinctrl@f100000/qup-spi1-cs-gpio";
		qup_spi1_data_clk = "/soc@0/pinctrl@f100000/qup-spi1-data-clk";
		qup_spi2_cs = "/soc@0/pinctrl@f100000/qup-spi2-cs";
		qup_spi2_cs_gpio = "/soc@0/pinctrl@f100000/qup-spi2-cs-gpio";
		qup_spi2_data_clk = "/soc@0/pinctrl@f100000/qup-spi2-data-clk";
		qup_spi3_cs = "/soc@0/pinctrl@f100000/qup-spi3-cs";
		qup_spi3_cs_gpio = "/soc@0/pinctrl@f100000/qup-spi3-cs-gpio";
		qup_spi3_data_clk = "/soc@0/pinctrl@f100000/qup-spi3-data-clk";
		qup_spi4_cs = "/soc@0/pinctrl@f100000/qup-spi4-cs";
		qup_spi4_cs_gpio = "/soc@0/pinctrl@f100000/qup-spi4-cs-gpio";
		qup_spi4_data_clk = "/soc@0/pinctrl@f100000/qup-spi4-data-clk";
		qup_spi5_cs = "/soc@0/pinctrl@f100000/qup-spi5-cs";
		qup_spi5_cs_gpio = "/soc@0/pinctrl@f100000/qup-spi5-cs-gpio";
		qup_spi5_data_clk = "/soc@0/pinctrl@f100000/qup-spi5-data-clk";
		qup_spi6_cs = "/soc@0/pinctrl@f100000/qup-spi6-cs";
		qup_spi6_cs_gpio = "/soc@0/pinctrl@f100000/qup-spi6-cs-gpio";
		qup_spi6_data_clk = "/soc@0/pinctrl@f100000/qup-spi6-data-clk";
		qup_spi7_cs = "/soc@0/pinctrl@f100000/qup-spi7-cs";
		qup_spi7_cs_gpio = "/soc@0/pinctrl@f100000/qup-spi7-cs-gpio";
		qup_spi7_data_clk = "/soc@0/pinctrl@f100000/qup-spi7-data-clk";
		qup_spi8_cs = "/soc@0/pinctrl@f100000/qup-spi8-cs";
		qup_spi8_cs_gpio = "/soc@0/pinctrl@f100000/qup-spi8-cs-gpio";
		qup_spi8_data_clk = "/soc@0/pinctrl@f100000/qup-spi8-data-clk";
		qup_spi9_cs = "/soc@0/pinctrl@f100000/qup-spi9-cs";
		qup_spi9_cs_gpio = "/soc@0/pinctrl@f100000/qup-spi9-cs-gpio";
		qup_spi9_data_clk = "/soc@0/pinctrl@f100000/qup-spi9-data-clk";
		qup_spi10_cs = "/soc@0/pinctrl@f100000/qup-spi10-cs";
		qup_spi10_cs_gpio = "/soc@0/pinctrl@f100000/qup-spi10-cs-gpio";
		qup_spi10_data_clk = "/soc@0/pinctrl@f100000/qup-spi10-data-clk";
		qup_spi11_cs = "/soc@0/pinctrl@f100000/qup-spi11-cs";
		qup_spi11_cs_gpio = "/soc@0/pinctrl@f100000/qup-spi11-cs-gpio";
		qup_spi11_data_clk = "/soc@0/pinctrl@f100000/qup-spi11-data-clk";
		qup_spi12_cs = "/soc@0/pinctrl@f100000/qup-spi12-cs";
		qup_spi12_cs_gpio = "/soc@0/pinctrl@f100000/qup-spi12-cs-gpio";
		qup_spi12_data_clk = "/soc@0/pinctrl@f100000/qup-spi12-data-clk";
		qup_spi13_cs = "/soc@0/pinctrl@f100000/qup-spi13-cs";
		qup_spi13_cs_gpio = "/soc@0/pinctrl@f100000/qup-spi13-cs-gpio";
		qup_spi13_data_clk = "/soc@0/pinctrl@f100000/qup-spi13-data-clk";
		qup_spi14_cs = "/soc@0/pinctrl@f100000/qup-spi14-cs";
		qup_spi14_cs_gpio = "/soc@0/pinctrl@f100000/qup-spi14-cs-gpio";
		qup_spi14_data_clk = "/soc@0/pinctrl@f100000/qup-spi14-data-clk";
		qup_spi15_cs = "/soc@0/pinctrl@f100000/qup-spi15-cs";
		qup_spi15_cs_gpio = "/soc@0/pinctrl@f100000/qup-spi15-cs-gpio";
		qup_spi15_data_clk = "/soc@0/pinctrl@f100000/qup-spi15-data-clk";
		qup_spi16_cs = "/soc@0/pinctrl@f100000/qup-spi16-cs";
		qup_spi16_cs_gpio = "/soc@0/pinctrl@f100000/qup-spi16-cs-gpio";
		qup_spi16_data_clk = "/soc@0/pinctrl@f100000/qup-spi16-data-clk";
		qup_spi17_cs = "/soc@0/pinctrl@f100000/qup-spi17-cs";
		qup_spi17_cs_gpio = "/soc@0/pinctrl@f100000/qup-spi17-cs-gpio";
		qup_spi17_data_clk = "/soc@0/pinctrl@f100000/qup-spi17-data-clk";
		qup_spi18_cs = "/soc@0/pinctrl@f100000/qup-spi18-cs";
		qup_spi18_cs_gpio = "/soc@0/pinctrl@f100000/qup-spi18-cs-gpio";
		qup_spi18_data_clk = "/soc@0/pinctrl@f100000/qup-spi18-data-clk";
		qup_spi19_cs = "/soc@0/pinctrl@f100000/qup-spi19-cs";
		qup_spi19_cs_gpio = "/soc@0/pinctrl@f100000/qup-spi19-cs-gpio";
		qup_spi19_data_clk = "/soc@0/pinctrl@f100000/qup-spi19-data-clk";
		qup_uart2_default = "/soc@0/pinctrl@f100000/qup-uart2-default";
		qup_uart6_default = "/soc@0/pinctrl@f100000/qup-uart6-default";
		qup_uart12_default = "/soc@0/pinctrl@f100000/qup-uart12-default";
		qup_uart17_default = "/soc@0/pinctrl@f100000/qup-uart17-default";
		qup_uart18_default = "/soc@0/pinctrl@f100000/qup-uart18-default";
		tert_mi2s_active = "/soc@0/pinctrl@f100000/tert-mi2s-active";
		sdc2_sleep_state = "/soc@0/pinctrl@f100000/sdc2-sleep";
		pcie0_default_state = "/soc@0/pinctrl@f100000/pcie0-default";
		pcie1_default_state = "/soc@0/pinctrl@f100000/pcie1-default";
		pcie2_default_state = "/soc@0/pinctrl@f100000/pcie2-default";
		apps_smmu = "/soc@0/iommu@15000000";
		adsp = "/soc@0/remoteproc@17300000";
		q6afe = "/soc@0/remoteproc@17300000/glink-edge/apr/apr-service@4";
		q6afedai = "/soc@0/remoteproc@17300000/glink-edge/apr/apr-service@4/dais";
		q6afecc = "/soc@0/remoteproc@17300000/glink-edge/apr/apr-service@4/cc";
		q6asm = "/soc@0/remoteproc@17300000/glink-edge/apr/apr-service@7";
		q6asmdai = "/soc@0/remoteproc@17300000/glink-edge/apr/apr-service@7/dais";
		q6adm = "/soc@0/remoteproc@17300000/glink-edge/apr/apr-service@8";
		q6routing = "/soc@0/remoteproc@17300000/glink-edge/apr/apr-service@8/routing";
		intc = "/soc@0/interrupt-controller@17a00000";
		apps_rsc = "/soc@0/rsc@18200000";
		rpmhcc = "/soc@0/rsc@18200000/clock-controller";
		rpmhpd = "/soc@0/rsc@18200000/power-controller";
		rpmhpd_opp_table = "/soc@0/rsc@18200000/power-controller/opp-table";
		rpmhpd_opp_ret = "/soc@0/rsc@18200000/power-controller/opp-table/opp1";
		rpmhpd_opp_min_svs = "/soc@0/rsc@18200000/power-controller/opp-table/opp2";
		rpmhpd_opp_low_svs = "/soc@0/rsc@18200000/power-controller/opp-table/opp3";
		rpmhpd_opp_svs = "/soc@0/rsc@18200000/power-controller/opp-table/opp4";
		rpmhpd_opp_svs_l1 = "/soc@0/rsc@18200000/power-controller/opp-table/opp5";
		rpmhpd_opp_nom = "/soc@0/rsc@18200000/power-controller/opp-table/opp6";
		rpmhpd_opp_nom_l1 = "/soc@0/rsc@18200000/power-controller/opp-table/opp7";
		rpmhpd_opp_nom_l2 = "/soc@0/rsc@18200000/power-controller/opp-table/opp8";
		rpmhpd_opp_turbo = "/soc@0/rsc@18200000/power-controller/opp-table/opp9";
		rpmhpd_opp_turbo_l1 = "/soc@0/rsc@18200000/power-controller/opp-table/opp10";
		apps_bcm_voter = "/soc@0/rsc@18200000/bcm_voter";
		vreg_s5a_1p9 = "/soc@0/rsc@18200000/pm8150-rpmh-regulators/smps5";
		vreg_s6a_0p95 = "/soc@0/rsc@18200000/pm8150-rpmh-regulators/smps6";
		vreg_l2a_3p1 = "/soc@0/rsc@18200000/pm8150-rpmh-regulators/ldo2";
		vreg_l3a_0p9 = "/soc@0/rsc@18200000/pm8150-rpmh-regulators/ldo3";
		vreg_l5a_0p88 = "/soc@0/rsc@18200000/pm8150-rpmh-regulators/ldo5";
		vreg_l6a_1p2 = "/soc@0/rsc@18200000/pm8150-rpmh-regulators/ldo6";
		vreg_l7a_1p7 = "/soc@0/rsc@18200000/pm8150-rpmh-regulators/ldo7";
		vreg_l9a_1p2 = "/soc@0/rsc@18200000/pm8150-rpmh-regulators/ldo9";
		vreg_l10a_1p8 = "/soc@0/rsc@18200000/pm8150-rpmh-regulators/ldo10";
		vreg_l12a_1p8 = "/soc@0/rsc@18200000/pm8150-rpmh-regulators/ldo12";
		vreg_l13a_ts_3p0 = "/soc@0/rsc@18200000/pm8150-rpmh-regulators/ldo13";
		vreg_l14a_1p8 = "/soc@0/rsc@18200000/pm8150-rpmh-regulators/ldo14";
		vreg_l15a_1p8 = "/soc@0/rsc@18200000/pm8150-rpmh-regulators/ldo15";
		vreg_l16a_3p3 = "/soc@0/rsc@18200000/pm8150-rpmh-regulators/ldo16";
		vreg_l17a_2p96 = "/soc@0/rsc@18200000/pm8150-rpmh-regulators/ldo17";
		vreg_l18a_0p92 = "/soc@0/rsc@18200000/pm8150-rpmh-regulators/ldo18";
		vreg_bob = "/soc@0/rsc@18200000/pm8150l-rpmh-regulators/bob";
		vreg_s8c_1p3 = "/soc@0/rsc@18200000/pm8150l-rpmh-regulators/smps8";
		vreg_l1c_1p8 = "/soc@0/rsc@18200000/pm8150l-rpmh-regulators/ldo1";
		vreg_l2c_1p2 = "/soc@0/rsc@18200000/pm8150l-rpmh-regulators/ldo2";
		vreg_l3c_0p8 = "/soc@0/rsc@18200000/pm8150l-rpmh-regulators/ldo3";
		vreg_l4c_1p8 = "/soc@0/rsc@18200000/pm8150l-rpmh-regulators/ldo4";
		vreg_l5c_1p8 = "/soc@0/rsc@18200000/pm8150l-rpmh-regulators/ldo5";
		vreg_l6c_2p96 = "/soc@0/rsc@18200000/pm8150l-rpmh-regulators/ldo6";
		vreg_l7c_cam_vcm0_2p85 = "/soc@0/rsc@18200000/pm8150l-rpmh-regulators/ldo7";
		vreg_l8c_1p8 = "/soc@0/rsc@18200000/pm8150l-rpmh-regulators/ldo8";
		vreg_l9c_2p96 = "/soc@0/rsc@18200000/pm8150l-rpmh-regulators/ldo9";
		vreg_l10c_3p0 = "/soc@0/rsc@18200000/pm8150l-rpmh-regulators/ldo10";
		vreg_l11c_3p3 = "/soc@0/rsc@18200000/pm8150l-rpmh-regulators/ldo11";
		vreg_l1f_cam_dvdd1_1p1 = "/soc@0/rsc@18200000/pm8009-rpmh-regulators/ldo1";
		vreg_l2f_cam_dvdd0_1p2 = "/soc@0/rsc@18200000/pm8009-rpmh-regulators/ldo2";
		vreg_l3f_cam_dvdd2_1p05 = "/soc@0/rsc@18200000/pm8009-rpmh-regulators/ldo3";
		vreg_l5f_cam_avdd0_2p85 = "/soc@0/rsc@18200000/pm8009-rpmh-regulators/ldo5";
		vreg_l6f_cam_avdd1_2p8 = "/soc@0/rsc@18200000/pm8009-rpmh-regulators/ldo6";
		vreg_l7f_1p8 = "/soc@0/rsc@18200000/pm8009-rpmh-regulators/ldo7";
		epss_l3 = "/soc@0/interconnect@18590000";
		cpufreq_hw = "/soc@0/cpufreq@18591000";
		cpu0_alert0 = "/thermal-zones/cpu0-thermal/trips/trip-point0";
		cpu0_alert1 = "/thermal-zones/cpu0-thermal/trips/trip-point1";
		cpu0_crit = "/thermal-zones/cpu0-thermal/trips/cpu_crit";
		cpu1_alert0 = "/thermal-zones/cpu1-thermal/trips/trip-point0";
		cpu1_alert1 = "/thermal-zones/cpu1-thermal/trips/trip-point1";
		cpu1_crit = "/thermal-zones/cpu1-thermal/trips/cpu_crit";
		cpu2_alert0 = "/thermal-zones/cpu2-thermal/trips/trip-point0";
		cpu2_alert1 = "/thermal-zones/cpu2-thermal/trips/trip-point1";
		cpu2_crit = "/thermal-zones/cpu2-thermal/trips/cpu_crit";
		cpu3_alert0 = "/thermal-zones/cpu3-thermal/trips/trip-point0";
		cpu3_alert1 = "/thermal-zones/cpu3-thermal/trips/trip-point1";
		cpu3_crit = "/thermal-zones/cpu3-thermal/trips/cpu_crit";
		cpu4_top_alert0 = "/thermal-zones/cpu4-top-thermal/trips/trip-point0";
		cpu4_top_alert1 = "/thermal-zones/cpu4-top-thermal/trips/trip-point1";
		cpu4_top_crit = "/thermal-zones/cpu4-top-thermal/trips/cpu_crit";
		cpu5_top_alert0 = "/thermal-zones/cpu5-top-thermal/trips/trip-point0";
		cpu5_top_alert1 = "/thermal-zones/cpu5-top-thermal/trips/trip-point1";
		cpu5_top_crit = "/thermal-zones/cpu5-top-thermal/trips/cpu_crit";
		cpu6_top_alert0 = "/thermal-zones/cpu6-top-thermal/trips/trip-point0";
		cpu6_top_alert1 = "/thermal-zones/cpu6-top-thermal/trips/trip-point1";
		cpu6_top_crit = "/thermal-zones/cpu6-top-thermal/trips/cpu_crit";
		cpu7_top_alert0 = "/thermal-zones/cpu7-top-thermal/trips/trip-point0";
		cpu7_top_alert1 = "/thermal-zones/cpu7-top-thermal/trips/trip-point1";
		cpu7_top_crit = "/thermal-zones/cpu7-top-thermal/trips/cpu_crit";
		cpu4_bottom_alert0 = "/thermal-zones/cpu4-bottom-thermal/trips/trip-point0";
		cpu4_bottom_alert1 = "/thermal-zones/cpu4-bottom-thermal/trips/trip-point1";
		cpu4_bottom_crit = "/thermal-zones/cpu4-bottom-thermal/trips/cpu_crit";
		cpu5_bottom_alert0 = "/thermal-zones/cpu5-bottom-thermal/trips/trip-point0";
		cpu5_bottom_alert1 = "/thermal-zones/cpu5-bottom-thermal/trips/trip-point1";
		cpu5_bottom_crit = "/thermal-zones/cpu5-bottom-thermal/trips/cpu_crit";
		cpu6_bottom_alert0 = "/thermal-zones/cpu6-bottom-thermal/trips/trip-point0";
		cpu6_bottom_alert1 = "/thermal-zones/cpu6-bottom-thermal/trips/trip-point1";
		cpu6_bottom_crit = "/thermal-zones/cpu6-bottom-thermal/trips/cpu_crit";
		cpu7_bottom_alert0 = "/thermal-zones/cpu7-bottom-thermal/trips/trip-point0";
		cpu7_bottom_alert1 = "/thermal-zones/cpu7-bottom-thermal/trips/trip-point1";
		cpu7_bottom_crit = "/thermal-zones/cpu7-bottom-thermal/trips/cpu_crit";
		aoss0_alert0 = "/thermal-zones/aoss0-thermal/trips/trip-point0";
		cluster0_alert0 = "/thermal-zones/cluster0-thermal/trips/trip-point0";
		cluster0_crit = "/thermal-zones/cluster0-thermal/trips/cluster0_crit";
		cluster1_alert0 = "/thermal-zones/cluster1-thermal/trips/trip-point0";
		cluster1_crit = "/thermal-zones/cluster1-thermal/trips/cluster1_crit";
		gpu1_alert0 = "/thermal-zones/gpu-thermal-top/trips/trip-point0";
		aoss1_alert0 = "/thermal-zones/aoss1-thermal/trips/trip-point0";
		wlan_alert0 = "/thermal-zones/wlan-thermal/trips/trip-point0";
		video_alert0 = "/thermal-zones/video-thermal/trips/trip-point0";
		mem_alert0 = "/thermal-zones/mem-thermal/trips/trip-point0";
		q6_hvx_alert0 = "/thermal-zones/q6-hvx-thermal/trips/trip-point0";
		camera_alert0 = "/thermal-zones/camera-thermal/trips/trip-point0";
		compute_alert0 = "/thermal-zones/compute-thermal/trips/trip-point0";
		npu_alert0 = "/thermal-zones/npu-thermal/trips/trip-point0";
		gpu2_alert0 = "/thermal-zones/gpu-thermal-bottom/trips/trip-point0";
		vph_pwr = "/vph-pwr-regulator";
		vreg_s4a_1p8 = "/pm8150-s4";
		vreg_s6c_0p88 = "/smpc6-regulator";
	};
};
